VERSION ""

NS_ :

BS_:

BU_: TCM HCM IPMA_ADAS PSCM ABS_ESC TCCM TCM_DSL PCM_HEV PCM ECM_HEVDSL ECM_HEV ECM_Diesel ECM SIMA_DLCS BCMD_IPDB VDM CMR_DSMC SOBDMC_HPCM CHCM GWM _delete AWD_DLCM GENERIC TSTR

BO_ 963 BCM_Lamp_Stat_FD1: 8 BCM
 SG_ Illuminated_Entry_Stat : 63|2@0+ (1,0) [0|3] "SED"  GENERIC
 SG_ Dr_Courtesy_Light_Stat : 49|2@0+ (1,0) [0|3] "SED"  GENERIC
 SG_ Courtesy_Delay_Status : 51|2@0+ (1,0) [0|3] "SED"  GENERIC
 SG_ ImpactEvntFdbck_D_Stat : 53|2@0+ (1,0) [0|3] "SED"  CMR_DSMC
 SG_ WrlssAcsyChrgInhbt_B_Rq : 40|1@0+ (1,0) [0|1] "SED"  GENERIC
 SG_ PudLampPsngr_D_Rq : 57|2@0+ (1,0) [0|3] "SED"  GENERIC
 SG_ HeadLampLoOut_B_Stat : 32|1@0+ (1,0) [0|1] "SED"  GENERIC
 SG_ CrnrLghtRight_Pc_Rq : 47|7@0+ (1,0) [0|100] "percent"  HCM,GENERIC
 SG_ CrnrLghtLeft_Pc_Rq : 39|7@0+ (1,0) [0|100] "percent"  HCM,GENERIC
 SG_ HeadLghtHiFdbck_D_Stat : 55|2@0+ (1,0) [0|3] "SED"  GENERIC
 SG_ PudLampDrv_D_Rq : 59|2@0+ (1,0) [0|3] "SED"  GENERIC
 SG_ TrnNotInPrkChime_B_Rq : 24|1@0+ (1,0) [0|1] "SED"  GENERIC
 SG_ PrkLightChime_B_Rq : 25|1@0+ (1,0) [0|1] "SED"  GENERIC
 SG_ KeyInIgnWarn_B_Cmd : 27|1@0+ (1,0) [0|1] "SED"  GENERIC
 SG_ HomeSafeLtChime_B_Rq : 28|1@0+ (1,0) [0|1] "SED"  GENERIC
 SG_ StopLghtOn_B_Stat : 8|1@0+ (1,0) [0|1] "SED"  HCM,ABS_ESC
 SG_ RvrseLghtOn_B_Stat : 9|1@0+ (1,0) [0|1] "SED"  GENERIC
 SG_ PrkLght_D_Stat : 13|2@0+ (1,0) [0|3] "SED"  GENERIC
 SG_ HeadLghtSwtch_D_Stat : 15|2@0+ (1,0) [0|3] "SED"  HCM,IPMA_ADAS
 SG_ HeadLampLoFrOn_B_Stat : 2|1@0+ (1,0) [0|1] "SED"  HCM,IPMA_ADAS
 SG_ HeadLampLoFlOn_B_Stat : 3|1@0+ (1,0) [0|1] "SED"  HCM,IPMA_ADAS
 SG_ HeadLampLoActv_B_Stat : 4|1@0+ (1,0) [0|1] "SED"  HCM,IPMA_ADAS,PCM_HEV,PCM,ECM_HEVDSL,ECM_Diesel,ECM
 SG_ Headlamp_On_Wrning_Cmd : 29|1@0+ (1,0) [0|1] "SED"  GENERIC
 SG_ Park_Brake_Chime_Rqst : 26|1@0+ (1,0) [0|1] "SED"  GENERIC
 SG_ HeadLghtHiOn_B_Stat : 1|1@0+ (1,0) [0|1] "SED"  HCM,ECM,ECM_Diesel,ECM_HEVDSL,IPMA_ADAS,PCM,PCM_HEV
 SG_ BrkWarnInd_B_Rq : 20|1@0+ (1,0) [0|1] "SED"  GENERIC
 SG_ Brk_Fluid_Lvl_Low : 31|2@0+ (1,0) [0|3] "SED"  GENERIC
 SG_ ReducedGuard_D_Stat : 19|2@0+ (1,0) [0|3] "SED"  GENERIC
 SG_ Perimeter_Alarm_Status : 17|2@0+ (1,0) [0|3] "SED"  IPMA_ADAS,ABS_ESC
 SG_ Courtesy_BSave_Stat : 7|2@0+ (1,0) [0|3] "SED"  GENERIC
 SG_ DrTgateLck_D_Stat : 61|2@0+ (1,0) [0|3] "SED"  GENERIC
 SG_ WndwGlbl_D_Cmd : 23|3@0+ (1,0) [0|7] "SED"  GENERIC
 SG_ PudLamp_D_Rq : 11|2@0+ (1,0) [0|3] "SED"  GENERIC
 SG_ PerimeterAlarmChimeRq : 0|1@0+ (1,0) [0|1] "SED"  GENERIC
 SG_ DayRnngLampOn_B_Stat : 5|1@0+ (1,0) [0|1] "SED"  HCM

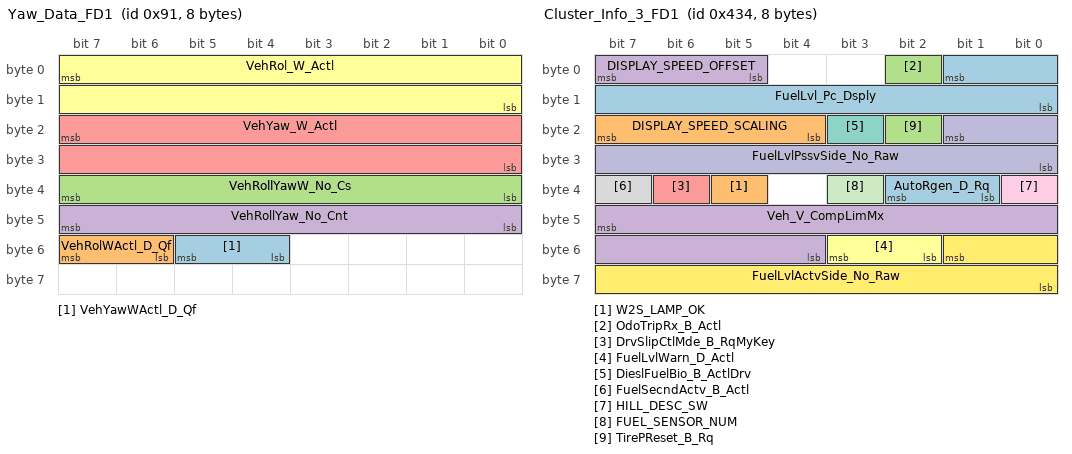
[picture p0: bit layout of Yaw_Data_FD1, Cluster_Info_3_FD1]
BO_ 145 Yaw_Data_FD1: 8 RCM
 SG_ VehYawWActl_D_Qf : 53|2@0+ (1,0) [0|3] "SED"  VDM,HCM,IPMA_ADAS,ABS_ESC
 SG_ VehRolWActl_D_Qf : 55|2@0+ (1,0) [0|3] "SED"  VDM,ABS_ESC,IPMA_ADAS
 SG_ VehRollYawW_No_Cs : 39|8@0+ (1,0) [0|255] "Unitless"  ABS_ESC,IPMA_ADAS
 SG_ VehRollYaw_No_Cnt : 47|8@0+ (1,0) [0|255] "Unitless"  VDM,ABS_ESC,IPMA_ADAS
 SG_ VehYaw_W_Actl : 23|16@0+ (0.0002,-6.5) [-6.5|6.6066] "rad/s"  VDM,HCM,ABS_ESC,PSCM,IPMA_ADAS
 SG_ VehRol_W_Actl : 7|16@0+ (0.0002,-6.5) [-6.5|6.6066] "rad/s"  VDM,ECM,ECM_Diesel,ECM_HEVDSL,PCM,PCM_HEV,ABS_ESC,IPMA_ADAS,PSCM

BO_ 76 RCMStatusMessage2_FD1: 8 RCM
 SG_ RstrnPsngrOn_D_Stat : 39|4@0+ (1,0) [0|15] "SED"  GENERIC
 SG_ PsngrFmidDetct_D_Actl : 26|2@0+ (1,0) [0|3] "SED"  GENERIC
 SG_ FirstRowBuckleMid : 28|2@0+ (1,0) [0|3] "SED"  GENERIC,IPMA_ADAS
 SG_ ThirdRowBucklePsngr : 17|2@0+ (1,0) [0|3] "SED"  GENERIC
 SG_ ThirdRowBuckleMid : 19|2@0+ (1,0) [0|3] "SED"  GENERIC
 SG_ ThirdRowBuckleDriver : 21|2@0+ (1,0) [0|3] "SED"  GENERIC
 SG_ SecondRowBucklePsngr : 23|2@0+ (1,0) [0|3] "SED"  GENERIC
 SG_ SecondRowBuckleMid : 9|2@0+ (1,0) [0|3] "SED"  GENERIC
 SG_ SecondRowBuckleDriver : 11|2@0+ (1,0) [0|3] "SED"  GENERIC
 SG_ FirstRowBuckleDriver : 15|2@0+ (1,0) [0|3] "SED"  TCM,SOBDMC_HPCM,ABS_ESC,IPMA_ADAS,ECM,ECM_Diesel,ECM_HEV,ECM_HEVDSL,PCM,PCM_HEV,TCM_DSL,CMR_DSMC
 SG_ RILReq : 7|2@0+ (1,0) [0|3] "SED"  GENERIC
 SG_ FirstRowBucklePsngr : 13|2@0+ (1,0) [0|3] "SED"  GENERIC,IPMA_ADAS
 SG_ RstrnImpactEvntStatus : 3|3@0+ (1,0) [0|7] "SED"  TCM,SOBDMC_HPCM,ABS_ESC,IPMA_ADAS,ECM,ECM_Diesel,ECM_HEV,ECM_HEVDSL,PCM,PCM_HEV,TCM_DSL,CMR_DSMC
 SG_ PsngrFrntDetct_D_Actl : 5|2@0+ (1,0) [0|3] "SED"  GENERIC
 SG_ EDRTriggerEvntSync : 29|1@0+ (1,0) [0|1] "SED"  IPMA_ADAS
 SG_ PassRstrnInd_Req : 31|2@0+ (1,0) [0|3] "SED"  GENERIC
 SG_ FirstRowBuckle_No_Cs : 47|8@0+ (1,0) [0|255] "unitless"  IPMA_ADAS,ABS_ESC
 SG_ RCMStatusMsg2_No_Cnt : 35|4@0+ (1,0) [0|15] "Unitless"  ABS_ESC,IPMA_ADAS

BO_ 65 Global_PATS_Cntrl_Info_FD1: 8 GWM
 SG_ immoControlData_T1 : 15|40@0+ (1,0) [0|1099511627775] "Encrypted"  SOBDMC_HPCM,ECM,ECM_Diesel,ECM_HEVDSL,PCM,PCM_HEV
 SG_ immoControlCmd_T1 : 7|3@0+ (1,0) [0|7] "SED"  SOBDMC_HPCM,ECM,ECM_Diesel,ECM_HEVDSL,PCM,PCM_HEV,ECM_HEV

BO_ 1076 Cluster_Info_3_FD1: 8 IPC
 SG_ AutoRgen_D_Rq : 34|2@0+ (1,0) [0|3] "SED"  ECM_Diesel,ECM_HEVDSL,ECM
 SG_ W2S_LAMP_OK : 37|1@0+ (1,0) [0|1] "SED"  ECM,ECM_Diesel,ECM_HEVDSL
 SG_ OdoTripRx_B_Actl : 2|1@0+ (1,0) [0|1] "SED"  ECM,ECM_Diesel,ECM_HEV,ECM_HEVDSL,PCM,PCM_HEV
 SG_ Veh_V_CompLimMx : 47|12@0+ (0.1,0) [0|409.5] "km/h"  ECM,ECM_Diesel,ECM_HEV,ECM_HEVDSL,PCM,PCM_HEV
 SG_ DrvSlipCtlMde_B_RqMyKey : 38|1@0+ (1,0) [0|1] "SED"  ABS_ESC
 SG_ FuelLvlWarn_D_Actl : 51|2@0+ (1,0) [0|3] "SED"  PCM,PCM_HEV
 SG_ DieslFuelBio_B_ActlDrv : 19|1@0+ (1,0) [0|1] "SED"  ECM,ECM_Diesel,ECM_HEVDSL
 SG_ FuelSecndActv_B_Actl : 39|1@0+ (1,0) [0|1] "SED"  ECM,ECM_Diesel,ECM_HEVDSL,PCM,PCM_HEV
 SG_ HILL_DESC_SW : 32|1@0+ (1,0) [0|1] "SED"  ABS_ESC
 SG_ FuelLvlPssvSide_No_Raw : 17|10@0+ (1,0) [0|1023] "Unitless"  ECM,ECM_Diesel,ECM_HEV,ECM_HEVDSL,PCM,PCM_HEV
 SG_ FUEL_SENSOR_NUM : 35|1@0+ (1,0) [0|1] "SED"  ECM,ECM_Diesel,ECM_HEV,ECM_HEVDSL,PCM,PCM_HEV
 SG_ FuelLvlActvSide_No_Raw : 49|10@0+ (1,0) [0|1023] "Unitless"  ECM,ECM_Diesel,ECM_HEV,ECM_HEVDSL,PCM,PCM_HEV
 SG_ FuelLvl_Pc_Dsply : 1|10@0+ (0.108696,-5.217408) [-5.217408|105.9786] "Percent"  VDM,ECM,ECM_Diesel,ECM_HEVDSL
 SG_ DISPLAY_SPEED_SCALING : 23|4@0+ (0.5,100) [100|107.5] "%"  IPMA_ADAS,ECM,ECM_Diesel,ECM_HEV,ECM_HEVDSL,PCM,PCM_HEV
 SG_ TirePReset_B_Rq : 18|1@0+ (1,0) [0|1] "SED"  GENERIC
 SG_ DISPLAY_SPEED_OFFSET : 7|3@0+ (0.5,0) [0|3.5] "kph"  IPMA_ADAS,ECM,ECM_Diesel,ECM_HEV,ECM_HEVDSL,PCM,PCM_HEV

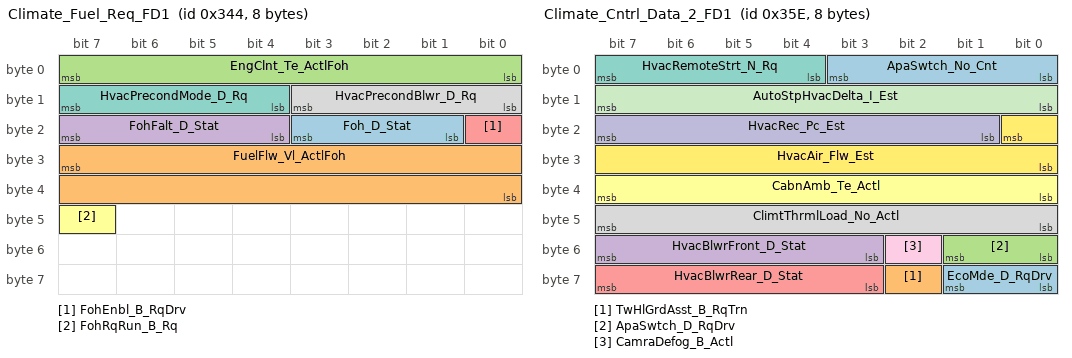
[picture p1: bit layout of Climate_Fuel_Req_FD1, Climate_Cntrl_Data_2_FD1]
BO_ 836 Climate_Fuel_Req_FD1: 8 SOBDMD_AHCM_FOH
 SG_ Foh_D_Stat : 19|3@0+ (1,0) [0|7] "SED"  ECM_Diesel,ECM_HEVDSL,PCM,PCM_HEV,ECM
 SG_ FuelFlw_Vl_ActlFoh : 31|16@0+ (25,0) [0|1638375] "microlitre"  ECM_Diesel,ECM_HEVDSL,PCM,PCM_HEV,ECM
 SG_ EngClnt_Te_ActlFoh : 7|8@0+ (1,-50) [-50|204] "degC"  ECM_Diesel,ECM_HEVDSL,PCM,PCM_HEV,ECM
 SG_ FohFalt_D_Stat : 23|4@0+ (1,0) [0|15] "SED"  ECM_Diesel,ECM_HEVDSL,PCM,PCM_HEV,ECM
 SG_ FohEnbl_B_RqDrv : 16|1@0+ (1,0) [0|1] "SED"  ECM_Diesel,ECM_HEVDSL,PCM,PCM_HEV,ECM
 SG_ FohRqRun_B_Rq : 47|1@0+ (1,0) [0|1] "SED"  ECM_Diesel,ECM_HEVDSL,PCM,PCM_HEV,ECM
 SG_ HvacPrecondMode_D_Rq : 15|4@0+ (1,0) [0|15] "SED"  GENERIC
 SG_ HvacPrecondBlwr_D_Rq : 11|4@0+ (1,0) [0|15] "SED"  GENERIC

BO_ 862 Climate_Cntrl_Data_2_FD1: 8 GWM
 SG_ EcoMde_D_RqDrv : 57|2@0+ (1,0) [0|3] "SED"  SOBDMC_HPCM,GENERIC
 SG_ TwHlGrdAsst_B_RqTrn : 58|1@0+ (1,0) [0|1] "SED"  ECM_HEV,AWD_DLCM
 SG_ ApaSwtch_D_RqDrv : 49|2@0+ (1,0) [0|3] "SED"  IPMA_ADAS
 SG_ HvacBlwrFront_D_Stat : 55|5@0+ (1,0) [0|31] "SED"  ECM_Diesel,ECM_HEV,ECM_HEVDSL,PCM,PCM_HEV,ECM
 SG_ HvacBlwrRear_D_Stat : 63|5@0+ (1,0) [0|31] "SED"  SOBDMC_HPCM,ECM_Diesel,ECM_HEV,ECM_HEVDSL,PCM,PCM_HEV,ECM
 SG_ CabnAmb_Te_Actl : 39|8@0+ (0.5,-57) [-57|70] "degreesC"  SOBDMC_HPCM,PCM,PCM_HEV
 SG_ HvacRemoteStrt_N_Rq : 7|4@0+ (100,450) [450|1950] "RPM"  ECM_Diesel,ECM_HEV,ECM_HEVDSL,PCM,PCM_HEV,ECM
 SG_ ClimtThrmlLoad_No_Actl : 47|8@0+ (1,0) [0|254] "unitless"  SOBDMC_HPCM,ECM_Diesel,ECM_HEV,ECM_HEVDSL,PCM_HEV,ECM
 SG_ CamraDefog_B_Actl : 50|1@0+ (1,0) [0|1] "SED"  GENERIC
 SG_ HvacRec_Pc_Est : 23|7@0+ (1,0) [0|127] "Percent"  SOBDMC_HPCM,PCM_HEV
 SG_ AutoStpHvacDelta_I_Est : 15|8@0+ (1,-192) [-192|62] "ampere"  GENERIC
 SG_ HvacAir_Flw_Est : 16|9@0+ (0.5,0) [0|255.5] "liter/second"  SOBDMC_HPCM,GENERIC,PCM_HEV
 SG_ ApaSwtch_No_Cnt : 3|4@0+ (1,0) [0|15] "Unitless"  GENERIC

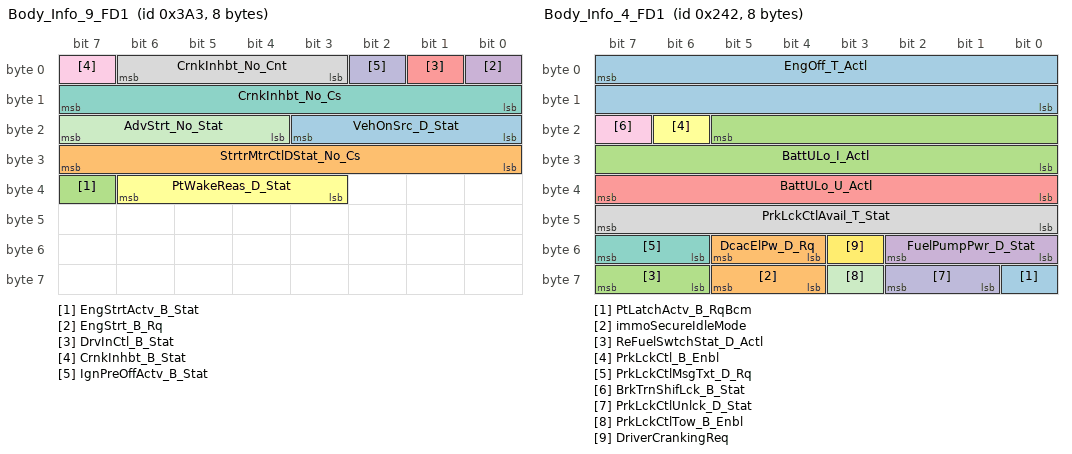
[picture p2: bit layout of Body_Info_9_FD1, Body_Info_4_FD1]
BO_ 931 Body_Info_9_FD1: 8 BCM
 SG_ VehOnSrc_D_Stat : 19|4@0+ (1,0) [0|15] "SED"  IPMA_ADAS,VDM,ECM,ECM_Diesel,ECM_HEV,ECM_HEVDSL,PCM,AWD_DLCM,TCM,TCM_DSL,SOBDMC_HPCM,ABS_ESC,PCM_HEV
 SG_ StrtrMtrCtlDStat_No_Cs : 31|8@0+ (1,0) [0|255] "unitless"  ECM,ECM_Diesel,ECM_HEV,ECM_HEVDSL,PCM,SOBDMC_HPCM,PCM_HEV
 SG_ EngStrtActv_B_Stat : 39|1@0+ (1,0) [0|1] "SED"  ECM,ECM_Diesel,ECM_HEV,ECM_HEVDSL,PCM,SOBDMC_HPCM,PCM_HEV
 SG_ EngStrt_B_Rq : 0|1@0+ (1,0) [0|1] "SED"  ECM,ECM_Diesel,ECM_HEV,ECM_HEVDSL,PCM,SOBDMC_HPCM,PCM_HEV
 SG_ DrvInCtl_B_Stat : 1|1@0+ (1,0) [0|1] "SED"  ECM,ECM_Diesel,ECM_HEV,ECM_HEVDSL,PCM,SOBDMC_HPCM,PCM_HEV
 SG_ PtWakeReas_D_Stat : 38|4@0+ (1,0) [0|15] "SED"  ECM_HEV,PCM_HEV
 SG_ CrnkInhbt_No_Cs : 15|8@0+ (1,0) [0|255] "Unitless"  ECM_Diesel,ECM_HEV,ECM_HEVDSL,PCM,PCM_HEV,ECM
 SG_ CrnkInhbt_No_Cnt : 6|4@0+ (1,0) [0|15] "Unitless"  SOBDMC_HPCM,ECM_Diesel,ECM_HEV,ECM_HEVDSL,PCM,PCM_HEV,ECM
 SG_ CrnkInhbt_B_Stat : 7|1@0+ (1,0) [0|1] "SED"  ECM_Diesel,ECM_HEV,ECM_HEVDSL,PCM,PCM_HEV,ECM,AWD_DLCM,TCM,TCM_DSL,SOBDMC_HPCM
 SG_ IgnPreOffActv_B_Stat : 2|1@0+ (1,0) [0|1] "SED"  TCM,PCM,PCM_HEV,TCM_DSL
 SG_ AdvStrt_No_Stat : 23|4@0+ (1,0) [0|15] "unitless"  SOBDMC_HPCM,ECM,ECM_Diesel,ECM_HEV,ECM_HEVDSL,PCM,PCM_HEV

BO_ 578 Body_Info_4_FD1: 8 BCM
 SG_ PtLatchActv_B_RqBcm : 56|1@0+ (1,0) [0|1] "SED"  TCM,SOBDMC_HPCM,ECM_Diesel,ECM_HEV,ECM_HEVDSL,PCM,PCM_HEV,TCM_DSL,ECM
 SG_ immoSecureIdleMode : 61|2@0+ (1,0) [0|3] "SED"  ABS_ESC,SOBDMC_HPCM,ECM_Diesel,ECM_HEVDSL,PCM,PCM_HEV,ECM,ECM_HEV
 SG_ ReFuelSwtchStat_D_Actl : 63|2@0+ (1,0) [0|3] "SED"  ECM_HEV
 SG_ FuelPumpPwr_D_Stat : 50|3@0+ (1,0) [0|7] "SED"  ECM_Diesel,ECM_HEV,ECM_HEVDSL,PCM,PCM_HEV,ECM
 SG_ BattULo_U_Actl : 39|8@0+ (0.0625,0) [0|15.875] "volt"  CMR_DSMC,TCM,SOBDMC_HPCM,CHCM,ABS_ESC,IPMA_ADAS,PSCM,ECM_Diesel,ECM_HEV,ECM_HEVDSL,PCM,PCM_HEV,TCM_DSL,ECM
 SG_ PrkLckCtl_B_Enbl : 22|1@0+ (1,0) [0|1] "SED"  TCM,ECM_Diesel,ECM_HEV,ECM_HEVDSL,PCM,PCM_HEV,TCM_DSL,ECM
 SG_ PrkLckCtlMsgTxt_D_Rq : 55|2@0+ (1,0) [0|3] "SED"  TCM,SOBDMC_HPCM,ECM_HEV,PCM,PCM_HEV,TCM_DSL
 SG_ PrkLckCtlAvail_T_Stat : 47|8@0+ (1,0) [0|255] "second"  GENERIC
 SG_ BrkTrnShifLck_B_Stat : 23|1@0+ (1,0) [0|1] "SED"  TCM,SOBDMC_HPCM,ECM_HEV,PCM,PCM_HEV,TCM_DSL
 SG_ PrkLckCtlUnlck_D_Stat : 58|2@0+ (1,0) [0|3] "SED"  GENERIC
 SG_ PrkLckCtlTow_B_Enbl : 59|1@0+ (1,0) [0|1] "SED"  GENERIC
 SG_ DriverCrankingReq : 51|1@0+ (1,0) [0|1] "SED"  ECM_Diesel,ECM_HEV,ECM_HEVDSL,PCM,PCM_HEV,ECM
 SG_ EngOff_T_Actl : 7|16@0+ (1,0) [0|65534] "second^0.5"  CHCM,TCM,ABS_ESC,IPMA_ADAS,TCCM,ECM_Diesel,ECM_HEV,ECM_HEVDSL,PCM,PCM_HEV,TCM_DSL,ECM,AWD_DLCM
 SG_ DcacElPw_D_Rq : 53|2@0+ (1,0) [0|3] "SED"  ECM_HEV,ECM_Diesel,ECM_HEVDSL,PCM,PCM_HEV,ECM
 SG_ BattULo_I_Actl : 21|14@0+ (0.0625,-512) [-512|511.875] "ampere"  SOBDMC_HPCM,ECM_Diesel,ECM_HEV,ECM_HEVDSL,PCM,PCM_HEV,ECM

BO_ 947 BodyInfo_3_FD1: 8 BCM
 SG_ ValetMode_D_Mem : 16|1@0+ (1,0) [0|1] "SED"  GENERIC
 SG_ DimmingLvlEvnt_No_Actl : 18|2@0+ (1,0) [0|3] "unitless"  GENERIC
 SG_ DrStatDrvErrCnt_B_Stat : 19|1@0+ (1,0) [0|1] "SED"  ECM_Diesel,ECM_HEV,ECM_HEVDSL,PCM,PCM_HEV,ECM
 SG_ TurnLghtRight_D_Rq : 63|2@0+ (1,0) [0|3] "SED"  HCM,IPMA_ADAS,CMR_DSMC
 SG_ TurnLghtRightOn_B_Stat : 35|1@0+ (1,0) [0|1] "SED"  GENERIC
 SG_ TurnLghtLeftOn_B_Stat : 54|1@0+ (1,0) [0|1] "SED"  GENERIC
 SG_ FogLghtRearOn_B_Stat : 1|1@0+ (1,0) [0|1] "SED"  HCM,IPMA_ADAS
 SG_ Backlit_LED_Status : 23|4@0+ (1,0) [0|15] "SED"  GENERIC
 SG_ TurnLghtLeft_D_Rq : 9|2@0+ (1,0) [0|3] "SED"  HCM,IPMA_ADAS,CMR_DSMC
 SG_ FogLghtFrontOn_B_Stat : 56|1@0+ (1,0) [0|1] "SED"  HCM,IPMA_ADAS
 SG_ IgnKeyType_D_Actl : 39|4@0+ (1,0) [0|15] "SED"  ABS_ESC,ECM,ECM_Diesel,ECM_HEV,ECM_HEVDSL,IPMA_ADAS,PCM,PCM_HEV
 SG_ Parklamp_Status : 3|2@0+ (1,0) [0|3] "SED"  HCM,IPMA_ADAS,SIMA_DLCS
 SG_ Litval : 47|8@0+ (1,0) [0|253] "SED"  HCM,IPMA_ADAS,SIMA_DLCS
 SG_ Key_In_Ignition_Stat : 11|1@0+ (1,0) [0|1] "SED"  ABS_ESC
 SG_ Ignition_Status : 7|4@0+ (1,0) [0|15] "SED"  TCM,SOBDMC_HPCM,HCM,ABS_ESC,ECM_Diesel,ECM_HEV,ECM_HEVDSL,IPMA_ADAS,PCM,PCM_HEV,PSCM,TCCM,TCM_DSL,ECM,VDM,CMR_DSMC,CHCM,BCMD_IPDB,SIMA_DLCS,AWD_DLCM
 SG_ Dimming_Lvl : 31|8@0+ (1,0) [0|253] "SED"  IPMA_ADAS,SIMA_DLCS
 SG_ Day_Night_Status : 15|2@0+ (1,0) [0|3] "SED"  ECM_Diesel,ECM_HEVDSL,IPMA_ADAS,PCM,PCM_HEV,ECM,CMR_DSMC
 SG_ Remote_Start_Status : 13|2@0+ (1,0) [0|3] "SED"  IPMA_ADAS,CMR_DSMC,ECM_HEV,BCMD_IPDB,TCM,TCM_DSL
 SG_ DrStatTgate_B_Actl : 0|1@0+ (1,0) [0|1] "SED"  ABS_ESC,IPMA_ADAS,VDM
 SG_ DrStatRr_B_Actl : 49|1@0+ (1,0) [0|1] "SED"  ABS_ESC,IPMA_ADAS,VDM
 SG_ DrStatRl_B_Actl : 48|1@0+ (1,0) [0|1] "SED"  ABS_ESC,IPMA_ADAS,VDM
 SG_ DrStatPsngr_B_Actl : 60|1@0+ (1,0) [0|1] "SED"  ABS_ESC,IPMA_ADAS,VDM,CMR_DSMC
 SG_ DrStatInnrTgate_B_Actl : 58|1@0+ (1,0) [0|1] "SED"  ABS_ESC,IPMA_ADAS,VDM
 SG_ DrStatHood_B_Actl : 59|1@0+ (1,0) [0|1] "SED"  ECM_HEV,PCM,ABS_ESC
 SG_ DrStatDrv_B_Actl : 61|1@0+ (1,0) [0|1] "SED"  TCM,ABS_ESC,ECM_Diesel,ECM_HEV,ECM_HEVDSL,IPMA_ADAS,PCM,PCM_HEV,TCCM,TCM_DSL,ECM,VDM,CMR_DSMC
 SG_ PrkBrkActv_B_Actl : 55|1@0+ (1,0) [0|1] "SED"  TCM,SOBDMC_HPCM,ABS_ESC,ECM_Diesel,ECM_HEV,ECM_HEVDSL,IPMA_ADAS,PCM,PCM_HEV,PSCM,TCCM,TCM_DSL,ECM,AWD_DLCM
 SG_ LifeCycMde_D_Actl : 53|4@0+ (1,0) [0|15] "SED"  TCM,SOBDMC_HPCM,HCM,ABS_ESC,ECM_Diesel,ECM_HEV,ECM_HEVDSL,IPMA_ADAS,PCM,PCM_HEV,PSCM,TCM_DSL,ECM,VDM,AWD_DLCM
 SG_ Delay_Accy : 57|1@0+ (1,0) [0|1] "SED"  BCMD_IPDB
 SG_ CrashEvnt_D_Stat : 34|2@0+ (1,0) [0|3] "SED"  GENERIC
 SG_ FuelPmpInhbt_B_Stat : 32|1@0+ (1,0) [0|1] "SED"  GENERIC
 SG_ BodySrvcRqd_B_Rq : 10|1@0+ (1,0) [0|1] "SED"  GENERIC

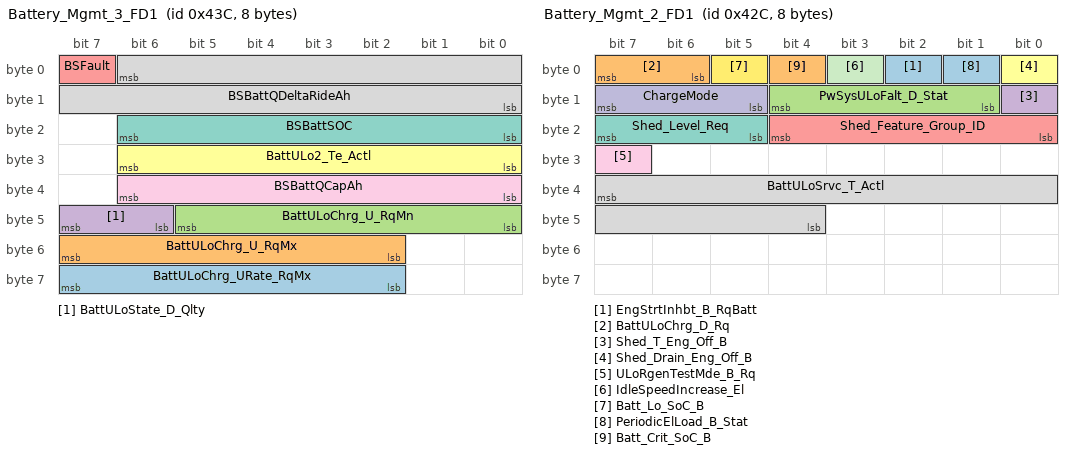
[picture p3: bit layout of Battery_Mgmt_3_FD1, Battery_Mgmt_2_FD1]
BO_ 1084 Battery_Mgmt_3_FD1: 8 BCM
 SG_ BattULoChrg_URate_RqMx : 63|6@0+ (0.1,0) [0|6.3] "volts/second"  ECM_Diesel,ECM_HEV,ECM_HEVDSL,PCM,PCM_HEV,ECM
 SG_ BattULoChrg_U_RqMx : 55|6@0+ (0.1,10.6) [10.6|16.9] "volt"  ECM_Diesel,ECM_HEV,ECM_HEVDSL,PCM,ECM,PCM_HEV
 SG_ BattULoChrg_U_RqMn : 45|6@0+ (0.1,10.6) [10.6|16.9] "volt"  ECM,ECM_Diesel,ECM_HEV,ECM_HEVDSL,PCM,PCM_HEV
 SG_ BattULoState_D_Qlty : 47|2@0+ (1,0) [0|3] "SED"  TCM,TCM_DSL,ECM_HEV,ECM,ECM_Diesel,ECM_HEVDSL,PCM,PCM_HEV
 SG_ BSFault : 7|1@0+ (1,0) [0|1] "SED"  ECM,ECM_Diesel,ECM_HEVDSL,PCM,PCM_HEV,ECM_HEV
 SG_ BattULo2_Te_Actl : 30|7@0+ (1,-40) [-40|86] "degC"  ECM,ECM_Diesel,ECM_HEV,ECM_HEVDSL,PCM,PCM_HEV,SOBDMC_HPCM
 SG_ BSBattSOC : 22|7@0+ (1,0) [0|127] "%"  TCM,TCM_DSL,ECM,ECM_Diesel,ECM_HEV,ECM_HEVDSL,PCM,PCM_HEV
 SG_ BSBattQDeltaRideAh : 6|15@0+ (0.0078125,-100) [-100|155.9921875] "ampere*hour"  ECM,ECM_Diesel,ECM_HEVDSL,PCM,PCM_HEV
 SG_ BSBattQCapAh : 38|7@0+ (1,0) [0|127] "ampere*hour"  ECM,ECM_Diesel,ECM_HEVDSL,PCM,PCM_HEV

BO_ 1068 Battery_Mgmt_2_FD1: 8 BCM
 SG_ EngStrtInhbt_B_RqBatt : 2|1@0+ (1,0) [0|1] "SED"  ECM_Diesel,ECM_HEVDSL,PCM,PCM_HEV,ECM
 SG_ BattULoChrg_D_Rq : 7|2@0+ (1,0) [0|3] "SED"  ECM_Diesel,ECM_HEVDSL,PCM,PCM_HEV,ECM
 SG_ PwSysULoFalt_D_Stat : 12|4@0+ (1,0) [0|15] "SED"  PSCM,ABS_ESC
 SG_ Shed_T_Eng_Off_B : 8|1@0+ (1,0) [0|1] "SED"  GENERIC
 SG_ Shed_Feature_Group_ID : 20|5@0+ (1,0) [0|31] "SED"  ECM_Diesel,ECM_HEV,ECM_HEVDSL,PCM,PCM_HEV,IPMA_ADAS,ECM
 SG_ Shed_Drain_Eng_Off_B : 0|1@0+ (1,0) [0|1] "SED"  GENERIC
 SG_ Shed_Level_Req : 23|3@0+ (1,0) [0|7] "SED"  ECM_Diesel,ECM_HEV,ECM_HEVDSL,PCM,PCM_HEV,ABS_ESC,IPMA_ADAS,ECM
 SG_ BattULoSrvc_T_Actl : 39|12@0+ (1,0) [0|4095] "days"  ECM_HEV
 SG_ ULoRgenTestMde_B_Rq : 31|1@0+ (1,0) [0|1] "SED"  ECM_HEV,ECM_Diesel,ECM_HEVDSL,PCM,PCM_HEV,ECM
 SG_ ChargeMode : 15|3@0+ (1,0) [0|7] "SED"  ECM_HEV,ECM_Diesel,ECM_HEVDSL,PCM,PCM_HEV,ECM
 SG_ IdleSpeedIncrease_El : 3|1@0+ (1,0) [0|1] "SED"  ECM_Diesel,ECM_HEVDSL,PCM,PCM_HEV,ECM
 SG_ Batt_Lo_SoC_B : 5|1@0+ (1,0) [0|1] "SED"  GENERIC
 SG_ PeriodicElLoad_B_Stat : 1|1@0+ (1,0) [0|1] "SED"  ECM_Diesel,ECM_HEVDSL,PCM,PCM_HEV,ECM
 SG_ Batt_Crit_SoC_B : 4|1@0+ (1,0) [0|1] "SED"  GENERIC

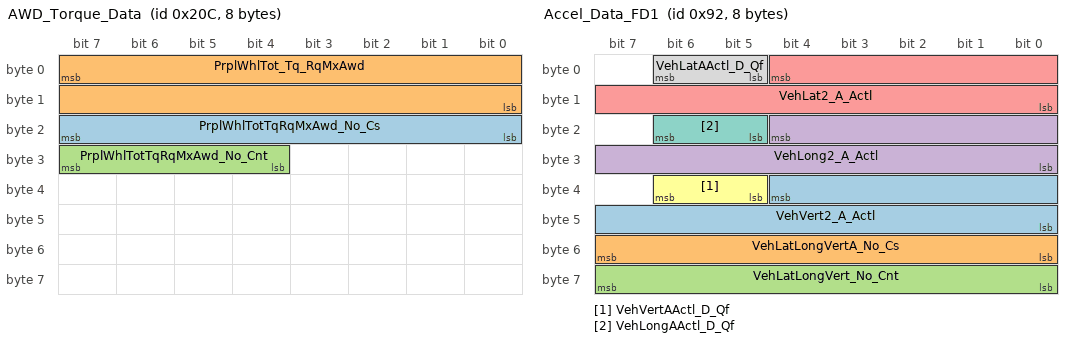
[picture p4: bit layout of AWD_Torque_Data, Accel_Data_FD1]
BO_ 524 AWD_Torque_Data: 8 AWD_DLCM
 SG_ PrplWhlTotTqRqMxAwd_No_Cs : 23|8@0+ (1,0) [0|255] "Unitless"  ECM_Diesel,ECM_HEV,ECM_HEVDSL,PCM,PCM_HEV,ECM,GWM
 SG_ PrplWhlTot_Tq_RqMxAwd : 7|16@0+ (4,-131072) [-131072|131068] "Nm"  ECM_Diesel,ECM_HEV,ECM_HEVDSL,PCM,PCM_HEV,ECM,GWM
 SG_ PrplWhlTotTqRqMxAwd_No_Cnt : 31|4@0+ (1,0) [0|15] "Unitless"  ECM_Diesel,ECM_HEV,ECM_HEVDSL,PCM,PCM_HEV,ECM,GWM

BO_ 146 Accel_Data_FD1: 8 RCM
 SG_ VehVert2_A_Actl : 36|13@0+ (0.01,-40) [-40|41.89] "m/s^2"  TCM,IPMA_ADAS,SOBDMC_HPCM,TCM_DSL,ABS_ESC,ECM_Diesel,ECM_HEV,ECM_HEVDSL,PCM,PCM_HEV,ECM,VDM,TCCM,AWD_DLCM
 SG_ VehLatLongVertA_No_Cs : 55|8@0+ (1,0) [0|255] "Unitless"  ECM_HEV,IPMA_ADAS,SOBDMC_HPCM,ABS_ESC,PSCM,TCCM,AWD_DLCM
 SG_ VehLatLongVert_No_Cnt : 63|8@0+ (1,0) [0|255] "Unitless"  ECM_HEV,IPMA_ADAS,SOBDMC_HPCM,ABS_ESC,PSCM,VDM,TCCM,AWD_DLCM
 SG_ VehLong2_A_Actl : 20|13@0+ (0.01,-40) [-40|41.89] "m/s^2"  TCM,SOBDMC_HPCM,ABS_ESC,ECM_Diesel,ECM_HEVDSL,IPMA_ADAS,TCM_DSL,ECM,VDM,ECM_HEV,TCCM,AWD_DLCM
 SG_ VehLat2_A_Actl : 4|13@0+ (0.01,-40) [-40|41.89] "m/s^2"  TCM,SOBDMC_HPCM,ABS_ESC,ECM_Diesel,ECM_HEV,ECM_HEVDSL,IPMA_ADAS,PSCM,TCM_DSL,ECM,VDM,TCCM,AWD_DLCM
 SG_ VehVertAActl_D_Qf : 38|2@0+ (1,0) [0|3] "SED"  ECM_HEV,TCM,IPMA_ADAS,SOBDMC_HPCM,ABS_ESC,PCM,PCM_HEV,TCM_DSL,VDM,TCCM,AWD_DLCM
 SG_ VehLongAActl_D_Qf : 22|2@0+ (1,0) [0|3] "SED"  SOBDMC_HPCM,IPMA_ADAS,ABS_ESC,AWD_DLCM,ECM,ECM_Diesel,ECM_HEVDSL,TCM,TCM_DSL,VDM,ECM_HEV,TCCM
 SG_ VehLatAActl_D_Qf : 6|2@0+ (1,0) [0|3] "SED"  ECM_HEV,SOBDMC_HPCM,IPMA_ADAS,ABS_ESC,AWD_DLCM,PSCM,TCM,TCM_DSL,VDM,TCCM

BO_ 1892 TesterPhysicalReqCCM: 64 TSTR
 SG_ TesterPhysicalReqCCM : 7|64@0+ (1,0) [0|1.84467E+019] "unitless"  IPMA_ADAS

BO_ 1798 TesterPhysicalReqIPMA: 64 TSTR
 SG_ TesterPhysicalReqIPMA : 7|64@0+ (1,0) [0|1.84467E+019] "unitless"  IPMA_ADAS

BO_ 1900 TesterPhysicalResCCM: 64 IPMA_ADAS
 SG_ TesterPhysicalResCCM : 7|64@0+ (1,0) [0|1.84467E+019] "unitless"  TSTR

BO_ 1806 TesterPhysicalResIPMA: 64 IPMA_ADAS
 SG_ TesterPhysicalResIPMA : 7|64@0+ (1,0) [0|1.84467E+019] "unitless"  TSTR

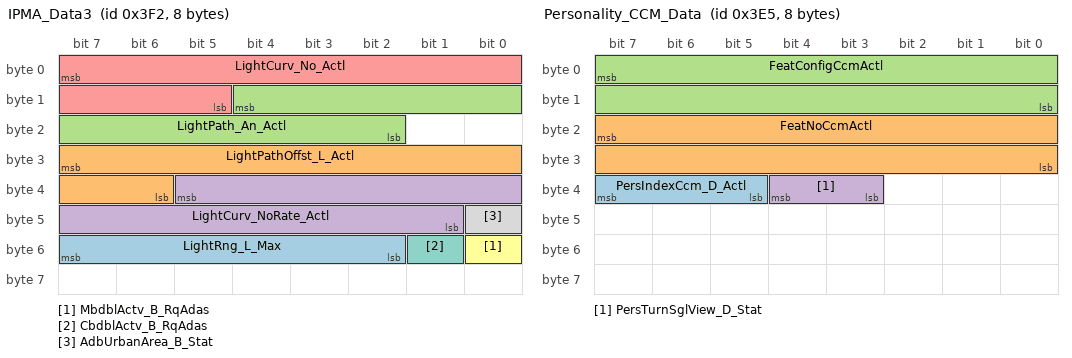
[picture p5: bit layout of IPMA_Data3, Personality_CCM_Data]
BO_ 1010 IPMA_Data3: 8 IPMA_ADAS
 SG_ LightRng_L_Max : 55|6@0+ (2,0) [0|126] "meter"  HCM,GWM
 SG_ LightPathOffst_L_Actl : 31|10@0+ (0.01,-5.12) [-5.12|5.11] "meter"  HCM,GWM
 SG_ LightPath_An_Actl : 12|11@0+ (0.0005,-0.5) [-0.5|0.5235] "radians"  HCM,GWM
 SG_ LightCurv_NoRate_Actl : 37|13@0+ (2.5E-007,-0.001024) [-0.001024|0.00102375] "1/meter"  HCM,GWM
 SG_ LightCurv_No_Actl : 7|11@0+ (2E-005,-0.02) [-0.02|0.02094] "1/meter"  HCM,GWM
 SG_ MbdblActv_B_RqAdas : 48|1@0+ (1,0) [0|1] "SED"  HCM,GWM
 SG_ CbdblActv_B_RqAdas : 49|1@0+ (1,0) [0|1] "SED"  HCM,GWM
 SG_ AdbUrbanArea_B_Stat : 40|1@0+ (1,0) [0|1] "SED"  HCM,GWM

BO_ 997 Personality_CCM_Data: 8 IPMA_ADAS
 SG_ PersIndexCcm_D_Actl : 39|3@0+ (1,0) [0|7] "SED"  GWM
 SG_ FeatNoCcmActl : 23|16@0+ (1,0) [0|65535] "Number"  GWM
 SG_ FeatConfigCcmActl : 7|16@0+ (1,0) [0|65535] "Undefined"  GWM
 SG_ PersTurnSglView_D_Stat : 36|2@0+ (1,0) [0|3] "SED"  GWM

BO_ 985 IPMA_Data2: 8 IPMA_ADAS
 SG_ LongCtrlBrk_D_Rq : 25|2@0+ (1,0) [0|3] "SED"  PCM_HEV,PCM,ECM_HEVDSL,ECM_HEV,ECM_Diesel,ECM,SOBDMC_HPCM,ABS_ESC,GWM
 SG_ LongCtrlEnblDRq_No_Cs : 63|8@0+ (1,0) [0|255] "Unitless"  SOBDMC_HPCM,ECM_HEV,GWM,ECM,PCM,ABS_ESC
 SG_ LongCtrlEnblDRq_No_Cnt : 29|4@0+ (1,0) [0|15] "Unitless"  SOBDMC_HPCM,ECM_HEV,GWM,ECM,PCM,ABS_ESC
 SG_ AdbDrvSide_B_Stat : 35|1@0+ (1,0) [0|1] "SED"  GWM,HCM
 SG_ LcwaMsgTxt_D_Stat : 37|2@0+ (1,0) [0|3] "SED"  GWM
 SG_ AdbDividedRoad_B_Stat : 30|1@0+ (1,0) [0|1] "SED"  HCM,GWM
 SG_ IsaVLimUnit_D_Rq : 15|2@0+ (1,0) [0|3] "SED"  ECM_HEV,GWM,ECM,ECM_Diesel,ECM_HEVDSL,PCM,PCM_HEV
 SG_ SblmYieldScnr_B_Stat : 31|1@0+ (1,0) [0|1] "SED"  HCM,GWM
 SG_ SblmStopScnr_B_Stat : 8|1@0+ (1,0) [0|1] "SED"  HCM,GWM
 SG_ IsaVLim_D_Rq : 7|8@0+ (1,0) [0|255] "SED"  ECM_HEV,GWM,ECM,ECM_Diesel,ECM_HEVDSL,PCM,PCM_HEV
 SG_ IaccVLimUnit_D_Rq : 11|2@0+ (1,0) [0|3] "SED"  ECM_HEV,GWM,ECM,ECM_Diesel,ECM_HEVDSL,PCM,PCM_HEV
 SG_ IaccVLim_D_Rq : 23|8@0+ (1,0) [0|255] "SED"  ECM_HEV,GWM,ECM,ECM_Diesel,ECM_HEVDSL,PCM,PCM_HEV
 SG_ DasAlrtInfo_D_Dsply : 13|2@0+ (1,0) [0|3] "SED"  GWM
 SG_ SblmRndAbtScnr_B_Stat : 9|1@0+ (1,0) [0|1] "SED"  HCM,GWM
 SG_ PwSustnAdas_B_Rq : 48|1@0+ (1,0) [0|1] "SED"  GWM,BCMD_IPDB
 SG_ ClrExitAsstMsgTxt_D_Rq : 52|4@0+ (1,0) [0|15] "SED"  GWM
 SG_ ClrExitAsstChime_D_Rq : 55|3@0+ (1,0) [0|7] "SED"  GWM
 SG_ LongCtrlEnbl_D_Rq : 42|3@0+ (1,0) [0|7] "SED"  SOBDMC_HPCM,GWM,ABS_ESC,ECM,ECM_Diesel,ECM_HEV,ECM_HEVDSL,PCM,PCM_HEV
 SG_ SblmPedCrossScnr_B_Stat : 33|1@0+ (1,0) [0|1] "SED"  GWM,HCM
 SG_ TsrRegionTxt_D_Stat : 47|5@0+ (1,0) [0|31] "SED"  GWM
 SG_ LdwChime_B_Rq : 34|1@0+ (1,0) [0|1] "SED"  GWM
 SG_ ClrExitAsst_D_Stat : 39|2@0+ (1,0) [0|3] "SED"  GWM

BO_ 984 IPMA_Data: 8 IPMA_ADAS
 SG_ DasFalt_B_Dsply : 45|1@0+ (1,0) [0|1] "SED"  GWM
 SG_ HzrdWarnLamp_B_Rq : 33|1@0+ (1,0) [0|1] "SED"  GWM
 SG_ DasWarn_D_Dsply : 44|2@0+ (1,0) [0|3] "SED"  GWM
 SG_ DasStats_D_Dsply : 47|2@0+ (1,0) [0|3] "SED"  GWM
 SG_ DasAlrtLvl_D_Dsply : 42|3@0+ (1,0) [0|7] "SED"  GWM
 SG_ CamraStats_D_Dsply : 35|2@0+ (1,0) [0|3] "SED"  GWM
 SG_ CamraDefog_B_Req : 36|1@0+ (1,0) [0|1] "SED"  GWM
 SG_ LaHandsOff_D_Dsply : 50|2@0+ (1,0) [0|3] "SED"  GWM
 SG_ LaDenyStats_B_Dsply : 32|1@0+ (1,0) [0|1] "SED"  GWM
 SG_ AhbcRampingV_D_Rq : 57|2@0+ (1,0) [0|3] "SED"  HCM,GWM
 SG_ PersIndexIpma_D_Actl : 39|3@0+ (1,0) [0|7] "SED"  GWM
 SG_ FeatNoIpmaActl : 23|16@0+ (1,0) [0|65535] "Number"  GWM
 SG_ FeatConfigIpmaActl : 7|16@0+ (1,0) [0|65535] "Undefined"  GWM
 SG_ AhbFeat_D_Stat : 63|2@0+ (1,0) [0|3] "SED"  HCM,GWM
 SG_ DsmcMsgTxt_D_Dsply : 61|2@0+ (1,0) [0|3] "SED"  GWM
 SG_ AhbHiBeam_D_Rq : 59|2@0+ (1,0) [0|3] "SED"  HCM,GWM
 SG_ LaActvStats_D2_Dsply : 55|5@0+ (1,0) [0|31] "SED"  GWM

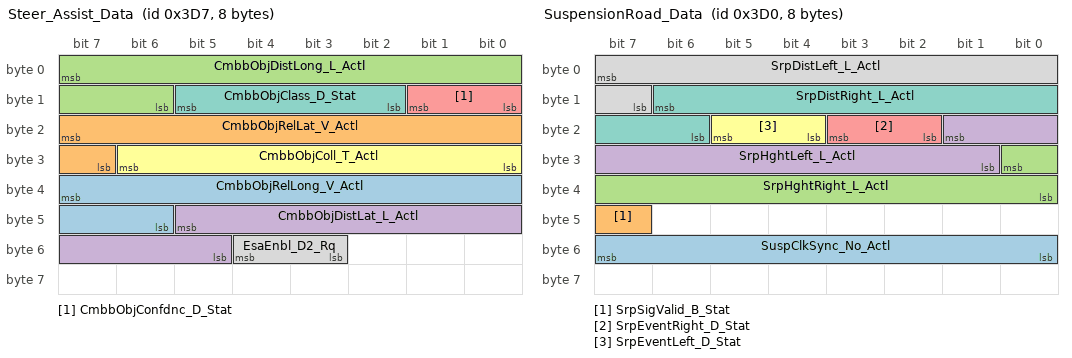
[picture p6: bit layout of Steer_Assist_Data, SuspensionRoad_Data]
BO_ 983 Steer_Assist_Data: 8 IPMA_ADAS
 SG_ CmbbObjRelLong_V_Actl : 39|10@0+ (0.1,-102.1) [-102.1|0] "meters/sec"  PSCM
 SG_ CmbbObjRelLat_V_Actl : 23|9@0+ (0.1,-25.5) [-25.5|25.4] "meters/sec"  PSCM
 SG_ CmbbObjDistLong_L_Actl : 7|10@0+ (0.1,0) [0|102.1] "meter"  PSCM
 SG_ CmbbObjDistLat_L_Actl : 45|9@0+ (0.1,-25.5) [-25.5|25.4] "meter"  PSCM
 SG_ CmbbObjConfdnc_D_Stat : 9|2@0+ (1,0) [0|3] "SED"  PSCM
 SG_ CmbbObjColl_T_Actl : 30|7@0+ (0.05,0) [0|6.25] "second"  PSCM
 SG_ CmbbObjClass_D_Stat : 13|4@0+ (1,0) [0|15] "SED"  PSCM
 SG_ EsaEnbl_D2_Rq : 52|2@0+ (1,0) [0|3] "SED"  PSCM

BO_ 976 SuspensionRoad_Data: 8 IPMA_ADAS
 SG_ SuspClkSync_No_Actl : 55|8@0+ (1,0) [0|253] "unitless"  VDM,GWM
 SG_ SrpSigValid_B_Stat : 47|1@0+ (1,0) [0|1] "SED"  VDM,GWM
 SG_ SrpHghtRight_L_Actl : 24|9@0+ (0.000625,-0.16) [-0.16|0.158125] "meter"  VDM,GWM
 SG_ SrpHghtLeft_L_Actl : 17|9@0+ (0.000625,-0.16) [-0.16|0.158125] "meter"  VDM,GWM
 SG_ SrpEventRight_D_Stat : 19|2@0+ (1,0) [0|3] "SED"  VDM,GWM
 SG_ SrpEventLeft_D_Stat : 21|2@0+ (1,0) [0|3] "SED"  VDM,GWM
 SG_ SrpDistRight_L_Actl : 14|9@0+ (0.02,0) [0|10.18] "meter"  VDM,GWM
 SG_ SrpDistLeft_L_Actl : 7|9@0+ (0.02,0) [0|10.18] "meter"  VDM,GWM

BO_ 973 Traffic_RecognitnData: 8 IPMA_ADAS
 SG_ TsrChime_D_Rq : 45|2@0+ (1,0) [0|3] "SED"  GWM
 SG_ PersCtaSplitView_D_Stat : 12|2@0+ (1,0) [0|3] "SED"  GWM
 SG_ TsrVl2PrmntMsgTxt_D_Rq : 60|2@0+ (1,0) [0|3] "SED"  GWM
 SG_ TsrVl1PrmntMsgTxt_D_Rq : 41|2@0+ (1,0) [0|3] "SED"  GWM
 SG_ TsrVl2RstrcMsgTxt2_D_Rq : 63|3@0+ (1,0) [0|7] "SED"  GWM
 SG_ TsrVl1RstrcMsgTxt2_D_Rq : 51|3@0+ (1,0) [0|7] "SED"  GWM
 SG_ TsrOvtkMsgTxt2_D_Rq : 55|4@0+ (1,0) [0|15] "SED"  GWM
 SG_ WwaWarn_B_Rq : 48|1@0+ (1,0) [0|1] "SED"  GWM
 SG_ TsrVlUnitMsgTxt_D_Rq : 43|2@0+ (1,0) [0|3] "SED"  GWM
 SG_ TsrVLim2MsgTxt_D_Rq : 39|8@0+ (1,0) [0|255] "SED"  GWM
 SG_ TsrVLim1MsgTxt_D_Rq : 31|8@0+ (1,0) [0|255] "SED"  GWM
 SG_ TsrVl2StatMsgTxt_D_Rq : 47|2@0+ (1,0) [0|3] "SED"  GWM
 SG_ TsrVl2RstrcMsgTxt_D_Rq : 17|2@0+ (1,0) [0|3] "SED"  GWM
 SG_ TsrVl1StatMsgTxt_D_Rq : 21|2@0+ (1,0) [0|3] "SED"  GWM
 SG_ TsrVl1RstrcMsgTxt_D_Rq : 23|2@0+ (1,0) [0|3] "SED"  GWM
 SG_ TsrStatMsgTxt_D_Rq : 10|3@0+ (1,0) [0|7] "SED"  GWM
 SG_ TsrOvtkStatMsgTxt_D_Rq : 1|2@0+ (1,0) [0|3] "SED"  GWM
 SG_ TsrOvtkMsgTxt_D_Rq : 15|3@0+ (1,0) [0|7] "SED"  GWM
 SG_ TsrOswWarnMsgTxt_D_Rq : 3|2@0+ (1,0) [0|3] "SED"  GWM
 SG_ TsrMsgTxt_D_Rq : 7|4@0+ (1,0) [0|15] "SED"  GWM
 SG_ LaSysOffStat_D_Dsply : 58|2@0+ (1,0) [0|3] "SED"  GWM
 SG_ RoadSignRgltry_D_Dsply : 19|2@0+ (1,0) [0|3] "SED"  GWM

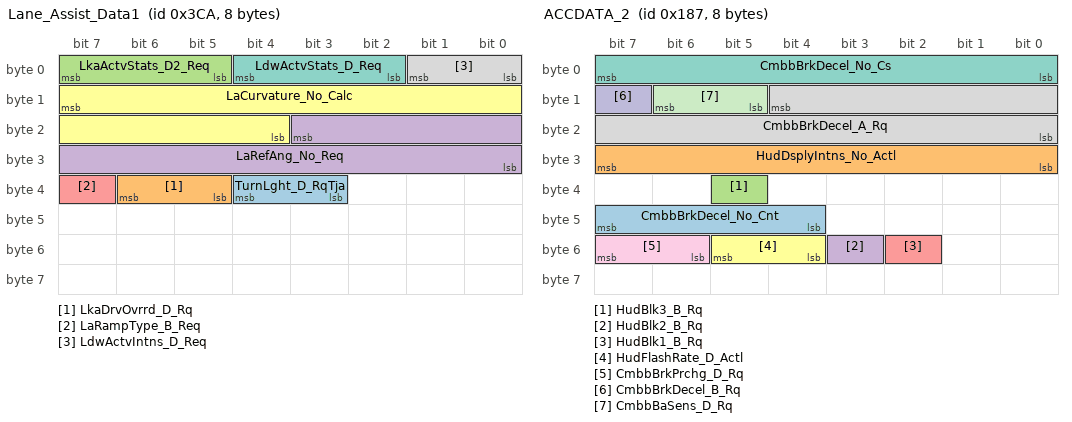
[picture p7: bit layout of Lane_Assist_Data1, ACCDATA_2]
BO_ 970 Lane_Assist_Data1: 8 IPMA_ADAS
 SG_ TurnLght_D_RqTja : 36|2@0+ (1,0) [0|3] "SED"  GWM
 SG_ LkaDrvOvrrd_D_Rq : 38|2@0+ (1,0) [0|3] "SED"  PSCM
 SG_ LkaActvStats_D2_Req : 7|3@0+ (1,0) [0|7] "SED"  PSCM
 SG_ LaRefAng_No_Req : 19|12@0+ (0.05,-102.4) [-102.4|102.3] "mrad"  PSCM
 SG_ LaRampType_B_Req : 39|1@0+ (1,0) [0|1] "SED"  PSCM
 SG_ LaCurvature_No_Calc : 15|12@0+ (5E-006,-0.01024) [-0.01024|0.01023] "1/m"  PSCM
 SG_ LdwActvStats_D_Req : 4|3@0+ (1,0) [0|7] "SED"  PSCM
 SG_ LdwActvIntns_D_Req : 1|2@0+ (1,0) [0|3] "SED"  PSCM

BO_ 394 ACCDATA_3: 8 IPMA_ADAS
 SG_ AccTrgDist2_D_Dsply : 27|4@0+ (1,0) [0|15] "SED"  GWM
 SG_ AccStopRes_B_Dsply : 54|1@0+ (1,0) [0|1] "SED"  GWM
 SG_ TjaWarn_D_Rq : 50|3@0+ (1,0) [0|7] "SED"  GWM
 SG_ Tja_D_Stat : 44|3@0+ (1,0) [0|7] "SED"  CMR_DSMC,GWM
 SG_ TjaMsgTxt_D_Dsply : 53|3@0+ (1,0) [0|7] "SED"  GWM
 SG_ IaccLamp_D_Rq : 46|2@0+ (1,0) [0|3] "SED"  GWM
 SG_ AccMsgTxt_D2_Rq : 31|4@0+ (1,0) [0|15] "SED"  GWM
 SG_ FcwDeny_B_Dsply : 10|1@0+ (1,0) [0|1] "SED"  GWM
 SG_ FcwMemStat_B_Actl : 13|1@0+ (1,0) [0|1] "SED"  GWM
 SG_ AccTGap_B_Dsply : 35|1@0+ (1,0) [0|1] "SED"  GWM
 SG_ CadsAlignIncplt_B_Actl : 11|1@0+ (1,0) [0|1] "SED"  GWM
 SG_ AccFllwMde_B_Dsply : 17|1@0+ (1,0) [0|1] "SED"  GWM
 SG_ CadsRadrBlck_B_Actl : 22|1@0+ (1,0) [0|1] "SED"  GWM
 SG_ CmbbPostEvnt_B_Dsply : 15|1@0+ (1,0) [0|1] "SED"  GWM
 SG_ AccStopMde_B_Dsply : 0|1@0+ (1,0) [0|1] "SED"  GWM
 SG_ FcwMemSens_D_Actl : 20|2@0+ (1,0) [0|3] "SED"  GWM
 SG_ FcwMsgTxt_D_Rq : 7|3@0+ (1,0) [0|7] "SED"  GWM
 SG_ AccWarn_D_Dsply : 39|2@0+ (1,0) [0|3] "SED"  GWM
 SG_ FcwVisblWarn_B_Rq : 47|1@0+ (1,0) [0|1] "SED"  GWM
 SG_ FcwAudioWarn_B_Rq : 8|1@0+ (1,0) [0|1] "SED"  GWM
 SG_ AccTGap_D_Dsply : 34|3@0+ (1,0) [0|7] "SED"  GWM
 SG_ AccMemEnbl_B_RqDrv : 36|1@0+ (1,0) [0|1] "SED"  GWM
 SG_ AccStopStat_D_Dsply : 41|2@0+ (1,0) [0|3] "SED"  GWM
 SG_ HaDsply_No_Cs : 63|8@0+ (1,0) [0|255] "Unitless"  GWM
 SG_ HaDsply_No_Cnt : 4|4@0+ (1,0) [0|15] "Unitless"  GWM

BO_ 391 ACCDATA_2: 8 IPMA_ADAS
 SG_ CmbbBrkDecel_No_Cnt : 47|4@0+ (1,0) [0|15] "Unitless"  ABS_ESC
 SG_ HudDsplyIntns_No_Actl : 31|8@0+ (0.5,0) [0|100] "%"  GWM
 SG_ HudBlk3_B_Rq : 37|1@0+ (1,0) [0|1] "SED"  GWM
 SG_ HudBlk2_B_Rq : 51|1@0+ (1,0) [0|1] "SED"  GWM
 SG_ HudBlk1_B_Rq : 50|1@0+ (1,0) [0|1] "SED"  GWM
 SG_ HudFlashRate_D_Actl : 53|2@0+ (1,0) [0|3] "SED"  GWM
 SG_ CmbbBrkDecel_No_Cs : 7|8@0+ (1,0) [0|255] "Unitless"  ABS_ESC
 SG_ CmbbBrkDecel_A_Rq : 12|13@0+ (0.0039,-20) [-20|11.9449] "m/s^2"  ABS_ESC,GWM
 SG_ CmbbBrkPrchg_D_Rq : 55|2@0+ (1,0) [0|3] "SED"  ABS_ESC,GWM
 SG_ CmbbBrkDecel_B_Rq : 15|1@0+ (1,0) [0|1] "SED"  ABS_ESC,GWM,CMR_DSMC
 SG_ CmbbBaSens_D_Rq : 14|2@0+ (1,0) [0|3] "SED"  ABS_ESC,GWM

BO_ 390 ACCDATA: 8 IPMA_ADAS
 SG_ AccBrkTot_A_Rq : 4|13@0+ (0.0039,-20) [-20|11.9449] "m/s^2"  ABS_ESC
 SG_ AccPrpl_A_Pred : 17|10@0+ (0.01,-5) [-5|5.23] "m/s^2"  ECM,ECM_Diesel,ECM_HEV,ECM_HEVDSL,PCM,PCM_HEV
 SG_ AccVeh_V_Trg : 32|9@0+ (0.5,0) [0|255.5] "kph"  ECM_HEV,TCM,ECM,ECM_Diesel,ECM_HEVDSL,PCM,PCM_HEV,TCM_DSL
 SG_ AccBrkPrkEl_B_Rq : 38|1@0+ (1,0) [0|1] "SED"  ABS_ESC
 SG_ Cmbb_B_Enbl : 50|1@0+ (1,0) [0|1] "SED"  GWM
 SG_ CmbbOvrrd_B_RqDrv : 51|1@0+ (1,0) [0|1] "SED"  GWM
 SG_ CmbbDeny_B_Actl : 37|1@0+ (1,0) [0|1] "SED"  SOBDMC_HPCM,GWM,ABS_ESC
 SG_ CmbbEngTqMn_B_Rq : 52|1@0+ (1,0) [0|1] "SED"  SOBDMC_HPCM,ECM,ECM_Diesel,ECM_HEV,ECM_HEVDSL,PCM,PCM_HEV,GWM
 SG_ AccPrpl_A_Rq : 49|10@0+ (0.01,-5) [-5|5.23] "m/s^2"  ECM,ECM_Diesel,ECM_HEV,ECM_HEVDSL,PCM,PCM_HEV
 SG_ AccDeny_B_Rq : 53|1@0+ (1,0) [0|1] "SED"  ECM,ECM_Diesel,ECM_HEV,ECM_HEVDSL,PCM,PCM_HEV
 SG_ AccResumEnbl_B_Rq : 33|1@0+ (1,0) [0|1] "SED"  ECM,ECM_Diesel,ECM_HEV,ECM_HEVDSL,PCM,PCM_HEV
 SG_ AccCancl_B_Rq : 39|1@0+ (1,0) [0|1] "SED"  ABS_ESC,ECM,ECM_Diesel,ECM_HEV,ECM_HEVDSL,PCM,PCM_HEV
 SG_ AccBrkPrchg_B_Rq : 54|1@0+ (1,0) [0|1] "SED"  ABS_ESC
 SG_ AccBrkDecel_B_Rq : 55|1@0+ (1,0) [0|1] "SED"  ABS_ESC
 SG_ AccStopStat_B_Rq : 34|1@0+ (1,0) [0|1] "SED"  ECM,ECM_Diesel,ECM_HEV,ECM_HEVDSL,PCM,PCM_HEV,ABS_ESC
 SG_ AccAutoResum_D_Rq : 7|2@0+ (1,0) [0|3] "SED"  ECM,ECM_Diesel,ECM_HEV,ECM_HEVDSL,PCM,PCM_HEV
 SG_ AccBrkPulse_B_Rq : 36|1@0+ (1,0) [0|1] "SED"  GWM,ABS_ESC

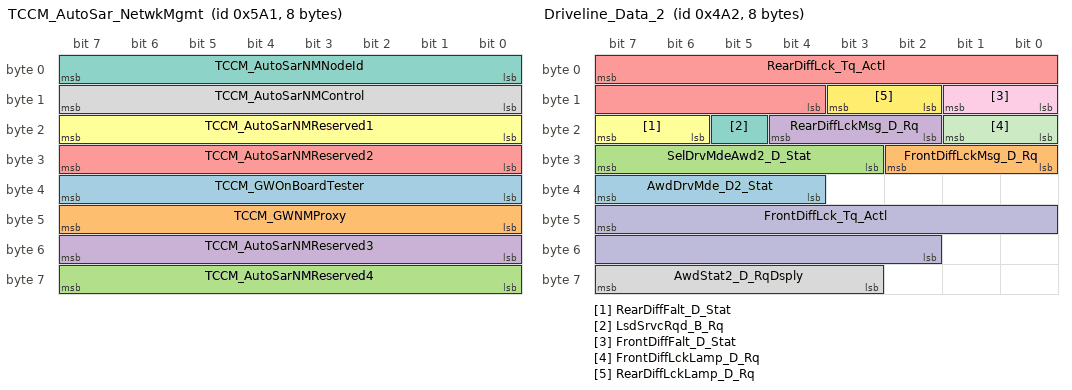
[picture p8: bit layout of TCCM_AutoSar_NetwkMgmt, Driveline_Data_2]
BO_ 1441 TCCM_AutoSar_NetwkMgmt: 8 TCCM
 SG_ TCCM_GWOnBoardTester : 39|8@0+ (1,0) [0|255] "unitless"  GENERIC
 SG_ TCCM_GWNMProxy : 47|8@0+ (1,0) [0|255] "unitless"  GENERIC
 SG_ TCCM_AutoSarNMReserved4 : 63|8@0+ (1,0) [0|255] "unitless"  GENERIC
 SG_ TCCM_AutoSarNMReserved3 : 55|8@0+ (1,0) [0|255] "unitless"  GENERIC
 SG_ TCCM_AutoSarNMReserved2 : 31|8@0+ (1,0) [0|255] "unitless"  GENERIC
 SG_ TCCM_AutoSarNMReserved1 : 23|8@0+ (1,0) [0|255] "unitless"  GENERIC
 SG_ TCCM_AutoSarNMNodeId : 7|8@0+ (1,0) [0|255] "unitless"  GENERIC
 SG_ TCCM_AutoSarNMControl : 15|8@0+ (1,0) [0|255] "unitless"  GENERIC

BO_ 1186 Driveline_Data_2: 8 PCM
 SG_ AwdDrvMde_D2_Stat : 39|4@0+ (1,0) [0|15] "SED"  GWM
 SG_ FrontDiffLckMsg_D_Rq : 26|3@0+ (1,0) [0|7] "SED"  GWM
 SG_ SelDrvMdeAwd2_D_Stat : 31|5@0+ (1,0) [0|31] "SED"  ABS_ESC,GWM
 SG_ RearDiffLckMsg_D_Rq : 20|3@0+ (1,0) [0|7] "SED"  GWM
 SG_ RearDiffLck_Tq_Actl : 7|12@0+ (1,0) [0|4093] "Nm"  ABS_ESC,ECM,ECM_Diesel,ECM_HEVDSL,PCM,PCM_HEV,GWM
 SG_ RearDiffFalt_D_Stat : 23|2@0+ (1,0) [0|3] "SED"  ABS_ESC,GWM
 SG_ LsdSrvcRqd_B_Rq : 21|1@0+ (1,0) [0|1] "SED"  GWM
 SG_ AwdStat2_D_RqDsply : 63|5@0+ (1,0) [0|31] "SED"  GWM,AWD_DLCM
 SG_ FrontDiffFalt_D_Stat : 9|2@0+ (1,0) [0|3] "SED"  ABS_ESC,GWM
 SG_ FrontDiffLck_Tq_Actl : 47|14@0+ (1,0) [0|16381] "Nm"  ABS_ESC,GWM
 SG_ FrontDiffLckLamp_D_Rq : 17|2@0+ (1,0) [0|3] "SED"  GWM,ABS_ESC,SIMA_DLCS
 SG_ RearDiffLckLamp_D_Rq : 11|2@0+ (1,0) [0|3] "SED"  ABS_ESC,GWM,SIMA_DLCS,VDM

BO_TX_BU_ 524 : TCCM,AWD_DLCM;
BO_TX_BU_ 1186 : AWD_DLCM,TCCM,SOBDMC_HPCM,ECM_Diesel,ECM,PCM;
CM_ BO_ 65 "Provide control function information to the target function of the Passive Anti-Theft Subsystem";
CM_ SG_ 836 Foh_D_Stat "Signal not transmitted on vehicles that do not have the Fuel operated heater feature.";
CM_ SG_ 836 FuelFlw_Vl_ActlFoh "Signal not transmitted on vehicles that do not have the Fuel operated heater feature.";
CM_ SG_ 836 EngClnt_Te_ActlFoh "Signal not transmitted on vehicles that do not have the Fuel operated heater feature.";
CM_ SG_ 836 FohFalt_D_Stat "Signal not transmitted on vehicles that do not have the Fuel operated heater feature.";
CM_ SG_ 836 FohEnbl_B_RqDrv "Signal not transmitted on vehicles that do not have the Fuel operated heater feature.";
CM_ SG_ 836 FohRqRun_B_Rq "Signal not transmitted on vehicles that do not have the Fuel operated heater feature.";
CM_ SG_ 836 HvacPrecondMode_D_Rq "Signal not transmitted on vehicles that do not have the Fuel operated heater feature.";
CM_ SG_ 836 HvacPrecondBlwr_D_Rq "Signal not transmitted on vehicles that do not have the Fuel operated heater feature.";
CM_ SG_ 931 CrnkInhbt_No_Cs "Signal not transmitted on gas and HEV variants.";
CM_ SG_ 931 CrnkInhbt_No_Cnt "Signal not transmitted on gas and HEV variants.";
CM_ SG_ 947 Dimming_Lvl "Refer to Vehicle Interior Illum Dimming Ctrl Sys Eng Spec, Table 2

";
CM_ SG_ 947 PrkBrkActv_B_Actl "Signal not transmitted on vehicles with electric park brake. ";
CM_ BO_ 524 "Requires b/w evaluation on each program for faster rate, requires Core Netcom and Netcom App. for approval.";
CM_ SG_ 524 PrplWhlTotTqRqMxAwd_No_Cs "Signal not transmitted on gas variants.";
CM_ SG_ 524 PrplWhlTotTqRqMxAwd_No_Cnt "Signal not transmitted on gas variants.";
CM_ SG_ 985 LongCtrlEnblDRq_No_Cs "Signal not transmitted on gas and diesel variants.";
CM_ SG_ 985 LongCtrlEnblDRq_No_Cnt "Signal not transmitted on gas and diesel variants.";
CM_ SG_ 394 HaDsply_No_Cs "Signal not transmitted on gas variants.";
CM_ SG_ 394 HaDsply_No_Cnt "Signal not transmitted on gas variants.";
CM_ SG_ 390 AccPrpl_A_Rq "PCMGenSigTimeoutTime=1000";
BA_DEF_ BO_  "VFrameFormat" ENUM  "StandardCAN","ExtendedCAN","reserved","reserved","reserved","reserved","reserved","reserved","reserved","reserved","reserved","reserved","reserved","reserved","StandardCAN_FD","ExtendedCAN_FD";
BA_DEF_ SG_  "GenSigSendType" ENUM  "Cyclic","OnWrite","vector_leerstring","OnChange","vector_leerstring","IfActive","vector_leerstring","NoSigSendType";
BA_DEF_ SG_  "GenSigInactiveValue" INT 0 100000;
BA_DEF_ SG_  "WakeupSignal" ENUM  "No","Yes";
BA_DEF_ SG_  "UsedOnPgmDBC" ENUM  "No","Yes";
BA_DEF_ SG_  "GenSigStartValueInteger" INT 0 1000000000;
BA_DEF_ SG_  "ContentDependant" ENUM  "No","Yes";
BA_DEF_ SG_  "MetaData" ENUM  "No","Yes";
BA_DEF_ SG_  "GenSigStartValue" HEX 0 268435455;
BA_DEF_ SG_  "U_CX727_MY2021_Rx" ENUM  "No","Yes";
BA_DEF_ SG_  "U_P702_MY2021_Rx" ENUM  "No","Yes";
BA_DEF_ SG_  "U_T6_MCA_MY2020_Rx" ENUM  "No","Yes";
BA_DEF_ SG_  "ECGUsedRxSignal" ENUM  "No","Yes";
BA_DEF_ SG_  "U_CD542_MY2021_Rx" ENUM  "No","Yes";
BA_DEF_ SG_  "U_U55X_MY2022_Rx" ENUM  "No","Yes";
BA_DEF_ SG_  "U_CD764_MY2022_Rx" ENUM  "No","Yes";
BA_DEF_ SG_  "U_CDX706_MY2023_Rx" ENUM  "No","Yes";
BA_DEF_ SG_  "U_CX727_MY2021_Tx" ENUM  "No","Yes";
BA_DEF_ SG_  "U_P702_MY2021_Tx" ENUM  "No","Yes";
BA_DEF_ SG_  "U_T6_MCA_MY2020_Tx" ENUM  "No","Yes";
BA_DEF_ SG_  "ECGUsedTxSignal" ENUM  "No","Yes";
BA_DEF_ SG_  "U_CD542_MY2021_Tx" ENUM  "No","Yes";
BA_DEF_ SG_  "U_U55X_MY2022_Tx" ENUM  "No","Yes";
BA_DEF_ SG_  "U_CD764_MY2022_Tx" ENUM  "No","Yes";
BA_DEF_ SG_  "U_CDX706_MY2023_Tx" ENUM  "No","Yes";
BA_DEF_ BO_  "GenMsgILSupport" ENUM  "No","Yes";
BA_DEF_ BO_  "DiagResponse" ENUM  "No","Yes";
BA_DEF_ BO_  "DiagRequest" ENUM  "No","Yes";
BA_DEF_ BO_  "TpTxIndex" INT 0 536870911;
BA_DEF_ BO_  "DiagState" ENUM  "No","Yes";
BA_DEF_ BO_  "TpApplType" STRING ;
BA_DEF_ BO_  "NmAsrMessage" ENUM  "No","Yes";
BA_DEF_ BO_  "ProgBWConditional" STRING ;
BA_DEF_ BO_  "SCP_AuthInfoTxLength" INT 0 512;
BA_DEF_ BO_  "SCP_FreshnessValueTxLength" INT 0 512;
BA_DEF_ BO_  "SCP_FreshnessValueLength" INT 0 512;
BA_DEF_ BO_  "OvtpPushApplication" ENUM  "FALSE","TRUE";
BA_DEF_ BO_  "GenMsgSendType" ENUM  "FixedPeriodic","Event","EnabledPeriodic","NotUsed","NotUsed","EventPeriodic","NotUsed","NotUsed","NoMsgSendType";
BA_DEF_ BO_  "GenMsgCycleTime" INT 0 100000;
BA_DEF_ BO_  "GenMsgDelayTime" INT 0 1000;
BA_DEF_ BO_  "GenMsgNrOfRepetition" INT 0 100;
BA_DEF_ BO_  "GenMsgStartDelayTime" INT 0 10000;
BA_DEF_ BO_  "EventRateOfChange" INT 10 10000;
BA_DEF_ BO_  "FrameGatewayId" HEX 0 1407;
BA_DEF_ BO_  "NetworkInitialization" ENUM  "No","Yes";
BA_DEF_ BO_  "FrameGatewayNetwork" STRING ;
BA_DEF_ BO_  "FrameRouting" STRING ;
BA_DEF_DEF_  "VFrameFormat" "ExtendedCAN_FD";
BA_DEF_DEF_  "GenSigSendType" "NoSigSendType";
BA_DEF_DEF_  "GenSigInactiveValue" 0;
BA_DEF_DEF_  "WakeupSignal" "No";
BA_DEF_DEF_  "UsedOnPgmDBC" "Yes";
BA_DEF_DEF_  "GenSigStartValueInteger" 0;
BA_DEF_DEF_  "ContentDependant" "No";
BA_DEF_DEF_  "MetaData" "No";
BA_DEF_DEF_  "GenSigStartValue" 0;
BA_DEF_DEF_  "U_CX727_MY2021_Rx" "No";
BA_DEF_DEF_  "U_P702_MY2021_Rx" "No";
BA_DEF_DEF_  "U_T6_MCA_MY2020_Rx" "No";
BA_DEF_DEF_  "ECGUsedRxSignal" "No";
BA_DEF_DEF_  "U_CD542_MY2021_Rx" "No";
BA_DEF_DEF_  "U_U55X_MY2022_Rx" "No";
BA_DEF_DEF_  "U_CD764_MY2022_Rx" "No";
BA_DEF_DEF_  "U_CDX706_MY2023_Rx" "No";
BA_DEF_DEF_  "U_CX727_MY2021_Tx" "No";
BA_DEF_DEF_  "U_P702_MY2021_Tx" "No";
BA_DEF_DEF_  "U_T6_MCA_MY2020_Tx" "No";
BA_DEF_DEF_  "ECGUsedTxSignal" "No";
BA_DEF_DEF_  "U_CD542_MY2021_Tx" "No";
BA_DEF_DEF_  "U_U55X_MY2022_Tx" "No";
BA_DEF_DEF_  "U_CD764_MY2022_Tx" "No";
BA_DEF_DEF_  "U_CDX706_MY2023_Tx" "No";
BA_DEF_DEF_  "GenMsgILSupport" "Yes";
BA_DEF_DEF_  "DiagResponse" "No";
BA_DEF_DEF_  "DiagRequest" "No";
BA_DEF_DEF_  "TpTxIndex" 0;
BA_DEF_DEF_  "DiagState" "No";
BA_DEF_DEF_  "TpApplType" "";
BA_DEF_DEF_  "NmAsrMessage" "No";
BA_DEF_DEF_  "ProgBWConditional" "NONE";
BA_DEF_DEF_  "SCP_AuthInfoTxLength" 53;
BA_DEF_DEF_  "SCP_FreshnessValueTxLength" 11;
BA_DEF_DEF_  "SCP_FreshnessValueLength" 64;
BA_DEF_DEF_  "OvtpPushApplication" "FALSE";
BA_DEF_DEF_  "GenMsgSendType" "NoMsgSendType";
BA_DEF_DEF_  "GenMsgCycleTime" 0;
BA_DEF_DEF_  "GenMsgDelayTime" 20;
BA_DEF_DEF_  "GenMsgNrOfRepetition" 1;
BA_DEF_DEF_  "GenMsgStartDelayTime" 0;
BA_DEF_DEF_  "EventRateOfChange" 10000;
BA_DEF_DEF_  "FrameGatewayId" 0;
BA_DEF_DEF_  "NetworkInitialization" "Yes";
BA_DEF_DEF_  "FrameGatewayNetwork" "NONE";
BA_DEF_DEF_  "FrameRouting" "";
BA_ "GenMsgSendType" BO_ 963 5;
BA_ "GenMsgCycleTime" BO_ 963 1000;
BA_ "GenMsgSendType" BO_ 145 0;
BA_ "GenMsgCycleTime" BO_ 145 10;
BA_ "GenMsgSendType" BO_ 76 5;
BA_ "GenMsgCycleTime" BO_ 76 100;
BA_ "GenMsgSendType" BO_ 1076 5;
BA_ "GenMsgCycleTime" BO_ 1076 100;
BA_ "GenMsgSendType" BO_ 836 0;
BA_ "GenMsgCycleTime" BO_ 836 1000;
BA_ "GenMsgSendType" BO_ 931 0;
BA_ "GenMsgCycleTime" BO_ 931 60;
BA_ "GenMsgSendType" BO_ 578 0;
BA_ "GenMsgCycleTime" BO_ 578 40;
BA_ "GenMsgSendType" BO_ 947 5;
BA_ "GenMsgCycleTime" BO_ 947 500;
BA_ "GenMsgSendType" BO_ 1084 0;
BA_ "GenMsgCycleTime" BO_ 1084 1000;
BA_ "GenMsgSendType" BO_ 1068 0;
BA_ "GenMsgCycleTime" BO_ 1068 50;
BA_ "GenMsgSendType" BO_ 146 0;
BA_ "GenMsgCycleTime" BO_ 146 10;
BA_ "FrameGatewayId" BO_ 963 963;
BA_ "FrameGatewayNetwork" BO_ 963 "HS1_CAN";
BA_ "FrameRouting" BO_ 963 "HS1_CAN,0x3C3;";
BA_ "VFrameFormat" BO_ 963 14;
BA_ "FrameGatewayId" BO_ 145 145;
BA_ "FrameGatewayNetwork" BO_ 145 "HS2_CAN";
BA_ "FrameRouting" BO_ 145 "HS2_CAN,0x91;";
BA_ "VFrameFormat" BO_ 145 14;
BA_ "FrameGatewayId" BO_ 76 76;
BA_ "FrameGatewayNetwork" BO_ 76 "HS2_CAN";
BA_ "FrameRouting" BO_ 76 "HS2_CAN,0x4C;";
BA_ "VFrameFormat" BO_ 76 14;
BA_ "FrameGatewayId" BO_ 65 65;
BA_ "FrameGatewayNetwork" BO_ 65 "HS1_CAN";
BA_ "FrameRouting" BO_ 65 "HS1_CAN,0x41;";
BA_ "VFrameFormat" BO_ 65 14;
BA_ "FrameGatewayId" BO_ 1076 1076;
BA_ "FrameGatewayNetwork" BO_ 1076 "HS3_CAN";
BA_ "FrameRouting" BO_ 1076 "HS3_CAN,0x434;";
BA_ "VFrameFormat" BO_ 1076 14;
BA_ "FrameGatewayId" BO_ 836 836;
BA_ "FrameGatewayNetwork" BO_ 836 "MS1_CAN";
BA_ "FrameRouting" BO_ 836 "MS1_CAN,0x344;";
BA_ "VFrameFormat" BO_ 836 14;
BA_ "FrameGatewayId" BO_ 862 862;
BA_ "FrameGatewayNetwork" BO_ 862 "MS1_CAN";
BA_ "FrameRouting" BO_ 862 "MS1_CAN,0x35E;";
BA_ "VFrameFormat" BO_ 862 14;
BA_ "FrameGatewayId" BO_ 931 931;
BA_ "FrameGatewayNetwork" BO_ 931 "HS1_CAN";
BA_ "FrameRouting" BO_ 931 "HS1_CAN,0x3A3;";
BA_ "VFrameFormat" BO_ 931 14;
BA_ "FrameGatewayId" BO_ 578 578;
BA_ "FrameGatewayNetwork" BO_ 578 "HS1_CAN";
BA_ "FrameRouting" BO_ 578 "HS1_CAN,0x242;";
BA_ "VFrameFormat" BO_ 578 14;
BA_ "FrameGatewayId" BO_ 947 947;
BA_ "FrameGatewayNetwork" BO_ 947 "HS1_CAN";
BA_ "FrameRouting" BO_ 947 "HS1_CAN,0x3B3;";
BA_ "VFrameFormat" BO_ 947 14;
BA_ "FrameGatewayId" BO_ 1084 1084;
BA_ "FrameGatewayNetwork" BO_ 1084 "HS1_CAN";
BA_ "FrameRouting" BO_ 1084 "HS1_CAN,0x43C;";
BA_ "VFrameFormat" BO_ 1084 14;
BA_ "FrameGatewayId" BO_ 1068 1068;
BA_ "FrameGatewayNetwork" BO_ 1068 "HS1_CAN";
BA_ "FrameRouting" BO_ 1068 "HS1_CAN,0x42C;";
BA_ "VFrameFormat" BO_ 1068 14;
BA_ "ProgBWConditional" BO_ 524 "MSGDCR1008_CX48X_V03_HS1D_56.84_mHEV_54.89";
BA_ "GenMsgSendType" BO_ 524 0;
BA_ "GenMsgCycleTime" BO_ 524 10;
BA_ "GenMsgDelayTime" BO_ 524 0;
BA_ "VFrameFormat" BO_ 524 14;
BA_ "FrameGatewayId" BO_ 146 146;
BA_ "FrameGatewayNetwork" BO_ 146 "HS2_CAN";
BA_ "FrameRouting" BO_ 146 "HS2_CAN,0x92;";
BA_ "VFrameFormat" BO_ 146 14;
BA_ "GenMsgILSupport" BO_ 1892 0;
BA_ "DiagRequest" BO_ 1892 1;
BA_ "GenMsgSendType" BO_ 1892 1;
BA_ "GenMsgDelayTime" BO_ 1892 0;
BA_ "NetworkInitialization" BO_ 1892 0;
BA_ "VFrameFormat" BO_ 1892 14;
BA_ "GenMsgILSupport" BO_ 1798 0;
BA_ "DiagRequest" BO_ 1798 1;
BA_ "GenMsgSendType" BO_ 1798 1;
BA_ "GenMsgDelayTime" BO_ 1798 0;
BA_ "NetworkInitialization" BO_ 1798 0;
BA_ "VFrameFormat" BO_ 1798 14;
BA_ "GenMsgILSupport" BO_ 1900 0;
BA_ "DiagResponse" BO_ 1900 1;
BA_ "GenMsgSendType" BO_ 1900 1;
BA_ "GenMsgDelayTime" BO_ 1900 0;
BA_ "NetworkInitialization" BO_ 1900 0;
BA_ "VFrameFormat" BO_ 1900 14;
BA_ "GenMsgILSupport" BO_ 1806 0;
BA_ "DiagResponse" BO_ 1806 1;
BA_ "GenMsgSendType" BO_ 1806 1;
BA_ "GenMsgDelayTime" BO_ 1806 0;
BA_ "NetworkInitialization" BO_ 1806 0;
BA_ "VFrameFormat" BO_ 1806 14;
BA_ "GenMsgSendType" BO_ 1010 0;
BA_ "GenMsgCycleTime" BO_ 1010 50;
BA_ "FrameRouting" BO_ 1010 "FD1_CAN,0x3F2;HS2_CAN,0x3F2";
BA_ "VFrameFormat" BO_ 1010 14;
BA_ "GenMsgSendType" BO_ 997 5;
BA_ "GenMsgCycleTime" BO_ 997 1000;
BA_ "FrameRouting" BO_ 997 "FD1_CAN,0x3E5;HS2_CAN,0x3E5";
BA_ "VFrameFormat" BO_ 997 14;
BA_ "GenMsgSendType" BO_ 985 5;
BA_ "GenMsgCycleTime" BO_ 985 60;
BA_ "FrameRouting" BO_ 985 "FD1_CAN,0x3D9;HS2_CAN,0x3D9";
BA_ "VFrameFormat" BO_ 985 14;
BA_ "GenMsgSendType" BO_ 984 5;
BA_ "GenMsgCycleTime" BO_ 984 1000;
BA_ "FrameRouting" BO_ 984 "FD1_CAN,0x3D8;HS2_CAN,0x3D8";
BA_ "VFrameFormat" BO_ 984 14;
BA_ "GenMsgSendType" BO_ 983 0;
BA_ "GenMsgCycleTime" BO_ 983 50;
BA_ "FrameRouting" BO_ 983 "FD1_CAN,0x3D7;HS2_CAN,0x3D7";
BA_ "VFrameFormat" BO_ 983 14;
BA_ "GenMsgSendType" BO_ 976 0;
BA_ "GenMsgCycleTime" BO_ 976 20;
BA_ "GenMsgDelayTime" BO_ 976 10;
BA_ "VFrameFormat" BO_ 976 14;
BA_ "GenMsgSendType" BO_ 973 5;
BA_ "GenMsgCycleTime" BO_ 973 1000;
BA_ "VFrameFormat" BO_ 973 14;
BA_ "GenMsgSendType" BO_ 970 0;
BA_ "GenMsgCycleTime" BO_ 970 30;
BA_ "GenMsgDelayTime" BO_ 970 10;
BA_ "FrameRouting" BO_ 970 "FD1_CAN,0x3CA;HS2_CAN,0x3CA";
BA_ "VFrameFormat" BO_ 970 14;
BA_ "GenMsgSendType" BO_ 394 5;
BA_ "GenMsgCycleTime" BO_ 394 200;
BA_ "VFrameFormat" BO_ 394 14;
BA_ "GenMsgSendType" BO_ 391 0;
BA_ "GenMsgCycleTime" BO_ 391 20;
BA_ "GenMsgDelayTime" BO_ 391 10;
BA_ "FrameRouting" BO_ 391 "FD1_CAN,0x187;HS2_CAN,0x187";
BA_ "VFrameFormat" BO_ 391 14;
BA_ "GenMsgSendType" BO_ 390 0;
BA_ "GenMsgCycleTime" BO_ 390 20;
BA_ "GenMsgDelayTime" BO_ 390 10;
BA_ "FrameRouting" BO_ 390 "FD1_CAN,0x186;HS2_CAN,0x186";
BA_ "VFrameFormat" BO_ 390 14;
BA_ "GenMsgILSupport" BO_ 1441 0;
BA_ "NmAsrMessage" BO_ 1441 1;
BA_ "GenMsgSendType" BO_ 1441 0;
BA_ "GenMsgCycleTime" BO_ 1441 1000;
BA_ "NetworkInitialization" BO_ 1441 0;
BA_ "VFrameFormat" BO_ 1441 14;
BA_ "GenMsgSendType" BO_ 1186 0;
BA_ "GenMsgCycleTime" BO_ 1186 100;
BA_ "VFrameFormat" BO_ 1186 14;
BA_ "WakeupSignal" SG_ 963 ImpactEvntFdbck_D_Stat 1;
BA_ "U_T6_MCA_MY2020_Rx" SG_ 963 ImpactEvntFdbck_D_Stat 1;
BA_ "U_CD542_MY2021_Rx" SG_ 963 ImpactEvntFdbck_D_Stat 1;
BA_ "U_U55X_MY2022_Rx" SG_ 963 ImpactEvntFdbck_D_Stat 1;
BA_ "U_CD764_MY2022_Rx" SG_ 963 ImpactEvntFdbck_D_Stat 1;
BA_ "U_CDX706_MY2023_Rx" SG_ 963 ImpactEvntFdbck_D_Stat 1;
BA_ "U_CX727_MY2021_Rx" SG_ 963 CrnrLghtRight_Pc_Rq 1;
BA_ "U_P702_MY2021_Rx" SG_ 963 CrnrLghtRight_Pc_Rq 1;
BA_ "U_U55X_MY2022_Rx" SG_ 963 CrnrLghtRight_Pc_Rq 1;
BA_ "U_CD764_MY2022_Rx" SG_ 963 CrnrLghtRight_Pc_Rq 1;
BA_ "U_CX727_MY2021_Rx" SG_ 963 CrnrLghtLeft_Pc_Rq 1;
BA_ "U_P702_MY2021_Rx" SG_ 963 CrnrLghtLeft_Pc_Rq 1;
BA_ "U_U55X_MY2022_Rx" SG_ 963 CrnrLghtLeft_Pc_Rq 1;
BA_ "U_CD764_MY2022_Rx" SG_ 963 CrnrLghtLeft_Pc_Rq 1;
BA_ "WakeupSignal" SG_ 963 KeyInIgnWarn_B_Cmd 1;
BA_ "WakeupSignal" SG_ 963 HomeSafeLtChime_B_Rq 1;
BA_ "WakeupSignal" SG_ 963 StopLghtOn_B_Stat 1;
BA_ "U_CX727_MY2021_Rx" SG_ 963 StopLghtOn_B_Stat 1;
BA_ "U_P702_MY2021_Rx" SG_ 963 StopLghtOn_B_Stat 1;
BA_ "U_U55X_MY2022_Rx" SG_ 963 StopLghtOn_B_Stat 1;
BA_ "U_CD764_MY2022_Rx" SG_ 963 StopLghtOn_B_Stat 1;
BA_ "WakeupSignal" SG_ 963 PrkLght_D_Stat 1;
BA_ "WakeupSignal" SG_ 963 HeadLghtSwtch_D_Stat 1;
BA_ "GenSigStartValueInteger" SG_ 963 HeadLghtSwtch_D_Stat 2;
BA_ "GenSigStartValue" SG_ 963 HeadLghtSwtch_D_Stat 2;
BA_ "U_CX727_MY2021_Rx" SG_ 963 HeadLghtSwtch_D_Stat 1;
BA_ "U_P702_MY2021_Rx" SG_ 963 HeadLghtSwtch_D_Stat 1;
BA_ "U_T6_MCA_MY2020_Rx" SG_ 963 HeadLghtSwtch_D_Stat 1;
BA_ "U_CD542_MY2021_Rx" SG_ 963 HeadLghtSwtch_D_Stat 1;
BA_ "U_U55X_MY2022_Rx" SG_ 963 HeadLghtSwtch_D_Stat 1;
BA_ "U_CD764_MY2022_Rx" SG_ 963 HeadLghtSwtch_D_Stat 1;
BA_ "U_CDX706_MY2023_Rx" SG_ 963 HeadLghtSwtch_D_Stat 1;
BA_ "GenSigStartValueInteger" SG_ 963 HeadLampLoFrOn_B_Stat 1;
BA_ "GenSigStartValue" SG_ 963 HeadLampLoFrOn_B_Stat 1;
BA_ "U_CX727_MY2021_Rx" SG_ 963 HeadLampLoFrOn_B_Stat 1;
BA_ "U_P702_MY2021_Rx" SG_ 963 HeadLampLoFrOn_B_Stat 1;
BA_ "U_T6_MCA_MY2020_Rx" SG_ 963 HeadLampLoFrOn_B_Stat 1;
BA_ "U_CD542_MY2021_Rx" SG_ 963 HeadLampLoFrOn_B_Stat 1;
BA_ "U_U55X_MY2022_Rx" SG_ 963 HeadLampLoFrOn_B_Stat 1;
BA_ "U_CD764_MY2022_Rx" SG_ 963 HeadLampLoFrOn_B_Stat 1;
BA_ "U_CDX706_MY2023_Rx" SG_ 963 HeadLampLoFrOn_B_Stat 1;
BA_ "GenSigStartValueInteger" SG_ 963 HeadLampLoFlOn_B_Stat 1;
BA_ "GenSigStartValue" SG_ 963 HeadLampLoFlOn_B_Stat 1;
BA_ "U_CX727_MY2021_Rx" SG_ 963 HeadLampLoFlOn_B_Stat 1;
BA_ "U_P702_MY2021_Rx" SG_ 963 HeadLampLoFlOn_B_Stat 1;
BA_ "U_T6_MCA_MY2020_Rx" SG_ 963 HeadLampLoFlOn_B_Stat 1;
BA_ "U_CD542_MY2021_Rx" SG_ 963 HeadLampLoFlOn_B_Stat 1;
BA_ "U_U55X_MY2022_Rx" SG_ 963 HeadLampLoFlOn_B_Stat 1;
BA_ "U_CD764_MY2022_Rx" SG_ 963 HeadLampLoFlOn_B_Stat 1;
BA_ "U_CDX706_MY2023_Rx" SG_ 963 HeadLampLoFlOn_B_Stat 1;
BA_ "GenSigStartValueInteger" SG_ 963 HeadLampLoActv_B_Stat 1;
BA_ "GenSigStartValue" SG_ 963 HeadLampLoActv_B_Stat 1;
BA_ "U_CX727_MY2021_Rx" SG_ 963 HeadLampLoActv_B_Stat 1;
BA_ "U_P702_MY2021_Rx" SG_ 963 HeadLampLoActv_B_Stat 1;
BA_ "U_T6_MCA_MY2020_Rx" SG_ 963 HeadLampLoActv_B_Stat 1;
BA_ "U_CD542_MY2021_Rx" SG_ 963 HeadLampLoActv_B_Stat 1;
BA_ "U_U55X_MY2022_Rx" SG_ 963 HeadLampLoActv_B_Stat 1;
BA_ "U_CD764_MY2022_Rx" SG_ 963 HeadLampLoActv_B_Stat 1;
BA_ "U_CDX706_MY2023_Rx" SG_ 963 HeadLampLoActv_B_Stat 1;
BA_ "WakeupSignal" SG_ 963 Headlamp_On_Wrning_Cmd 1;
BA_ "WakeupSignal" SG_ 963 HeadLghtHiOn_B_Stat 1;
BA_ "U_P702_MY2021_Rx" SG_ 963 HeadLghtHiOn_B_Stat 1;
BA_ "U_T6_MCA_MY2020_Rx" SG_ 963 HeadLghtHiOn_B_Stat 1;
BA_ "U_CD542_MY2021_Rx" SG_ 963 HeadLghtHiOn_B_Stat 1;
BA_ "U_U55X_MY2022_Rx" SG_ 963 HeadLghtHiOn_B_Stat 1;
BA_ "U_CD764_MY2022_Rx" SG_ 963 HeadLghtHiOn_B_Stat 1;
BA_ "U_CDX706_MY2023_Rx" SG_ 963 HeadLghtHiOn_B_Stat 1;
BA_ "WakeupSignal" SG_ 963 Perimeter_Alarm_Status 1;
BA_ "U_CDX706_MY2023_Rx" SG_ 963 Perimeter_Alarm_Status 1;
BA_ "WakeupSignal" SG_ 963 Courtesy_BSave_Stat 1;
BA_ "GenSigStartValueInteger" SG_ 963 Courtesy_BSave_Stat 1;
BA_ "GenSigStartValue" SG_ 963 Courtesy_BSave_Stat 1;
BA_ "WakeupSignal" SG_ 963 WndwGlbl_D_Cmd 1;
BA_ "WakeupSignal" SG_ 963 PudLamp_D_Rq 1;
BA_ "WakeupSignal" SG_ 963 PerimeterAlarmChimeRq 1;
BA_ "U_CD764_MY2022_Rx" SG_ 963 DayRnngLampOn_B_Stat 1;
BA_ "GenSigStartValueInteger" SG_ 145 VehYawWActl_D_Qf 1;
BA_ "MetaData" SG_ 145 VehYawWActl_D_Qf 1;
BA_ "GenSigStartValue" SG_ 145 VehYawWActl_D_Qf 1;
BA_ "U_CX727_MY2021_Rx" SG_ 145 VehYawWActl_D_Qf 1;
BA_ "U_P702_MY2021_Rx" SG_ 145 VehYawWActl_D_Qf 1;
BA_ "U_T6_MCA_MY2020_Rx" SG_ 145 VehYawWActl_D_Qf 1;
BA_ "U_CD542_MY2021_Rx" SG_ 145 VehYawWActl_D_Qf 1;
BA_ "U_U55X_MY2022_Rx" SG_ 145 VehYawWActl_D_Qf 1;
BA_ "U_CD764_MY2022_Rx" SG_ 145 VehYawWActl_D_Qf 1;
BA_ "U_CDX706_MY2023_Rx" SG_ 145 VehYawWActl_D_Qf 1;
BA_ "GenSigStartValueInteger" SG_ 145 VehRolWActl_D_Qf 1;
BA_ "MetaData" SG_ 145 VehRolWActl_D_Qf 1;
BA_ "GenSigStartValue" SG_ 145 VehRolWActl_D_Qf 1;
BA_ "U_CX727_MY2021_Rx" SG_ 145 VehRolWActl_D_Qf 1;
BA_ "U_P702_MY2021_Rx" SG_ 145 VehRolWActl_D_Qf 1;
BA_ "U_T6_MCA_MY2020_Rx" SG_ 145 VehRolWActl_D_Qf 1;
BA_ "U_CD542_MY2021_Rx" SG_ 145 VehRolWActl_D_Qf 1;
BA_ "U_U55X_MY2022_Rx" SG_ 145 VehRolWActl_D_Qf 1;
BA_ "U_CD764_MY2022_Rx" SG_ 145 VehRolWActl_D_Qf 1;
BA_ "U_CDX706_MY2023_Rx" SG_ 145 VehRolWActl_D_Qf 1;
BA_ "MetaData" SG_ 145 VehRollYawW_No_Cs 1;
BA_ "U_CX727_MY2021_Rx" SG_ 145 VehRollYawW_No_Cs 1;
BA_ "U_P702_MY2021_Rx" SG_ 145 VehRollYawW_No_Cs 1;
BA_ "U_T6_MCA_MY2020_Rx" SG_ 145 VehRollYawW_No_Cs 1;
BA_ "U_CD542_MY2021_Rx" SG_ 145 VehRollYawW_No_Cs 1;
BA_ "U_U55X_MY2022_Rx" SG_ 145 VehRollYawW_No_Cs 1;
BA_ "U_CD764_MY2022_Rx" SG_ 145 VehRollYawW_No_Cs 1;
BA_ "U_CDX706_MY2023_Rx" SG_ 145 VehRollYawW_No_Cs 1;
BA_ "MetaData" SG_ 145 VehRollYaw_No_Cnt 1;
BA_ "U_CX727_MY2021_Rx" SG_ 145 VehRollYaw_No_Cnt 1;
BA_ "U_P702_MY2021_Rx" SG_ 145 VehRollYaw_No_Cnt 1;
BA_ "U_T6_MCA_MY2020_Rx" SG_ 145 VehRollYaw_No_Cnt 1;
BA_ "U_CD542_MY2021_Rx" SG_ 145 VehRollYaw_No_Cnt 1;
BA_ "U_U55X_MY2022_Rx" SG_ 145 VehRollYaw_No_Cnt 1;
BA_ "U_CD764_MY2022_Rx" SG_ 145 VehRollYaw_No_Cnt 1;
BA_ "U_CDX706_MY2023_Rx" SG_ 145 VehRollYaw_No_Cnt 1;
BA_ "GenSigStartValueInteger" SG_ 145 VehYaw_W_Actl 65534;
BA_ "GenSigStartValue" SG_ 145 VehYaw_W_Actl 65534;
BA_ "U_CX727_MY2021_Rx" SG_ 145 VehYaw_W_Actl 1;
BA_ "U_P702_MY2021_Rx" SG_ 145 VehYaw_W_Actl 1;
BA_ "U_T6_MCA_MY2020_Rx" SG_ 145 VehYaw_W_Actl 1;
BA_ "U_CD542_MY2021_Rx" SG_ 145 VehYaw_W_Actl 1;
BA_ "U_U55X_MY2022_Rx" SG_ 145 VehYaw_W_Actl 1;
BA_ "U_CD764_MY2022_Rx" SG_ 145 VehYaw_W_Actl 1;
BA_ "U_CDX706_MY2023_Rx" SG_ 145 VehYaw_W_Actl 1;
BA_ "GenSigStartValueInteger" SG_ 145 VehRol_W_Actl 65534;
BA_ "GenSigStartValue" SG_ 145 VehRol_W_Actl 65534;
BA_ "U_CX727_MY2021_Rx" SG_ 145 VehRol_W_Actl 1;
BA_ "U_P702_MY2021_Rx" SG_ 145 VehRol_W_Actl 1;
BA_ "U_T6_MCA_MY2020_Rx" SG_ 145 VehRol_W_Actl 1;
BA_ "U_CD542_MY2021_Rx" SG_ 145 VehRol_W_Actl 1;
BA_ "U_U55X_MY2022_Rx" SG_ 145 VehRol_W_Actl 1;
BA_ "U_CD764_MY2022_Rx" SG_ 145 VehRol_W_Actl 1;
BA_ "U_CDX706_MY2023_Rx" SG_ 145 VehRol_W_Actl 1;
BA_ "GenSigStartValueInteger" SG_ 76 PsngrFmidDetct_D_Actl 3;
BA_ "GenSigStartValue" SG_ 76 PsngrFmidDetct_D_Actl 3;
BA_ "GenSigStartValueInteger" SG_ 76 FirstRowBuckleMid 3;
BA_ "GenSigStartValue" SG_ 76 FirstRowBuckleMid 3;
BA_ "U_T6_MCA_MY2020_Rx" SG_ 76 FirstRowBuckleMid 1;
BA_ "U_U55X_MY2022_Rx" SG_ 76 FirstRowBuckleMid 1;
BA_ "U_CDX706_MY2023_Rx" SG_ 76 FirstRowBuckleMid 1;
BA_ "GenSigStartValueInteger" SG_ 76 ThirdRowBucklePsngr 3;
BA_ "GenSigStartValue" SG_ 76 ThirdRowBucklePsngr 3;
BA_ "GenSigStartValueInteger" SG_ 76 ThirdRowBuckleMid 3;
BA_ "GenSigStartValue" SG_ 76 ThirdRowBuckleMid 3;
BA_ "GenSigStartValueInteger" SG_ 76 ThirdRowBuckleDriver 3;
BA_ "GenSigStartValue" SG_ 76 ThirdRowBuckleDriver 3;
BA_ "GenSigStartValueInteger" SG_ 76 SecondRowBucklePsngr 3;
BA_ "GenSigStartValue" SG_ 76 SecondRowBucklePsngr 3;
BA_ "GenSigStartValueInteger" SG_ 76 SecondRowBuckleMid 3;
BA_ "GenSigStartValue" SG_ 76 SecondRowBuckleMid 3;
BA_ "GenSigStartValueInteger" SG_ 76 SecondRowBuckleDriver 3;
BA_ "GenSigStartValue" SG_ 76 SecondRowBuckleDriver 3;
BA_ "GenSigStartValueInteger" SG_ 76 FirstRowBuckleDriver 3;
BA_ "GenSigStartValue" SG_ 76 FirstRowBuckleDriver 3;
BA_ "U_CX727_MY2021_Rx" SG_ 76 FirstRowBuckleDriver 1;
BA_ "U_P702_MY2021_Rx" SG_ 76 FirstRowBuckleDriver 1;
BA_ "U_T6_MCA_MY2020_Rx" SG_ 76 FirstRowBuckleDriver 1;
BA_ "U_CD542_MY2021_Rx" SG_ 76 FirstRowBuckleDriver 1;
BA_ "U_U55X_MY2022_Rx" SG_ 76 FirstRowBuckleDriver 1;
BA_ "U_CD764_MY2022_Rx" SG_ 76 FirstRowBuckleDriver 1;
BA_ "U_CDX706_MY2023_Rx" SG_ 76 FirstRowBuckleDriver 1;
BA_ "GenSigStartValueInteger" SG_ 76 FirstRowBucklePsngr 3;
BA_ "GenSigStartValue" SG_ 76 FirstRowBucklePsngr 3;
BA_ "U_T6_MCA_MY2020_Rx" SG_ 76 FirstRowBucklePsngr 1;
BA_ "U_U55X_MY2022_Rx" SG_ 76 FirstRowBucklePsngr 1;
BA_ "U_CDX706_MY2023_Rx" SG_ 76 FirstRowBucklePsngr 1;
BA_ "WakeupSignal" SG_ 76 RstrnImpactEvntStatus 1;
BA_ "U_CX727_MY2021_Rx" SG_ 76 RstrnImpactEvntStatus 1;
BA_ "U_P702_MY2021_Rx" SG_ 76 RstrnImpactEvntStatus 1;
BA_ "U_T6_MCA_MY2020_Rx" SG_ 76 RstrnImpactEvntStatus 1;
BA_ "U_CD542_MY2021_Rx" SG_ 76 RstrnImpactEvntStatus 1;
BA_ "U_U55X_MY2022_Rx" SG_ 76 RstrnImpactEvntStatus 1;
BA_ "U_CD764_MY2022_Rx" SG_ 76 RstrnImpactEvntStatus 1;
BA_ "U_CDX706_MY2023_Rx" SG_ 76 RstrnImpactEvntStatus 1;
BA_ "GenSigStartValueInteger" SG_ 76 PsngrFrntDetct_D_Actl 3;
BA_ "GenSigStartValue" SG_ 76 PsngrFrntDetct_D_Actl 3;
BA_ "U_T6_MCA_MY2020_Rx" SG_ 76 EDRTriggerEvntSync 1;
BA_ "U_CD542_MY2021_Rx" SG_ 76 EDRTriggerEvntSync 1;
BA_ "U_U55X_MY2022_Rx" SG_ 76 EDRTriggerEvntSync 1;
BA_ "U_CD764_MY2022_Rx" SG_ 76 EDRTriggerEvntSync 1;
BA_ "U_CDX706_MY2023_Rx" SG_ 76 EDRTriggerEvntSync 1;
BA_ "GenSigStartValueInteger" SG_ 76 PassRstrnInd_Req 3;
BA_ "GenSigStartValue" SG_ 76 PassRstrnInd_Req 3;
BA_ "MetaData" SG_ 76 FirstRowBuckle_No_Cs 1;
BA_ "U_T6_MCA_MY2020_Rx" SG_ 76 FirstRowBuckle_No_Cs 1;
BA_ "U_U55X_MY2022_Rx" SG_ 76 FirstRowBuckle_No_Cs 1;
BA_ "U_CDX706_MY2023_Rx" SG_ 76 FirstRowBuckle_No_Cs 1;
BA_ "MetaData" SG_ 76 RCMStatusMsg2_No_Cnt 1;
BA_ "U_T6_MCA_MY2020_Rx" SG_ 76 RCMStatusMsg2_No_Cnt 1;
BA_ "U_U55X_MY2022_Rx" SG_ 76 RCMStatusMsg2_No_Cnt 1;
BA_ "U_CDX706_MY2023_Rx" SG_ 76 RCMStatusMsg2_No_Cnt 1;
BA_ "U_CX727_MY2021_Rx" SG_ 65 immoControlData_T1 1;
BA_ "U_P702_MY2021_Rx" SG_ 65 immoControlData_T1 1;
BA_ "U_T6_MCA_MY2020_Rx" SG_ 65 immoControlData_T1 1;
BA_ "U_CD542_MY2021_Rx" SG_ 65 immoControlData_T1 1;
BA_ "U_U55X_MY2022_Rx" SG_ 65 immoControlData_T1 1;
BA_ "U_CD764_MY2022_Rx" SG_ 65 immoControlData_T1 1;
BA_ "U_CDX706_MY2023_Rx" SG_ 65 immoControlData_T1 1;
BA_ "U_CX727_MY2021_Rx" SG_ 65 immoControlCmd_T1 1;
BA_ "U_P702_MY2021_Rx" SG_ 65 immoControlCmd_T1 1;
BA_ "U_T6_MCA_MY2020_Rx" SG_ 65 immoControlCmd_T1 1;
BA_ "U_CD542_MY2021_Rx" SG_ 65 immoControlCmd_T1 1;
BA_ "U_U55X_MY2022_Rx" SG_ 65 immoControlCmd_T1 1;
BA_ "U_CD764_MY2022_Rx" SG_ 65 immoControlCmd_T1 1;
BA_ "U_CDX706_MY2023_Rx" SG_ 65 immoControlCmd_T1 1;
BA_ "U_P702_MY2021_Rx" SG_ 1076 AutoRgen_D_Rq 1;
BA_ "U_T6_MCA_MY2020_Rx" SG_ 1076 AutoRgen_D_Rq 1;
BA_ "GenSigStartValueInteger" SG_ 1076 W2S_LAMP_OK 1;
BA_ "GenSigStartValue" SG_ 1076 W2S_LAMP_OK 1;
BA_ "U_T6_MCA_MY2020_Rx" SG_ 1076 W2S_LAMP_OK 1;
BA_ "U_CX727_MY2021_Rx" SG_ 1076 OdoTripRx_B_Actl 1;
BA_ "U_P702_MY2021_Rx" SG_ 1076 OdoTripRx_B_Actl 1;
BA_ "U_T6_MCA_MY2020_Rx" SG_ 1076 OdoTripRx_B_Actl 1;
BA_ "U_CD542_MY2021_Rx" SG_ 1076 OdoTripRx_B_Actl 1;
BA_ "U_U55X_MY2022_Rx" SG_ 1076 OdoTripRx_B_Actl 1;
BA_ "U_CD764_MY2022_Rx" SG_ 1076 OdoTripRx_B_Actl 1;
BA_ "U_CDX706_MY2023_Rx" SG_ 1076 OdoTripRx_B_Actl 1;
BA_ "GenSigStartValueInteger" SG_ 1076 Veh_V_CompLimMx 4095;
BA_ "GenSigStartValue" SG_ 1076 Veh_V_CompLimMx 4093;
BA_ "U_CX727_MY2021_Rx" SG_ 1076 Veh_V_CompLimMx 1;
BA_ "U_P702_MY2021_Rx" SG_ 1076 Veh_V_CompLimMx 1;
BA_ "U_T6_MCA_MY2020_Rx" SG_ 1076 Veh_V_CompLimMx 1;
BA_ "U_CD542_MY2021_Rx" SG_ 1076 Veh_V_CompLimMx 1;
BA_ "U_U55X_MY2022_Rx" SG_ 1076 Veh_V_CompLimMx 1;
BA_ "U_CD764_MY2022_Rx" SG_ 1076 Veh_V_CompLimMx 1;
BA_ "U_CDX706_MY2023_Rx" SG_ 1076 Veh_V_CompLimMx 1;
BA_ "U_CX727_MY2021_Rx" SG_ 1076 DrvSlipCtlMde_B_RqMyKey 1;
BA_ "U_T6_MCA_MY2020_Rx" SG_ 1076 DrvSlipCtlMde_B_RqMyKey 1;
BA_ "U_CD542_MY2021_Rx" SG_ 1076 DrvSlipCtlMde_B_RqMyKey 1;
BA_ "U_U55X_MY2022_Rx" SG_ 1076 DrvSlipCtlMde_B_RqMyKey 1;
BA_ "U_CD764_MY2022_Rx" SG_ 1076 DrvSlipCtlMde_B_RqMyKey 1;
BA_ "U_CDX706_MY2023_Rx" SG_ 1076 DrvSlipCtlMde_B_RqMyKey 1;
BA_ "U_P702_MY2021_Rx" SG_ 1076 HILL_DESC_SW 1;
BA_ "U_T6_MCA_MY2020_Rx" SG_ 1076 HILL_DESC_SW 1;
BA_ "U_U55X_MY2022_Rx" SG_ 1076 HILL_DESC_SW 1;
BA_ "U_CX727_MY2021_Rx" SG_ 1076 FuelLvlPssvSide_No_Raw 1;
BA_ "U_P702_MY2021_Rx" SG_ 1076 FuelLvlPssvSide_No_Raw 1;
BA_ "U_T6_MCA_MY2020_Rx" SG_ 1076 FuelLvlPssvSide_No_Raw 1;
BA_ "U_CD542_MY2021_Rx" SG_ 1076 FuelLvlPssvSide_No_Raw 1;
BA_ "U_U55X_MY2022_Rx" SG_ 1076 FuelLvlPssvSide_No_Raw 1;
BA_ "U_CD764_MY2022_Rx" SG_ 1076 FuelLvlPssvSide_No_Raw 1;
BA_ "U_CDX706_MY2023_Rx" SG_ 1076 FuelLvlPssvSide_No_Raw 1;
BA_ "U_CX727_MY2021_Rx" SG_ 1076 FUEL_SENSOR_NUM 1;
BA_ "U_P702_MY2021_Rx" SG_ 1076 FUEL_SENSOR_NUM 1;
BA_ "U_T6_MCA_MY2020_Rx" SG_ 1076 FUEL_SENSOR_NUM 1;
BA_ "U_CD542_MY2021_Rx" SG_ 1076 FUEL_SENSOR_NUM 1;
BA_ "U_U55X_MY2022_Rx" SG_ 1076 FUEL_SENSOR_NUM 1;
BA_ "U_CD764_MY2022_Rx" SG_ 1076 FUEL_SENSOR_NUM 1;
BA_ "U_CDX706_MY2023_Rx" SG_ 1076 FUEL_SENSOR_NUM 1;
BA_ "U_CX727_MY2021_Rx" SG_ 1076 FuelLvlActvSide_No_Raw 1;
BA_ "U_P702_MY2021_Rx" SG_ 1076 FuelLvlActvSide_No_Raw 1;
BA_ "U_T6_MCA_MY2020_Rx" SG_ 1076 FuelLvlActvSide_No_Raw 1;
BA_ "U_CD542_MY2021_Rx" SG_ 1076 FuelLvlActvSide_No_Raw 1;
BA_ "U_U55X_MY2022_Rx" SG_ 1076 FuelLvlActvSide_No_Raw 1;
BA_ "U_CD764_MY2022_Rx" SG_ 1076 FuelLvlActvSide_No_Raw 1;
BA_ "U_CDX706_MY2023_Rx" SG_ 1076 FuelLvlActvSide_No_Raw 1;
BA_ "U_P702_MY2021_Rx" SG_ 1076 FuelLvl_Pc_Dsply 1;
BA_ "U_T6_MCA_MY2020_Rx" SG_ 1076 FuelLvl_Pc_Dsply 1;
BA_ "U_U55X_MY2022_Rx" SG_ 1076 FuelLvl_Pc_Dsply 1;
BA_ "U_CX727_MY2021_Rx" SG_ 1076 DISPLAY_SPEED_SCALING 1;
BA_ "U_P702_MY2021_Rx" SG_ 1076 DISPLAY_SPEED_SCALING 1;
BA_ "U_T6_MCA_MY2020_Rx" SG_ 1076 DISPLAY_SPEED_SCALING 1;
BA_ "U_CD542_MY2021_Rx" SG_ 1076 DISPLAY_SPEED_SCALING 1;
BA_ "U_U55X_MY2022_Rx" SG_ 1076 DISPLAY_SPEED_SCALING 1;
BA_ "U_CD764_MY2022_Rx" SG_ 1076 DISPLAY_SPEED_SCALING 1;
BA_ "U_CDX706_MY2023_Rx" SG_ 1076 DISPLAY_SPEED_SCALING 1;
BA_ "U_CX727_MY2021_Rx" SG_ 1076 DISPLAY_SPEED_OFFSET 1;
BA_ "U_P702_MY2021_Rx" SG_ 1076 DISPLAY_SPEED_OFFSET 1;
BA_ "U_T6_MCA_MY2020_Rx" SG_ 1076 DISPLAY_SPEED_OFFSET 1;
BA_ "U_CD542_MY2021_Rx" SG_ 1076 DISPLAY_SPEED_OFFSET 1;
BA_ "U_U55X_MY2022_Rx" SG_ 1076 DISPLAY_SPEED_OFFSET 1;
BA_ "U_CD764_MY2022_Rx" SG_ 1076 DISPLAY_SPEED_OFFSET 1;
BA_ "U_CDX706_MY2023_Rx" SG_ 1076 DISPLAY_SPEED_OFFSET 1;
BA_ "WakeupSignal" SG_ 836 Foh_D_Stat 1;
BA_ "ContentDependant" SG_ 836 Foh_D_Stat 1;
BA_ "ContentDependant" SG_ 836 FuelFlw_Vl_ActlFoh 1;
BA_ "ContentDependant" SG_ 836 EngClnt_Te_ActlFoh 1;
BA_ "ContentDependant" SG_ 836 FohFalt_D_Stat 1;
BA_ "ContentDependant" SG_ 836 FohEnbl_B_RqDrv 1;
BA_ "ContentDependant" SG_ 836 FohRqRun_B_Rq 1;
BA_ "WakeupSignal" SG_ 836 HvacPrecondMode_D_Rq 1;
BA_ "ContentDependant" SG_ 836 HvacPrecondMode_D_Rq 1;
BA_ "WakeupSignal" SG_ 836 HvacPrecondBlwr_D_Rq 1;
BA_ "ContentDependant" SG_ 836 HvacPrecondBlwr_D_Rq 1;
BA_ "U_CDX706_MY2023_Rx" SG_ 862 EcoMde_D_RqDrv 1;
BA_ "U_CX727_MY2021_Rx" SG_ 862 TwHlGrdAsst_B_RqTrn 1;
BA_ "U_CDX706_MY2023_Rx" SG_ 862 ApaSwtch_D_RqDrv 1;
BA_ "U_CX727_MY2021_Rx" SG_ 862 HvacBlwrFront_D_Stat 1;
BA_ "U_P702_MY2021_Rx" SG_ 862 HvacBlwrFront_D_Stat 1;
BA_ "U_T6_MCA_MY2020_Rx" SG_ 862 HvacBlwrFront_D_Stat 1;
BA_ "U_CD542_MY2021_Rx" SG_ 862 HvacBlwrFront_D_Stat 1;
BA_ "U_U55X_MY2022_Rx" SG_ 862 HvacBlwrFront_D_Stat 1;
BA_ "U_CD764_MY2022_Rx" SG_ 862 HvacBlwrFront_D_Stat 1;
BA_ "U_CDX706_MY2023_Rx" SG_ 862 HvacBlwrFront_D_Stat 1;
BA_ "U_CX727_MY2021_Rx" SG_ 862 HvacBlwrRear_D_Stat 1;
BA_ "U_P702_MY2021_Rx" SG_ 862 HvacBlwrRear_D_Stat 1;
BA_ "U_T6_MCA_MY2020_Rx" SG_ 862 HvacBlwrRear_D_Stat 1;
BA_ "U_CD542_MY2021_Rx" SG_ 862 HvacBlwrRear_D_Stat 1;
BA_ "U_U55X_MY2022_Rx" SG_ 862 HvacBlwrRear_D_Stat 1;
BA_ "U_CD764_MY2022_Rx" SG_ 862 HvacBlwrRear_D_Stat 1;
BA_ "U_CDX706_MY2023_Rx" SG_ 862 HvacBlwrRear_D_Stat 1;
BA_ "GenSigStartValueInteger" SG_ 862 CabnAmb_Te_Actl 114;
BA_ "U_CX727_MY2021_Rx" SG_ 862 CabnAmb_Te_Actl 1;
BA_ "U_P702_MY2021_Rx" SG_ 862 CabnAmb_Te_Actl 1;
BA_ "U_CD542_MY2021_Rx" SG_ 862 CabnAmb_Te_Actl 1;
BA_ "U_CDX706_MY2023_Rx" SG_ 862 CabnAmb_Te_Actl 1;
BA_ "U_CX727_MY2021_Rx" SG_ 862 HvacRemoteStrt_N_Rq 1;
BA_ "U_P702_MY2021_Rx" SG_ 862 HvacRemoteStrt_N_Rq 1;
BA_ "U_T6_MCA_MY2020_Rx" SG_ 862 HvacRemoteStrt_N_Rq 1;
BA_ "U_CD542_MY2021_Rx" SG_ 862 HvacRemoteStrt_N_Rq 1;
BA_ "U_U55X_MY2022_Rx" SG_ 862 HvacRemoteStrt_N_Rq 1;
BA_ "U_CD764_MY2022_Rx" SG_ 862 HvacRemoteStrt_N_Rq 1;
BA_ "U_CDX706_MY2023_Rx" SG_ 862 HvacRemoteStrt_N_Rq 1;
BA_ "GenSigStartValueInteger" SG_ 862 ClimtThrmlLoad_No_Actl 255;
BA_ "GenSigStartValue" SG_ 862 ClimtThrmlLoad_No_Actl 255;
BA_ "U_CX727_MY2021_Rx" SG_ 862 ClimtThrmlLoad_No_Actl 1;
BA_ "U_P702_MY2021_Rx" SG_ 862 ClimtThrmlLoad_No_Actl 1;
BA_ "U_CD542_MY2021_Rx" SG_ 862 ClimtThrmlLoad_No_Actl 1;
BA_ "U_CDX706_MY2023_Rx" SG_ 862 ClimtThrmlLoad_No_Actl 1;
BA_ "U_CX727_MY2021_Rx" SG_ 862 HvacRec_Pc_Est 1;
BA_ "U_P702_MY2021_Rx" SG_ 862 HvacRec_Pc_Est 1;
BA_ "U_CD542_MY2021_Rx" SG_ 862 HvacRec_Pc_Est 1;
BA_ "U_CDX706_MY2023_Rx" SG_ 862 HvacRec_Pc_Est 1;
BA_ "GenSigStartValueInteger" SG_ 862 AutoStpHvacDelta_I_Est 192;
BA_ "U_CX727_MY2021_Rx" SG_ 862 HvacAir_Flw_Est 1;
BA_ "U_P702_MY2021_Rx" SG_ 862 HvacAir_Flw_Est 1;
BA_ "U_CD542_MY2021_Rx" SG_ 862 HvacAir_Flw_Est 1;
BA_ "U_CDX706_MY2023_Rx" SG_ 862 HvacAir_Flw_Est 1;
BA_ "MetaData" SG_ 862 ApaSwtch_No_Cnt 1;
BA_ "U_P702_MY2021_Rx" SG_ 931 VehOnSrc_D_Stat 1;
BA_ "U_T6_MCA_MY2020_Rx" SG_ 931 VehOnSrc_D_Stat 1;
BA_ "U_CD542_MY2021_Rx" SG_ 931 VehOnSrc_D_Stat 1;
BA_ "U_U55X_MY2022_Rx" SG_ 931 VehOnSrc_D_Stat 1;
BA_ "U_CD764_MY2022_Rx" SG_ 931 VehOnSrc_D_Stat 1;
BA_ "U_CDX706_MY2023_Rx" SG_ 931 VehOnSrc_D_Stat 1;
BA_ "MetaData" SG_ 931 StrtrMtrCtlDStat_No_Cs 1;
BA_ "U_P702_MY2021_Rx" SG_ 931 StrtrMtrCtlDStat_No_Cs 1;
BA_ "U_T6_MCA_MY2020_Rx" SG_ 931 StrtrMtrCtlDStat_No_Cs 1;
BA_ "U_CD542_MY2021_Rx" SG_ 931 StrtrMtrCtlDStat_No_Cs 1;
BA_ "U_U55X_MY2022_Rx" SG_ 931 StrtrMtrCtlDStat_No_Cs 1;
BA_ "U_CD764_MY2022_Rx" SG_ 931 StrtrMtrCtlDStat_No_Cs 1;
BA_ "U_CDX706_MY2023_Rx" SG_ 931 StrtrMtrCtlDStat_No_Cs 1;
BA_ "U_P702_MY2021_Rx" SG_ 931 EngStrtActv_B_Stat 1;
BA_ "U_T6_MCA_MY2020_Rx" SG_ 931 EngStrtActv_B_Stat 1;
BA_ "U_CD542_MY2021_Rx" SG_ 931 EngStrtActv_B_Stat 1;
BA_ "U_U55X_MY2022_Rx" SG_ 931 EngStrtActv_B_Stat 1;
BA_ "U_CD764_MY2022_Rx" SG_ 931 EngStrtActv_B_Stat 1;
BA_ "U_CDX706_MY2023_Rx" SG_ 931 EngStrtActv_B_Stat 1;
BA_ "U_P702_MY2021_Rx" SG_ 931 EngStrt_B_Rq 1;
BA_ "U_T6_MCA_MY2020_Rx" SG_ 931 EngStrt_B_Rq 1;
BA_ "U_CD542_MY2021_Rx" SG_ 931 EngStrt_B_Rq 1;
BA_ "U_U55X_MY2022_Rx" SG_ 931 EngStrt_B_Rq 1;
BA_ "U_CD764_MY2022_Rx" SG_ 931 EngStrt_B_Rq 1;
BA_ "U_CDX706_MY2023_Rx" SG_ 931 EngStrt_B_Rq 1;
BA_ "U_P702_MY2021_Rx" SG_ 931 DrvInCtl_B_Stat 1;
BA_ "U_T6_MCA_MY2020_Rx" SG_ 931 DrvInCtl_B_Stat 1;
BA_ "U_CD542_MY2021_Rx" SG_ 931 DrvInCtl_B_Stat 1;
BA_ "U_U55X_MY2022_Rx" SG_ 931 DrvInCtl_B_Stat 1;
BA_ "U_CD764_MY2022_Rx" SG_ 931 DrvInCtl_B_Stat 1;
BA_ "U_CDX706_MY2023_Rx" SG_ 931 DrvInCtl_B_Stat 1;
BA_ "U_P702_MY2021_Rx" SG_ 931 PtWakeReas_D_Stat 1;
BA_ "U_CD542_MY2021_Rx" SG_ 931 PtWakeReas_D_Stat 1;
BA_ "U_CDX706_MY2023_Rx" SG_ 931 PtWakeReas_D_Stat 1;
BA_ "ContentDependant" SG_ 931 CrnkInhbt_No_Cs 1;
BA_ "MetaData" SG_ 931 CrnkInhbt_No_Cs 1;
BA_ "U_CX727_MY2021_Rx" SG_ 931 CrnkInhbt_No_Cs 1;
BA_ "U_P702_MY2021_Rx" SG_ 931 CrnkInhbt_No_Cs 1;
BA_ "U_T6_MCA_MY2020_Rx" SG_ 931 CrnkInhbt_No_Cs 1;
BA_ "U_CD542_MY2021_Rx" SG_ 931 CrnkInhbt_No_Cs 1;
BA_ "U_U55X_MY2022_Rx" SG_ 931 CrnkInhbt_No_Cs 1;
BA_ "U_CD764_MY2022_Rx" SG_ 931 CrnkInhbt_No_Cs 1;
BA_ "U_CDX706_MY2023_Rx" SG_ 931 CrnkInhbt_No_Cs 1;
BA_ "ContentDependant" SG_ 931 CrnkInhbt_No_Cnt 1;
BA_ "MetaData" SG_ 931 CrnkInhbt_No_Cnt 1;
BA_ "U_CX727_MY2021_Rx" SG_ 931 CrnkInhbt_No_Cnt 1;
BA_ "U_P702_MY2021_Rx" SG_ 931 CrnkInhbt_No_Cnt 1;
BA_ "U_T6_MCA_MY2020_Rx" SG_ 931 CrnkInhbt_No_Cnt 1;
BA_ "U_CD542_MY2021_Rx" SG_ 931 CrnkInhbt_No_Cnt 1;
BA_ "U_U55X_MY2022_Rx" SG_ 931 CrnkInhbt_No_Cnt 1;
BA_ "U_CD764_MY2022_Rx" SG_ 931 CrnkInhbt_No_Cnt 1;
BA_ "U_CDX706_MY2023_Rx" SG_ 931 CrnkInhbt_No_Cnt 1;
BA_ "GenSigStartValueInteger" SG_ 931 CrnkInhbt_B_Stat 1;
BA_ "GenSigStartValue" SG_ 931 CrnkInhbt_B_Stat 1;
BA_ "U_CX727_MY2021_Rx" SG_ 931 CrnkInhbt_B_Stat 1;
BA_ "U_P702_MY2021_Rx" SG_ 931 CrnkInhbt_B_Stat 1;
BA_ "U_T6_MCA_MY2020_Rx" SG_ 931 CrnkInhbt_B_Stat 1;
BA_ "U_CD542_MY2021_Rx" SG_ 931 CrnkInhbt_B_Stat 1;
BA_ "U_U55X_MY2022_Rx" SG_ 931 CrnkInhbt_B_Stat 1;
BA_ "U_CD764_MY2022_Rx" SG_ 931 CrnkInhbt_B_Stat 1;
BA_ "U_CDX706_MY2023_Rx" SG_ 931 CrnkInhbt_B_Stat 1;
BA_ "U_P702_MY2021_Rx" SG_ 931 IgnPreOffActv_B_Stat 1;
BA_ "U_T6_MCA_MY2020_Rx" SG_ 931 IgnPreOffActv_B_Stat 1;
BA_ "U_CD542_MY2021_Rx" SG_ 931 IgnPreOffActv_B_Stat 1;
BA_ "U_U55X_MY2022_Rx" SG_ 931 IgnPreOffActv_B_Stat 1;
BA_ "U_CD764_MY2022_Rx" SG_ 931 IgnPreOffActv_B_Stat 1;
BA_ "U_CDX706_MY2023_Rx" SG_ 931 IgnPreOffActv_B_Stat 1;
BA_ "U_T6_MCA_MY2020_Rx" SG_ 931 AdvStrt_No_Stat 1;
BA_ "U_CD764_MY2022_Rx" SG_ 931 AdvStrt_No_Stat 1;
BA_ "U_CDX706_MY2023_Rx" SG_ 931 AdvStrt_No_Stat 1;
BA_ "U_CX727_MY2021_Rx" SG_ 578 PtLatchActv_B_RqBcm 1;
BA_ "U_P702_MY2021_Rx" SG_ 578 PtLatchActv_B_RqBcm 1;
BA_ "U_T6_MCA_MY2020_Rx" SG_ 578 PtLatchActv_B_RqBcm 1;
BA_ "U_CD542_MY2021_Rx" SG_ 578 PtLatchActv_B_RqBcm 1;
BA_ "U_U55X_MY2022_Rx" SG_ 578 PtLatchActv_B_RqBcm 1;
BA_ "U_CD764_MY2022_Rx" SG_ 578 PtLatchActv_B_RqBcm 1;
BA_ "U_CDX706_MY2023_Rx" SG_ 578 PtLatchActv_B_RqBcm 1;
BA_ "U_CX727_MY2021_Rx" SG_ 578 immoSecureIdleMode 1;
BA_ "U_P702_MY2021_Rx" SG_ 578 immoSecureIdleMode 1;
BA_ "U_T6_MCA_MY2020_Rx" SG_ 578 immoSecureIdleMode 1;
BA_ "U_CD542_MY2021_Rx" SG_ 578 immoSecureIdleMode 1;
BA_ "U_U55X_MY2022_Rx" SG_ 578 immoSecureIdleMode 1;
BA_ "U_CD764_MY2022_Rx" SG_ 578 immoSecureIdleMode 1;
BA_ "U_CDX706_MY2023_Rx" SG_ 578 immoSecureIdleMode 1;
BA_ "WakeupSignal" SG_ 578 ReFuelSwtchStat_D_Actl 1;
BA_ "U_CX727_MY2021_Rx" SG_ 578 ReFuelSwtchStat_D_Actl 1;
BA_ "U_CD542_MY2021_Rx" SG_ 578 ReFuelSwtchStat_D_Actl 1;
BA_ "U_CX727_MY2021_Rx" SG_ 578 FuelPumpPwr_D_Stat 1;
BA_ "U_P702_MY2021_Rx" SG_ 578 FuelPumpPwr_D_Stat 1;
BA_ "U_T6_MCA_MY2020_Rx" SG_ 578 FuelPumpPwr_D_Stat 1;
BA_ "U_CD542_MY2021_Rx" SG_ 578 FuelPumpPwr_D_Stat 1;
BA_ "U_U55X_MY2022_Rx" SG_ 578 FuelPumpPwr_D_Stat 1;
BA_ "U_CD764_MY2022_Rx" SG_ 578 FuelPumpPwr_D_Stat 1;
BA_ "U_CDX706_MY2023_Rx" SG_ 578 FuelPumpPwr_D_Stat 1;
BA_ "GenSigStartValueInteger" SG_ 578 BattULo_U_Actl 255;
BA_ "GenSigStartValue" SG_ 578 BattULo_U_Actl 255;
BA_ "U_CX727_MY2021_Rx" SG_ 578 BattULo_U_Actl 1;
BA_ "U_P702_MY2021_Rx" SG_ 578 BattULo_U_Actl 1;
BA_ "U_T6_MCA_MY2020_Rx" SG_ 578 BattULo_U_Actl 1;
BA_ "U_CD542_MY2021_Rx" SG_ 578 BattULo_U_Actl 1;
BA_ "U_U55X_MY2022_Rx" SG_ 578 BattULo_U_Actl 1;
BA_ "U_CD764_MY2022_Rx" SG_ 578 BattULo_U_Actl 1;
BA_ "U_CDX706_MY2023_Rx" SG_ 578 BattULo_U_Actl 1;
BA_ "WakeupSignal" SG_ 578 PrkLckCtlMsgTxt_D_Rq 1;
BA_ "U_CX727_MY2021_Rx" SG_ 578 PrkLckCtlMsgTxt_D_Rq 1;
BA_ "U_CD542_MY2021_Rx" SG_ 578 PrkLckCtlMsgTxt_D_Rq 1;
BA_ "U_CDX706_MY2023_Rx" SG_ 578 PrkLckCtlMsgTxt_D_Rq 1;
BA_ "WakeupSignal" SG_ 578 PrkLckCtlAvail_T_Stat 1;
BA_ "U_CX727_MY2021_Rx" SG_ 578 BrkTrnShifLck_B_Stat 1;
BA_ "U_P702_MY2021_Rx" SG_ 578 BrkTrnShifLck_B_Stat 1;
BA_ "U_T6_MCA_MY2020_Rx" SG_ 578 BrkTrnShifLck_B_Stat 1;
BA_ "U_CD542_MY2021_Rx" SG_ 578 BrkTrnShifLck_B_Stat 1;
BA_ "U_U55X_MY2022_Rx" SG_ 578 BrkTrnShifLck_B_Stat 1;
BA_ "U_CD764_MY2022_Rx" SG_ 578 BrkTrnShifLck_B_Stat 1;
BA_ "U_CDX706_MY2023_Rx" SG_ 578 BrkTrnShifLck_B_Stat 1;
BA_ "U_CX727_MY2021_Rx" SG_ 578 DriverCrankingReq 1;
BA_ "U_P702_MY2021_Rx" SG_ 578 DriverCrankingReq 1;
BA_ "U_T6_MCA_MY2020_Rx" SG_ 578 DriverCrankingReq 1;
BA_ "U_CD542_MY2021_Rx" SG_ 578 DriverCrankingReq 1;
BA_ "U_U55X_MY2022_Rx" SG_ 578 DriverCrankingReq 1;
BA_ "U_CD764_MY2022_Rx" SG_ 578 DriverCrankingReq 1;
BA_ "U_CDX706_MY2023_Rx" SG_ 578 DriverCrankingReq 1;
BA_ "U_CX727_MY2021_Rx" SG_ 578 EngOff_T_Actl 1;
BA_ "U_P702_MY2021_Rx" SG_ 578 EngOff_T_Actl 1;
BA_ "U_T6_MCA_MY2020_Rx" SG_ 578 EngOff_T_Actl 1;
BA_ "U_CD542_MY2021_Rx" SG_ 578 EngOff_T_Actl 1;
BA_ "U_U55X_MY2022_Rx" SG_ 578 EngOff_T_Actl 1;
BA_ "U_CD764_MY2022_Rx" SG_ 578 EngOff_T_Actl 1;
BA_ "U_CDX706_MY2023_Rx" SG_ 578 EngOff_T_Actl 1;
BA_ "U_P702_MY2021_Rx" SG_ 578 DcacElPw_D_Rq 1;
BA_ "U_T6_MCA_MY2020_Rx" SG_ 578 DcacElPw_D_Rq 1;
BA_ "U_CD542_MY2021_Rx" SG_ 578 DcacElPw_D_Rq 1;
BA_ "U_U55X_MY2022_Rx" SG_ 578 DcacElPw_D_Rq 1;
BA_ "U_CDX706_MY2023_Rx" SG_ 578 DcacElPw_D_Rq 1;
BA_ "GenSigStartValueInteger" SG_ 578 BattULo_I_Actl 16383;
BA_ "GenSigStartValue" SG_ 578 BattULo_I_Actl 16383;
BA_ "U_CX727_MY2021_Rx" SG_ 578 BattULo_I_Actl 1;
BA_ "U_P702_MY2021_Rx" SG_ 578 BattULo_I_Actl 1;
BA_ "U_T6_MCA_MY2020_Rx" SG_ 578 BattULo_I_Actl 1;
BA_ "U_CD542_MY2021_Rx" SG_ 578 BattULo_I_Actl 1;
BA_ "U_U55X_MY2022_Rx" SG_ 578 BattULo_I_Actl 1;
BA_ "U_CD764_MY2022_Rx" SG_ 578 BattULo_I_Actl 1;
BA_ "U_CDX706_MY2023_Rx" SG_ 578 BattULo_I_Actl 1;
BA_ "WakeupSignal" SG_ 947 DimmingLvlEvnt_No_Actl 1;
BA_ "U_P702_MY2021_Rx" SG_ 947 DrStatDrvErrCnt_B_Stat 1;
BA_ "U_T6_MCA_MY2020_Rx" SG_ 947 DrStatDrvErrCnt_B_Stat 1;
BA_ "U_CD542_MY2021_Rx" SG_ 947 DrStatDrvErrCnt_B_Stat 1;
BA_ "U_U55X_MY2022_Rx" SG_ 947 DrStatDrvErrCnt_B_Stat 1;
BA_ "U_CD764_MY2022_Rx" SG_ 947 DrStatDrvErrCnt_B_Stat 1;
BA_ "U_CDX706_MY2023_Rx" SG_ 947 DrStatDrvErrCnt_B_Stat 1;
BA_ "WakeupSignal" SG_ 947 TurnLghtRight_D_Rq 1;
BA_ "U_CX727_MY2021_Rx" SG_ 947 TurnLghtRight_D_Rq 1;
BA_ "U_P702_MY2021_Rx" SG_ 947 TurnLghtRight_D_Rq 1;
BA_ "U_T6_MCA_MY2020_Rx" SG_ 947 TurnLghtRight_D_Rq 1;
BA_ "U_CD542_MY2021_Rx" SG_ 947 TurnLghtRight_D_Rq 1;
BA_ "U_U55X_MY2022_Rx" SG_ 947 TurnLghtRight_D_Rq 1;
BA_ "U_CD764_MY2022_Rx" SG_ 947 TurnLghtRight_D_Rq 1;
BA_ "U_CDX706_MY2023_Rx" SG_ 947 TurnLghtRight_D_Rq 1;
BA_ "U_CX727_MY2021_Rx" SG_ 947 FogLghtRearOn_B_Stat 1;
BA_ "U_P702_MY2021_Rx" SG_ 947 FogLghtRearOn_B_Stat 1;
BA_ "U_T6_MCA_MY2020_Rx" SG_ 947 FogLghtRearOn_B_Stat 1;
BA_ "U_CD542_MY2021_Rx" SG_ 947 FogLghtRearOn_B_Stat 1;
BA_ "U_U55X_MY2022_Rx" SG_ 947 FogLghtRearOn_B_Stat 1;
BA_ "U_CD764_MY2022_Rx" SG_ 947 FogLghtRearOn_B_Stat 1;
BA_ "U_CDX706_MY2023_Rx" SG_ 947 FogLghtRearOn_B_Stat 1;
BA_ "WakeupSignal" SG_ 947 Backlit_LED_Status 1;
BA_ "WakeupSignal" SG_ 947 TurnLghtLeft_D_Rq 1;
BA_ "U_CX727_MY2021_Rx" SG_ 947 TurnLghtLeft_D_Rq 1;
BA_ "U_P702_MY2021_Rx" SG_ 947 TurnLghtLeft_D_Rq 1;
BA_ "U_T6_MCA_MY2020_Rx" SG_ 947 TurnLghtLeft_D_Rq 1;
BA_ "U_CD542_MY2021_Rx" SG_ 947 TurnLghtLeft_D_Rq 1;
BA_ "U_U55X_MY2022_Rx" SG_ 947 TurnLghtLeft_D_Rq 1;
BA_ "U_CD764_MY2022_Rx" SG_ 947 TurnLghtLeft_D_Rq 1;
BA_ "U_CDX706_MY2023_Rx" SG_ 947 TurnLghtLeft_D_Rq 1;
BA_ "U_CX727_MY2021_Rx" SG_ 947 FogLghtFrontOn_B_Stat 1;
BA_ "U_P702_MY2021_Rx" SG_ 947 FogLghtFrontOn_B_Stat 1;
BA_ "U_T6_MCA_MY2020_Rx" SG_ 947 FogLghtFrontOn_B_Stat 1;
BA_ "U_CD542_MY2021_Rx" SG_ 947 FogLghtFrontOn_B_Stat 1;
BA_ "U_U55X_MY2022_Rx" SG_ 947 FogLghtFrontOn_B_Stat 1;
BA_ "U_CD764_MY2022_Rx" SG_ 947 FogLghtFrontOn_B_Stat 1;
BA_ "U_CDX706_MY2023_Rx" SG_ 947 FogLghtFrontOn_B_Stat 1;
BA_ "GenSigStartValueInteger" SG_ 947 IgnKeyType_D_Actl 14;
BA_ "GenSigStartValue" SG_ 947 IgnKeyType_D_Actl 14;
BA_ "U_CX727_MY2021_Rx" SG_ 947 IgnKeyType_D_Actl 1;
BA_ "U_P702_MY2021_Rx" SG_ 947 IgnKeyType_D_Actl 1;
BA_ "U_T6_MCA_MY2020_Rx" SG_ 947 IgnKeyType_D_Actl 1;
BA_ "U_CD542_MY2021_Rx" SG_ 947 IgnKeyType_D_Actl 1;
BA_ "U_U55X_MY2022_Rx" SG_ 947 IgnKeyType_D_Actl 1;
BA_ "U_CD764_MY2022_Rx" SG_ 947 IgnKeyType_D_Actl 1;
BA_ "U_CDX706_MY2023_Rx" SG_ 947 IgnKeyType_D_Actl 1;
BA_ "WakeupSignal" SG_ 947 Parklamp_Status 1;
BA_ "GenSigStartValueInteger" SG_ 947 Parklamp_Status 1;
BA_ "GenSigStartValue" SG_ 947 Parklamp_Status 1;
BA_ "U_T6_MCA_MY2020_Rx" SG_ 947 Parklamp_Status 1;
BA_ "U_CD542_MY2021_Rx" SG_ 947 Parklamp_Status 1;
BA_ "U_U55X_MY2022_Rx" SG_ 947 Parklamp_Status 1;
BA_ "U_CD764_MY2022_Rx" SG_ 947 Parklamp_Status 1;
BA_ "U_CDX706_MY2023_Rx" SG_ 947 Parklamp_Status 1;
BA_ "WakeupSignal" SG_ 947 Litval 1;
BA_ "U_CX727_MY2021_Rx" SG_ 947 Litval 1;
BA_ "U_P702_MY2021_Rx" SG_ 947 Litval 1;
BA_ "U_T6_MCA_MY2020_Rx" SG_ 947 Litval 1;
BA_ "U_CD542_MY2021_Rx" SG_ 947 Litval 1;
BA_ "U_U55X_MY2022_Rx" SG_ 947 Litval 1;
BA_ "U_CD764_MY2022_Rx" SG_ 947 Litval 1;
BA_ "U_CDX706_MY2023_Rx" SG_ 947 Litval 1;
BA_ "WakeupSignal" SG_ 947 Key_In_Ignition_Stat 1;
BA_ "U_CX727_MY2021_Rx" SG_ 947 Key_In_Ignition_Stat 1;
BA_ "U_P702_MY2021_Rx" SG_ 947 Key_In_Ignition_Stat 1;
BA_ "U_T6_MCA_MY2020_Rx" SG_ 947 Key_In_Ignition_Stat 1;
BA_ "U_CD542_MY2021_Rx" SG_ 947 Key_In_Ignition_Stat 1;
BA_ "U_U55X_MY2022_Rx" SG_ 947 Key_In_Ignition_Stat 1;
BA_ "U_CD764_MY2022_Rx" SG_ 947 Key_In_Ignition_Stat 1;
BA_ "WakeupSignal" SG_ 947 Ignition_Status 1;
BA_ "U_CX727_MY2021_Rx" SG_ 947 Ignition_Status 1;
BA_ "U_P702_MY2021_Rx" SG_ 947 Ignition_Status 1;
BA_ "U_T6_MCA_MY2020_Rx" SG_ 947 Ignition_Status 1;
BA_ "U_CD542_MY2021_Rx" SG_ 947 Ignition_Status 1;
BA_ "U_U55X_MY2022_Rx" SG_ 947 Ignition_Status 1;
BA_ "U_CD764_MY2022_Rx" SG_ 947 Ignition_Status 1;
BA_ "U_CDX706_MY2023_Rx" SG_ 947 Ignition_Status 1;
BA_ "WakeupSignal" SG_ 947 Dimming_Lvl 1;
BA_ "GenSigStartValueInteger" SG_ 947 Dimming_Lvl 12;
BA_ "GenSigStartValue" SG_ 947 Dimming_Lvl 12;
BA_ "U_T6_MCA_MY2020_Rx" SG_ 947 Dimming_Lvl 1;
BA_ "U_CD542_MY2021_Rx" SG_ 947 Dimming_Lvl 1;
BA_ "U_U55X_MY2022_Rx" SG_ 947 Dimming_Lvl 1;
BA_ "U_CD764_MY2022_Rx" SG_ 947 Dimming_Lvl 1;
BA_ "U_CDX706_MY2023_Rx" SG_ 947 Dimming_Lvl 1;
BA_ "WakeupSignal" SG_ 947 Day_Night_Status 1;
BA_ "U_P702_MY2021_Rx" SG_ 947 Day_Night_Status 1;
BA_ "U_T6_MCA_MY2020_Rx" SG_ 947 Day_Night_Status 1;
BA_ "U_CD542_MY2021_Rx" SG_ 947 Day_Night_Status 1;
BA_ "U_U55X_MY2022_Rx" SG_ 947 Day_Night_Status 1;
BA_ "U_CD764_MY2022_Rx" SG_ 947 Day_Night_Status 1;
BA_ "U_CDX706_MY2023_Rx" SG_ 947 Day_Night_Status 1;
BA_ "WakeupSignal" SG_ 947 Remote_Start_Status 1;
BA_ "U_T6_MCA_MY2020_Rx" SG_ 947 Remote_Start_Status 1;
BA_ "U_CD542_MY2021_Rx" SG_ 947 Remote_Start_Status 1;
BA_ "U_U55X_MY2022_Rx" SG_ 947 Remote_Start_Status 1;
BA_ "U_CD764_MY2022_Rx" SG_ 947 Remote_Start_Status 1;
BA_ "U_CDX706_MY2023_Rx" SG_ 947 Remote_Start_Status 1;
BA_ "WakeupSignal" SG_ 947 DrStatTgate_B_Actl 1;
BA_ "U_T6_MCA_MY2020_Rx" SG_ 947 DrStatTgate_B_Actl 1;
BA_ "U_CD542_MY2021_Rx" SG_ 947 DrStatTgate_B_Actl 1;
BA_ "U_U55X_MY2022_Rx" SG_ 947 DrStatTgate_B_Actl 1;
BA_ "U_CD764_MY2022_Rx" SG_ 947 DrStatTgate_B_Actl 1;
BA_ "U_CDX706_MY2023_Rx" SG_ 947 DrStatTgate_B_Actl 1;
BA_ "WakeupSignal" SG_ 947 DrStatRr_B_Actl 1;
BA_ "U_P702_MY2021_Rx" SG_ 947 DrStatRr_B_Actl 1;
BA_ "U_T6_MCA_MY2020_Rx" SG_ 947 DrStatRr_B_Actl 1;
BA_ "U_CD542_MY2021_Rx" SG_ 947 DrStatRr_B_Actl 1;
BA_ "U_U55X_MY2022_Rx" SG_ 947 DrStatRr_B_Actl 1;
BA_ "U_CD764_MY2022_Rx" SG_ 947 DrStatRr_B_Actl 1;
BA_ "U_CDX706_MY2023_Rx" SG_ 947 DrStatRr_B_Actl 1;
BA_ "WakeupSignal" SG_ 947 DrStatRl_B_Actl 1;
BA_ "U_P702_MY2021_Rx" SG_ 947 DrStatRl_B_Actl 1;
BA_ "U_T6_MCA_MY2020_Rx" SG_ 947 DrStatRl_B_Actl 1;
BA_ "U_CD542_MY2021_Rx" SG_ 947 DrStatRl_B_Actl 1;
BA_ "U_U55X_MY2022_Rx" SG_ 947 DrStatRl_B_Actl 1;
BA_ "U_CD764_MY2022_Rx" SG_ 947 DrStatRl_B_Actl 1;
BA_ "U_CDX706_MY2023_Rx" SG_ 947 DrStatRl_B_Actl 1;
BA_ "WakeupSignal" SG_ 947 DrStatPsngr_B_Actl 1;
BA_ "U_P702_MY2021_Rx" SG_ 947 DrStatPsngr_B_Actl 1;
BA_ "U_T6_MCA_MY2020_Rx" SG_ 947 DrStatPsngr_B_Actl 1;
BA_ "U_CD542_MY2021_Rx" SG_ 947 DrStatPsngr_B_Actl 1;
BA_ "U_U55X_MY2022_Rx" SG_ 947 DrStatPsngr_B_Actl 1;
BA_ "U_CD764_MY2022_Rx" SG_ 947 DrStatPsngr_B_Actl 1;
BA_ "U_CDX706_MY2023_Rx" SG_ 947 DrStatPsngr_B_Actl 1;
BA_ "WakeupSignal" SG_ 947 DrStatInnrTgate_B_Actl 1;
BA_ "U_T6_MCA_MY2020_Rx" SG_ 947 DrStatInnrTgate_B_Actl 1;
BA_ "U_CD542_MY2021_Rx" SG_ 947 DrStatInnrTgate_B_Actl 1;
BA_ "U_U55X_MY2022_Rx" SG_ 947 DrStatInnrTgate_B_Actl 1;
BA_ "U_CD764_MY2022_Rx" SG_ 947 DrStatInnrTgate_B_Actl 1;
BA_ "U_CDX706_MY2023_Rx" SG_ 947 DrStatInnrTgate_B_Actl 1;
BA_ "WakeupSignal" SG_ 947 DrStatHood_B_Actl 1;
BA_ "WakeupSignal" SG_ 947 DrStatDrv_B_Actl 1;
BA_ "U_CX727_MY2021_Rx" SG_ 947 DrStatDrv_B_Actl 1;
BA_ "U_P702_MY2021_Rx" SG_ 947 DrStatDrv_B_Actl 1;
BA_ "U_T6_MCA_MY2020_Rx" SG_ 947 DrStatDrv_B_Actl 1;
BA_ "U_CD542_MY2021_Rx" SG_ 947 DrStatDrv_B_Actl 1;
BA_ "U_U55X_MY2022_Rx" SG_ 947 DrStatDrv_B_Actl 1;
BA_ "U_CD764_MY2022_Rx" SG_ 947 DrStatDrv_B_Actl 1;
BA_ "U_CDX706_MY2023_Rx" SG_ 947 DrStatDrv_B_Actl 1;
BA_ "WakeupSignal" SG_ 947 PrkBrkActv_B_Actl 1;
BA_ "ContentDependant" SG_ 947 PrkBrkActv_B_Actl 1;
BA_ "U_CX727_MY2021_Rx" SG_ 947 PrkBrkActv_B_Actl 1;
BA_ "U_P702_MY2021_Rx" SG_ 947 PrkBrkActv_B_Actl 1;
BA_ "U_T6_MCA_MY2020_Rx" SG_ 947 PrkBrkActv_B_Actl 1;
BA_ "U_CD542_MY2021_Rx" SG_ 947 PrkBrkActv_B_Actl 1;
BA_ "U_U55X_MY2022_Rx" SG_ 947 PrkBrkActv_B_Actl 1;
BA_ "U_CD764_MY2022_Rx" SG_ 947 PrkBrkActv_B_Actl 1;
BA_ "U_CDX706_MY2023_Rx" SG_ 947 PrkBrkActv_B_Actl 1;
BA_ "U_CX727_MY2021_Rx" SG_ 947 LifeCycMde_D_Actl 1;
BA_ "U_P702_MY2021_Rx" SG_ 947 LifeCycMde_D_Actl 1;
BA_ "U_T6_MCA_MY2020_Rx" SG_ 947 LifeCycMde_D_Actl 1;
BA_ "U_CD542_MY2021_Rx" SG_ 947 LifeCycMde_D_Actl 1;
BA_ "U_U55X_MY2022_Rx" SG_ 947 LifeCycMde_D_Actl 1;
BA_ "U_CD764_MY2022_Rx" SG_ 947 LifeCycMde_D_Actl 1;
BA_ "U_CDX706_MY2023_Rx" SG_ 947 LifeCycMde_D_Actl 1;
BA_ "WakeupSignal" SG_ 947 Delay_Accy 1;
BA_ "WakeupSignal" SG_ 947 CrashEvnt_D_Stat 1;
BA_ "GenSigStartValueInteger" SG_ 947 CrashEvnt_D_Stat 3;
BA_ "GenSigStartValue" SG_ 947 CrashEvnt_D_Stat 3;
BA_ "GenSigStartValueInteger" SG_ 1084 BattULoChrg_URate_RqMx 5;
BA_ "GenSigStartValue" SG_ 1084 BattULoChrg_URate_RqMx 5;
BA_ "U_CX727_MY2021_Rx" SG_ 1084 BattULoChrg_URate_RqMx 1;
BA_ "U_P702_MY2021_Rx" SG_ 1084 BattULoChrg_URate_RqMx 1;
BA_ "U_T6_MCA_MY2020_Rx" SG_ 1084 BattULoChrg_URate_RqMx 1;
BA_ "U_CD542_MY2021_Rx" SG_ 1084 BattULoChrg_URate_RqMx 1;
BA_ "U_U55X_MY2022_Rx" SG_ 1084 BattULoChrg_URate_RqMx 1;
BA_ "U_CD764_MY2022_Rx" SG_ 1084 BattULoChrg_URate_RqMx 1;
BA_ "U_CDX706_MY2023_Rx" SG_ 1084 BattULoChrg_URate_RqMx 1;
BA_ "GenSigStartValueInteger" SG_ 1084 BattULoChrg_U_RqMx 34;
BA_ "GenSigStartValue" SG_ 1084 BattULoChrg_U_RqMx 34;
BA_ "U_P702_MY2021_Rx" SG_ 1084 BattULoChrg_U_RqMx 1;
BA_ "U_T6_MCA_MY2020_Rx" SG_ 1084 BattULoChrg_U_RqMx 1;
BA_ "U_CD542_MY2021_Rx" SG_ 1084 BattULoChrg_U_RqMx 1;
BA_ "U_U55X_MY2022_Rx" SG_ 1084 BattULoChrg_U_RqMx 1;
BA_ "U_CD764_MY2022_Rx" SG_ 1084 BattULoChrg_U_RqMx 1;
BA_ "U_CDX706_MY2023_Rx" SG_ 1084 BattULoChrg_U_RqMx 1;
BA_ "U_P702_MY2021_Rx" SG_ 1084 BattULoChrg_U_RqMn 1;
BA_ "U_T6_MCA_MY2020_Rx" SG_ 1084 BattULoChrg_U_RqMn 1;
BA_ "U_CD542_MY2021_Rx" SG_ 1084 BattULoChrg_U_RqMn 1;
BA_ "U_U55X_MY2022_Rx" SG_ 1084 BattULoChrg_U_RqMn 1;
BA_ "U_CD764_MY2022_Rx" SG_ 1084 BattULoChrg_U_RqMn 1;
BA_ "U_CDX706_MY2023_Rx" SG_ 1084 BattULoChrg_U_RqMn 1;
BA_ "U_P702_MY2021_Rx" SG_ 1084 BattULoState_D_Qlty 1;
BA_ "U_T6_MCA_MY2020_Rx" SG_ 1084 BattULoState_D_Qlty 1;
BA_ "U_CD542_MY2021_Rx" SG_ 1084 BattULoState_D_Qlty 1;
BA_ "U_U55X_MY2022_Rx" SG_ 1084 BattULoState_D_Qlty 1;
BA_ "U_CD764_MY2022_Rx" SG_ 1084 BattULoState_D_Qlty 1;
BA_ "U_CDX706_MY2023_Rx" SG_ 1084 BattULoState_D_Qlty 1;
BA_ "U_P702_MY2021_Rx" SG_ 1084 BSFault 1;
BA_ "U_T6_MCA_MY2020_Rx" SG_ 1084 BSFault 1;
BA_ "U_CD542_MY2021_Rx" SG_ 1084 BSFault 1;
BA_ "U_U55X_MY2022_Rx" SG_ 1084 BSFault 1;
BA_ "U_CD764_MY2022_Rx" SG_ 1084 BSFault 1;
BA_ "U_CDX706_MY2023_Rx" SG_ 1084 BSFault 1;
BA_ "GenSigStartValueInteger" SG_ 1084 BattULo2_Te_Actl 127;
BA_ "GenSigStartValue" SG_ 1084 BattULo2_Te_Actl 127;
BA_ "U_CX727_MY2021_Rx" SG_ 1084 BattULo2_Te_Actl 1;
BA_ "U_P702_MY2021_Rx" SG_ 1084 BattULo2_Te_Actl 1;
BA_ "U_T6_MCA_MY2020_Rx" SG_ 1084 BattULo2_Te_Actl 1;
BA_ "U_CD542_MY2021_Rx" SG_ 1084 BattULo2_Te_Actl 1;
BA_ "U_U55X_MY2022_Rx" SG_ 1084 BattULo2_Te_Actl 1;
BA_ "U_CD764_MY2022_Rx" SG_ 1084 BattULo2_Te_Actl 1;
BA_ "U_CDX706_MY2023_Rx" SG_ 1084 BattULo2_Te_Actl 1;
BA_ "U_CX727_MY2021_Rx" SG_ 1084 BSBattSOC 1;
BA_ "U_P702_MY2021_Rx" SG_ 1084 BSBattSOC 1;
BA_ "U_T6_MCA_MY2020_Rx" SG_ 1084 BSBattSOC 1;
BA_ "U_CD542_MY2021_Rx" SG_ 1084 BSBattSOC 1;
BA_ "U_U55X_MY2022_Rx" SG_ 1084 BSBattSOC 1;
BA_ "U_CD764_MY2022_Rx" SG_ 1084 BSBattSOC 1;
BA_ "U_CDX706_MY2023_Rx" SG_ 1084 BSBattSOC 1;
BA_ "GenSigStartValueInteger" SG_ 1084 BSBattQDeltaRideAh 12800;
BA_ "U_P702_MY2021_Rx" SG_ 1084 BSBattQDeltaRideAh 1;
BA_ "U_T6_MCA_MY2020_Rx" SG_ 1084 BSBattQDeltaRideAh 1;
BA_ "U_CD542_MY2021_Rx" SG_ 1084 BSBattQDeltaRideAh 1;
BA_ "U_U55X_MY2022_Rx" SG_ 1084 BSBattQDeltaRideAh 1;
BA_ "U_CD764_MY2022_Rx" SG_ 1084 BSBattQDeltaRideAh 1;
BA_ "U_CDX706_MY2023_Rx" SG_ 1084 BSBattQDeltaRideAh 1;
BA_ "U_P702_MY2021_Rx" SG_ 1084 BSBattQCapAh 1;
BA_ "U_T6_MCA_MY2020_Rx" SG_ 1084 BSBattQCapAh 1;
BA_ "U_CD542_MY2021_Rx" SG_ 1084 BSBattQCapAh 1;
BA_ "U_U55X_MY2022_Rx" SG_ 1084 BSBattQCapAh 1;
BA_ "U_CD764_MY2022_Rx" SG_ 1084 BSBattQCapAh 1;
BA_ "U_CDX706_MY2023_Rx" SG_ 1084 BSBattQCapAh 1;
BA_ "U_P702_MY2021_Rx" SG_ 1068 EngStrtInhbt_B_RqBatt 1;
BA_ "U_T6_MCA_MY2020_Rx" SG_ 1068 EngStrtInhbt_B_RqBatt 1;
BA_ "U_CD542_MY2021_Rx" SG_ 1068 EngStrtInhbt_B_RqBatt 1;
BA_ "U_U55X_MY2022_Rx" SG_ 1068 EngStrtInhbt_B_RqBatt 1;
BA_ "U_CD764_MY2022_Rx" SG_ 1068 EngStrtInhbt_B_RqBatt 1;
BA_ "U_CDX706_MY2023_Rx" SG_ 1068 EngStrtInhbt_B_RqBatt 1;
BA_ "U_P702_MY2021_Rx" SG_ 1068 BattULoChrg_D_Rq 1;
BA_ "U_T6_MCA_MY2020_Rx" SG_ 1068 BattULoChrg_D_Rq 1;
BA_ "U_CD542_MY2021_Rx" SG_ 1068 BattULoChrg_D_Rq 1;
BA_ "U_U55X_MY2022_Rx" SG_ 1068 BattULoChrg_D_Rq 1;
BA_ "U_CD764_MY2022_Rx" SG_ 1068 BattULoChrg_D_Rq 1;
BA_ "U_CDX706_MY2023_Rx" SG_ 1068 BattULoChrg_D_Rq 1;
BA_ "WakeupSignal" SG_ 1068 PwSysULoFalt_D_Stat 1;
BA_ "U_CX727_MY2021_Rx" SG_ 1068 PwSysULoFalt_D_Stat 1;
BA_ "U_CD542_MY2021_Rx" SG_ 1068 PwSysULoFalt_D_Stat 1;
BA_ "U_CD764_MY2022_Rx" SG_ 1068 PwSysULoFalt_D_Stat 1;
BA_ "WakeupSignal" SG_ 1068 Shed_Feature_Group_ID 1;
BA_ "U_CX727_MY2021_Rx" SG_ 1068 Shed_Feature_Group_ID 1;
BA_ "U_P702_MY2021_Rx" SG_ 1068 Shed_Feature_Group_ID 1;
BA_ "U_T6_MCA_MY2020_Rx" SG_ 1068 Shed_Feature_Group_ID 1;
BA_ "U_CD542_MY2021_Rx" SG_ 1068 Shed_Feature_Group_ID 1;
BA_ "U_U55X_MY2022_Rx" SG_ 1068 Shed_Feature_Group_ID 1;
BA_ "U_CD764_MY2022_Rx" SG_ 1068 Shed_Feature_Group_ID 1;
BA_ "U_CDX706_MY2023_Rx" SG_ 1068 Shed_Feature_Group_ID 1;
BA_ "WakeupSignal" SG_ 1068 Shed_Level_Req 1;
BA_ "U_CX727_MY2021_Rx" SG_ 1068 Shed_Level_Req 1;
BA_ "U_P702_MY2021_Rx" SG_ 1068 Shed_Level_Req 1;
BA_ "U_T6_MCA_MY2020_Rx" SG_ 1068 Shed_Level_Req 1;
BA_ "U_CD542_MY2021_Rx" SG_ 1068 Shed_Level_Req 1;
BA_ "U_U55X_MY2022_Rx" SG_ 1068 Shed_Level_Req 1;
BA_ "U_CD764_MY2022_Rx" SG_ 1068 Shed_Level_Req 1;
BA_ "U_CDX706_MY2023_Rx" SG_ 1068 Shed_Level_Req 1;
BA_ "U_CX727_MY2021_Rx" SG_ 1068 BattULoSrvc_T_Actl 1;
BA_ "U_CD542_MY2021_Rx" SG_ 1068 BattULoSrvc_T_Actl 1;
BA_ "U_CDX706_MY2023_Rx" SG_ 1068 BattULoSrvc_T_Actl 1;
BA_ "U_P702_MY2021_Rx" SG_ 1068 ULoRgenTestMde_B_Rq 1;
BA_ "U_T6_MCA_MY2020_Rx" SG_ 1068 ULoRgenTestMde_B_Rq 1;
BA_ "U_CD542_MY2021_Rx" SG_ 1068 ULoRgenTestMde_B_Rq 1;
BA_ "U_U55X_MY2022_Rx" SG_ 1068 ULoRgenTestMde_B_Rq 1;
BA_ "U_CD764_MY2022_Rx" SG_ 1068 ULoRgenTestMde_B_Rq 1;
BA_ "U_CDX706_MY2023_Rx" SG_ 1068 ULoRgenTestMde_B_Rq 1;
BA_ "U_P702_MY2021_Rx" SG_ 1068 ChargeMode 1;
BA_ "U_T6_MCA_MY2020_Rx" SG_ 1068 ChargeMode 1;
BA_ "U_CD542_MY2021_Rx" SG_ 1068 ChargeMode 1;
BA_ "U_U55X_MY2022_Rx" SG_ 1068 ChargeMode 1;
BA_ "U_CD764_MY2022_Rx" SG_ 1068 ChargeMode 1;
BA_ "U_CDX706_MY2023_Rx" SG_ 1068 ChargeMode 1;
BA_ "U_P702_MY2021_Rx" SG_ 1068 PeriodicElLoad_B_Stat 1;
BA_ "U_T6_MCA_MY2020_Rx" SG_ 1068 PeriodicElLoad_B_Stat 1;
BA_ "ContentDependant" SG_ 524 PrplWhlTotTqRqMxAwd_No_Cs 1;
BA_ "MetaData" SG_ 524 PrplWhlTotTqRqMxAwd_No_Cs 1;
BA_ "U_T6_MCA_MY2020_Rx" SG_ 524 PrplWhlTotTqRqMxAwd_No_Cs 1;
BA_ "U_CDX706_MY2023_Rx" SG_ 524 PrplWhlTotTqRqMxAwd_No_Cs 1;
BA_ "U_T6_MCA_MY2020_Tx" SG_ 524 PrplWhlTotTqRqMxAwd_No_Cs 1;
BA_ "U_U55X_MY2022_Tx" SG_ 524 PrplWhlTotTqRqMxAwd_No_Cs 1;
BA_ "GenSigStartValueInteger" SG_ 524 PrplWhlTot_Tq_RqMxAwd 65535;
BA_ "GenSigStartValue" SG_ 524 PrplWhlTot_Tq_RqMxAwd 65535;
BA_ "U_T6_MCA_MY2020_Rx" SG_ 524 PrplWhlTot_Tq_RqMxAwd 1;
BA_ "U_CDX706_MY2023_Rx" SG_ 524 PrplWhlTot_Tq_RqMxAwd 1;
BA_ "U_T6_MCA_MY2020_Tx" SG_ 524 PrplWhlTot_Tq_RqMxAwd 1;
BA_ "U_U55X_MY2022_Tx" SG_ 524 PrplWhlTot_Tq_RqMxAwd 1;
BA_ "ContentDependant" SG_ 524 PrplWhlTotTqRqMxAwd_No_Cnt 1;
BA_ "MetaData" SG_ 524 PrplWhlTotTqRqMxAwd_No_Cnt 1;
BA_ "U_T6_MCA_MY2020_Rx" SG_ 524 PrplWhlTotTqRqMxAwd_No_Cnt 1;
BA_ "U_CDX706_MY2023_Rx" SG_ 524 PrplWhlTotTqRqMxAwd_No_Cnt 1;
BA_ "U_T6_MCA_MY2020_Tx" SG_ 524 PrplWhlTotTqRqMxAwd_No_Cnt 1;
BA_ "U_U55X_MY2022_Tx" SG_ 524 PrplWhlTotTqRqMxAwd_No_Cnt 1;
BA_ "GenSigStartValueInteger" SG_ 146 VehVert2_A_Actl 8190;
BA_ "GenSigStartValue" SG_ 146 VehVert2_A_Actl 8190;
BA_ "U_CX727_MY2021_Rx" SG_ 146 VehVert2_A_Actl 1;
BA_ "U_P702_MY2021_Rx" SG_ 146 VehVert2_A_Actl 1;
BA_ "U_T6_MCA_MY2020_Rx" SG_ 146 VehVert2_A_Actl 1;
BA_ "U_CD542_MY2021_Rx" SG_ 146 VehVert2_A_Actl 1;
BA_ "U_U55X_MY2022_Rx" SG_ 146 VehVert2_A_Actl 1;
BA_ "U_CD764_MY2022_Rx" SG_ 146 VehVert2_A_Actl 1;
BA_ "U_CDX706_MY2023_Rx" SG_ 146 VehVert2_A_Actl 1;
BA_ "MetaData" SG_ 146 VehLatLongVertA_No_Cs 1;
BA_ "U_CX727_MY2021_Rx" SG_ 146 VehLatLongVertA_No_Cs 1;
BA_ "U_P702_MY2021_Rx" SG_ 146 VehLatLongVertA_No_Cs 1;
BA_ "U_T6_MCA_MY2020_Rx" SG_ 146 VehLatLongVertA_No_Cs 1;
BA_ "U_CD542_MY2021_Rx" SG_ 146 VehLatLongVertA_No_Cs 1;
BA_ "U_U55X_MY2022_Rx" SG_ 146 VehLatLongVertA_No_Cs 1;
BA_ "U_CD764_MY2022_Rx" SG_ 146 VehLatLongVertA_No_Cs 1;
BA_ "U_CDX706_MY2023_Rx" SG_ 146 VehLatLongVertA_No_Cs 1;
BA_ "MetaData" SG_ 146 VehLatLongVert_No_Cnt 1;
BA_ "U_CX727_MY2021_Rx" SG_ 146 VehLatLongVert_No_Cnt 1;
BA_ "U_P702_MY2021_Rx" SG_ 146 VehLatLongVert_No_Cnt 1;
BA_ "U_T6_MCA_MY2020_Rx" SG_ 146 VehLatLongVert_No_Cnt 1;
BA_ "U_CD542_MY2021_Rx" SG_ 146 VehLatLongVert_No_Cnt 1;
BA_ "U_U55X_MY2022_Rx" SG_ 146 VehLatLongVert_No_Cnt 1;
BA_ "U_CD764_MY2022_Rx" SG_ 146 VehLatLongVert_No_Cnt 1;
BA_ "U_CDX706_MY2023_Rx" SG_ 146 VehLatLongVert_No_Cnt 1;
BA_ "GenSigStartValueInteger" SG_ 146 VehLong2_A_Actl 8190;
BA_ "GenSigStartValue" SG_ 146 VehLong2_A_Actl 8190;
BA_ "U_CX727_MY2021_Rx" SG_ 146 VehLong2_A_Actl 1;
BA_ "U_P702_MY2021_Rx" SG_ 146 VehLong2_A_Actl 1;
BA_ "U_T6_MCA_MY2020_Rx" SG_ 146 VehLong2_A_Actl 1;
BA_ "U_CD542_MY2021_Rx" SG_ 146 VehLong2_A_Actl 1;
BA_ "U_U55X_MY2022_Rx" SG_ 146 VehLong2_A_Actl 1;
BA_ "U_CD764_MY2022_Rx" SG_ 146 VehLong2_A_Actl 1;
BA_ "U_CDX706_MY2023_Rx" SG_ 146 VehLong2_A_Actl 1;
BA_ "GenSigStartValueInteger" SG_ 146 VehLat2_A_Actl 8190;
BA_ "GenSigStartValue" SG_ 146 VehLat2_A_Actl 8190;
BA_ "U_CX727_MY2021_Rx" SG_ 146 VehLat2_A_Actl 1;
BA_ "U_P702_MY2021_Rx" SG_ 146 VehLat2_A_Actl 1;
BA_ "U_T6_MCA_MY2020_Rx" SG_ 146 VehLat2_A_Actl 1;
BA_ "U_CD542_MY2021_Rx" SG_ 146 VehLat2_A_Actl 1;
BA_ "U_U55X_MY2022_Rx" SG_ 146 VehLat2_A_Actl 1;
BA_ "U_CD764_MY2022_Rx" SG_ 146 VehLat2_A_Actl 1;
BA_ "U_CDX706_MY2023_Rx" SG_ 146 VehLat2_A_Actl 1;
BA_ "GenSigStartValueInteger" SG_ 146 VehVertAActl_D_Qf 1;
BA_ "MetaData" SG_ 146 VehVertAActl_D_Qf 1;
BA_ "GenSigStartValue" SG_ 146 VehVertAActl_D_Qf 1;
BA_ "U_CX727_MY2021_Rx" SG_ 146 VehVertAActl_D_Qf 1;
BA_ "U_P702_MY2021_Rx" SG_ 146 VehVertAActl_D_Qf 1;
BA_ "U_T6_MCA_MY2020_Rx" SG_ 146 VehVertAActl_D_Qf 1;
BA_ "U_CD542_MY2021_Rx" SG_ 146 VehVertAActl_D_Qf 1;
BA_ "U_U55X_MY2022_Rx" SG_ 146 VehVertAActl_D_Qf 1;
BA_ "U_CD764_MY2022_Rx" SG_ 146 VehVertAActl_D_Qf 1;
BA_ "U_CDX706_MY2023_Rx" SG_ 146 VehVertAActl_D_Qf 1;
BA_ "GenSigStartValueInteger" SG_ 146 VehLongAActl_D_Qf 1;
BA_ "MetaData" SG_ 146 VehLongAActl_D_Qf 1;
BA_ "GenSigStartValue" SG_ 146 VehLongAActl_D_Qf 1;
BA_ "U_CX727_MY2021_Rx" SG_ 146 VehLongAActl_D_Qf 1;
BA_ "U_P702_MY2021_Rx" SG_ 146 VehLongAActl_D_Qf 1;
BA_ "U_T6_MCA_MY2020_Rx" SG_ 146 VehLongAActl_D_Qf 1;
BA_ "U_CD542_MY2021_Rx" SG_ 146 VehLongAActl_D_Qf 1;
BA_ "U_U55X_MY2022_Rx" SG_ 146 VehLongAActl_D_Qf 1;
BA_ "U_CD764_MY2022_Rx" SG_ 146 VehLongAActl_D_Qf 1;
BA_ "U_CDX706_MY2023_Rx" SG_ 146 VehLongAActl_D_Qf 1;
BA_ "GenSigStartValueInteger" SG_ 146 VehLatAActl_D_Qf 1;
BA_ "MetaData" SG_ 146 VehLatAActl_D_Qf 1;
BA_ "GenSigStartValue" SG_ 146 VehLatAActl_D_Qf 1;
BA_ "U_CX727_MY2021_Rx" SG_ 146 VehLatAActl_D_Qf 1;
BA_ "U_P702_MY2021_Rx" SG_ 146 VehLatAActl_D_Qf 1;
BA_ "U_T6_MCA_MY2020_Rx" SG_ 146 VehLatAActl_D_Qf 1;
BA_ "U_CD542_MY2021_Rx" SG_ 146 VehLatAActl_D_Qf 1;
BA_ "U_U55X_MY2022_Rx" SG_ 146 VehLatAActl_D_Qf 1;
BA_ "U_CD764_MY2022_Rx" SG_ 146 VehLatAActl_D_Qf 1;
BA_ "U_CDX706_MY2023_Rx" SG_ 146 VehLatAActl_D_Qf 1;
BA_ "GenSigSendType" SG_ 1892 TesterPhysicalReqCCM 3;
BA_ "U_T6_MCA_MY2020_Rx" SG_ 1892 TesterPhysicalReqCCM 1;
BA_ "U_CD542_MY2021_Rx" SG_ 1892 TesterPhysicalReqCCM 1;
BA_ "U_U55X_MY2022_Rx" SG_ 1892 TesterPhysicalReqCCM 1;
BA_ "U_CD764_MY2022_Rx" SG_ 1892 TesterPhysicalReqCCM 1;
BA_ "U_CDX706_MY2023_Rx" SG_ 1892 TesterPhysicalReqCCM 1;
BA_ "GenSigSendType" SG_ 1798 TesterPhysicalReqIPMA 3;
BA_ "U_T6_MCA_MY2020_Rx" SG_ 1798 TesterPhysicalReqIPMA 1;
BA_ "U_CD542_MY2021_Rx" SG_ 1798 TesterPhysicalReqIPMA 1;
BA_ "U_U55X_MY2022_Rx" SG_ 1798 TesterPhysicalReqIPMA 1;
BA_ "U_CD764_MY2022_Rx" SG_ 1798 TesterPhysicalReqIPMA 1;
BA_ "U_CDX706_MY2023_Rx" SG_ 1798 TesterPhysicalReqIPMA 1;
BA_ "GenSigSendType" SG_ 1900 TesterPhysicalResCCM 3;
BA_ "U_T6_MCA_MY2020_Tx" SG_ 1900 TesterPhysicalResCCM 1;
BA_ "U_CD542_MY2021_Tx" SG_ 1900 TesterPhysicalResCCM 1;
BA_ "U_U55X_MY2022_Tx" SG_ 1900 TesterPhysicalResCCM 1;
BA_ "U_CD764_MY2022_Tx" SG_ 1900 TesterPhysicalResCCM 1;
BA_ "U_CDX706_MY2023_Tx" SG_ 1900 TesterPhysicalResCCM 1;
BA_ "GenSigSendType" SG_ 1806 TesterPhysicalResIPMA 3;
BA_ "U_T6_MCA_MY2020_Tx" SG_ 1806 TesterPhysicalResIPMA 1;
BA_ "U_CD542_MY2021_Tx" SG_ 1806 TesterPhysicalResIPMA 1;
BA_ "U_U55X_MY2022_Tx" SG_ 1806 TesterPhysicalResIPMA 1;
BA_ "U_CD764_MY2022_Tx" SG_ 1806 TesterPhysicalResIPMA 1;
BA_ "U_CDX706_MY2023_Tx" SG_ 1806 TesterPhysicalResIPMA 1;
BA_ "U_CX727_MY2021_Rx" SG_ 1010 LightRng_L_Max 1;
BA_ "U_P702_MY2021_Rx" SG_ 1010 LightRng_L_Max 1;
BA_ "U_U55X_MY2022_Rx" SG_ 1010 LightRng_L_Max 1;
BA_ "U_CD764_MY2022_Rx" SG_ 1010 LightRng_L_Max 1;
BA_ "U_T6_MCA_MY2020_Tx" SG_ 1010 LightRng_L_Max 1;
BA_ "U_CD542_MY2021_Tx" SG_ 1010 LightRng_L_Max 1;
BA_ "U_U55X_MY2022_Tx" SG_ 1010 LightRng_L_Max 1;
BA_ "U_CD764_MY2022_Tx" SG_ 1010 LightRng_L_Max 1;
BA_ "U_CDX706_MY2023_Tx" SG_ 1010 LightRng_L_Max 1;
BA_ "GenSigStartValueInteger" SG_ 1010 LightPathOffst_L_Actl 512;
BA_ "U_CX727_MY2021_Rx" SG_ 1010 LightPathOffst_L_Actl 1;
BA_ "U_P702_MY2021_Rx" SG_ 1010 LightPathOffst_L_Actl 1;
BA_ "U_U55X_MY2022_Rx" SG_ 1010 LightPathOffst_L_Actl 1;
BA_ "U_CD764_MY2022_Rx" SG_ 1010 LightPathOffst_L_Actl 1;
BA_ "U_T6_MCA_MY2020_Tx" SG_ 1010 LightPathOffst_L_Actl 1;
BA_ "U_CD542_MY2021_Tx" SG_ 1010 LightPathOffst_L_Actl 1;
BA_ "U_U55X_MY2022_Tx" SG_ 1010 LightPathOffst_L_Actl 1;
BA_ "U_CD764_MY2022_Tx" SG_ 1010 LightPathOffst_L_Actl 1;
BA_ "U_CDX706_MY2023_Tx" SG_ 1010 LightPathOffst_L_Actl 1;
BA_ "GenSigStartValueInteger" SG_ 1010 LightPath_An_Actl 1000;
BA_ "U_CX727_MY2021_Rx" SG_ 1010 LightPath_An_Actl 1;
BA_ "U_P702_MY2021_Rx" SG_ 1010 LightPath_An_Actl 1;
BA_ "U_U55X_MY2022_Rx" SG_ 1010 LightPath_An_Actl 1;
BA_ "U_CD764_MY2022_Rx" SG_ 1010 LightPath_An_Actl 1;
BA_ "U_T6_MCA_MY2020_Tx" SG_ 1010 LightPath_An_Actl 1;
BA_ "U_CD542_MY2021_Tx" SG_ 1010 LightPath_An_Actl 1;
BA_ "U_U55X_MY2022_Tx" SG_ 1010 LightPath_An_Actl 1;
BA_ "U_CD764_MY2022_Tx" SG_ 1010 LightPath_An_Actl 1;
BA_ "U_CDX706_MY2023_Tx" SG_ 1010 LightPath_An_Actl 1;
BA_ "GenSigStartValueInteger" SG_ 1010 LightCurv_NoRate_Actl 4096;
BA_ "U_CX727_MY2021_Rx" SG_ 1010 LightCurv_NoRate_Actl 1;
BA_ "U_P702_MY2021_Rx" SG_ 1010 LightCurv_NoRate_Actl 1;
BA_ "U_U55X_MY2022_Rx" SG_ 1010 LightCurv_NoRate_Actl 1;
BA_ "U_CD764_MY2022_Rx" SG_ 1010 LightCurv_NoRate_Actl 1;
BA_ "U_T6_MCA_MY2020_Tx" SG_ 1010 LightCurv_NoRate_Actl 1;
BA_ "U_CD542_MY2021_Tx" SG_ 1010 LightCurv_NoRate_Actl 1;
BA_ "U_U55X_MY2022_Tx" SG_ 1010 LightCurv_NoRate_Actl 1;
BA_ "U_CD764_MY2022_Tx" SG_ 1010 LightCurv_NoRate_Actl 1;
BA_ "U_CDX706_MY2023_Tx" SG_ 1010 LightCurv_NoRate_Actl 1;
BA_ "GenSigStartValueInteger" SG_ 1010 LightCurv_No_Actl 1000;
BA_ "U_CX727_MY2021_Rx" SG_ 1010 LightCurv_No_Actl 1;
BA_ "U_P702_MY2021_Rx" SG_ 1010 LightCurv_No_Actl 1;
BA_ "U_U55X_MY2022_Rx" SG_ 1010 LightCurv_No_Actl 1;
BA_ "U_CD764_MY2022_Rx" SG_ 1010 LightCurv_No_Actl 1;
BA_ "U_T6_MCA_MY2020_Tx" SG_ 1010 LightCurv_No_Actl 1;
BA_ "U_CD542_MY2021_Tx" SG_ 1010 LightCurv_No_Actl 1;
BA_ "U_U55X_MY2022_Tx" SG_ 1010 LightCurv_No_Actl 1;
BA_ "U_CD764_MY2022_Tx" SG_ 1010 LightCurv_No_Actl 1;
BA_ "U_CDX706_MY2023_Tx" SG_ 1010 LightCurv_No_Actl 1;
BA_ "U_CD764_MY2022_Rx" SG_ 1010 MbdblActv_B_RqAdas 1;
BA_ "U_T6_MCA_MY2020_Tx" SG_ 1010 MbdblActv_B_RqAdas 1;
BA_ "U_U55X_MY2022_Tx" SG_ 1010 MbdblActv_B_RqAdas 1;
BA_ "U_CDX706_MY2023_Tx" SG_ 1010 MbdblActv_B_RqAdas 1;
BA_ "U_U55X_MY2022_Rx" SG_ 1010 CbdblActv_B_RqAdas 1;
BA_ "U_CD764_MY2022_Rx" SG_ 1010 CbdblActv_B_RqAdas 1;
BA_ "U_T6_MCA_MY2020_Tx" SG_ 1010 CbdblActv_B_RqAdas 1;
BA_ "U_CD542_MY2021_Tx" SG_ 1010 CbdblActv_B_RqAdas 1;
BA_ "U_U55X_MY2022_Tx" SG_ 1010 CbdblActv_B_RqAdas 1;
BA_ "U_CD764_MY2022_Tx" SG_ 1010 CbdblActv_B_RqAdas 1;
BA_ "U_CDX706_MY2023_Tx" SG_ 1010 CbdblActv_B_RqAdas 1;
BA_ "U_U55X_MY2022_Rx" SG_ 1010 AdbUrbanArea_B_Stat 1;
BA_ "U_CD764_MY2022_Rx" SG_ 1010 AdbUrbanArea_B_Stat 1;
BA_ "U_T6_MCA_MY2020_Tx" SG_ 1010 AdbUrbanArea_B_Stat 1;
BA_ "U_CD542_MY2021_Tx" SG_ 1010 AdbUrbanArea_B_Stat 1;
BA_ "U_U55X_MY2022_Tx" SG_ 1010 AdbUrbanArea_B_Stat 1;
BA_ "U_CD764_MY2022_Tx" SG_ 1010 AdbUrbanArea_B_Stat 1;
BA_ "U_CDX706_MY2023_Tx" SG_ 1010 AdbUrbanArea_B_Stat 1;
BA_ "GenSigSendType" SG_ 997 PersIndexCcm_D_Actl 3;
BA_ "GenSigStartValueInteger" SG_ 997 PersIndexCcm_D_Actl 4;
BA_ "GenSigStartValue" SG_ 997 PersIndexCcm_D_Actl 4;
BA_ "U_T6_MCA_MY2020_Tx" SG_ 997 PersIndexCcm_D_Actl 1;
BA_ "U_CD542_MY2021_Tx" SG_ 997 PersIndexCcm_D_Actl 1;
BA_ "U_U55X_MY2022_Tx" SG_ 997 PersIndexCcm_D_Actl 1;
BA_ "U_CD764_MY2022_Tx" SG_ 997 PersIndexCcm_D_Actl 1;
BA_ "U_CDX706_MY2023_Tx" SG_ 997 PersIndexCcm_D_Actl 1;
BA_ "GenSigSendType" SG_ 997 FeatNoCcmActl 3;
BA_ "U_T6_MCA_MY2020_Tx" SG_ 997 FeatNoCcmActl 1;
BA_ "U_CD542_MY2021_Tx" SG_ 997 FeatNoCcmActl 1;
BA_ "U_U55X_MY2022_Tx" SG_ 997 FeatNoCcmActl 1;
BA_ "U_CD764_MY2022_Tx" SG_ 997 FeatNoCcmActl 1;
BA_ "U_CDX706_MY2023_Tx" SG_ 997 FeatNoCcmActl 1;
BA_ "GenSigSendType" SG_ 997 FeatConfigCcmActl 3;
BA_ "U_T6_MCA_MY2020_Tx" SG_ 997 FeatConfigCcmActl 1;
BA_ "U_CD542_MY2021_Tx" SG_ 997 FeatConfigCcmActl 1;
BA_ "U_U55X_MY2022_Tx" SG_ 997 FeatConfigCcmActl 1;
BA_ "U_CD764_MY2022_Tx" SG_ 997 FeatConfigCcmActl 1;
BA_ "U_CDX706_MY2023_Tx" SG_ 997 FeatConfigCcmActl 1;
BA_ "GenSigSendType" SG_ 997 PersTurnSglView_D_Stat 3;
BA_ "GenSigStartValue" SG_ 997 PersTurnSglView_D_Stat 3;
BA_ "U_CDX706_MY2023_Tx" SG_ 997 PersTurnSglView_D_Stat 1;
BA_ "GenSigSendType" SG_ 985 LongCtrlBrk_D_Rq 3;
BA_ "U_CDX706_MY2023_Rx" SG_ 985 LongCtrlBrk_D_Rq 1;
BA_ "U_CD764_MY2022_Tx" SG_ 985 LongCtrlBrk_D_Rq 1;
BA_ "U_CDX706_MY2023_Tx" SG_ 985 LongCtrlBrk_D_Rq 1;
BA_ "ContentDependant" SG_ 985 LongCtrlEnblDRq_No_Cs 1;
BA_ "MetaData" SG_ 985 LongCtrlEnblDRq_No_Cs 1;
BA_ "U_CDX706_MY2023_Rx" SG_ 985 LongCtrlEnblDRq_No_Cs 1;
BA_ "U_U55X_MY2022_Tx" SG_ 985 LongCtrlEnblDRq_No_Cs 1;
BA_ "U_CD764_MY2022_Tx" SG_ 985 LongCtrlEnblDRq_No_Cs 1;
BA_ "U_CDX706_MY2023_Tx" SG_ 985 LongCtrlEnblDRq_No_Cs 1;
BA_ "ContentDependant" SG_ 985 LongCtrlEnblDRq_No_Cnt 1;
BA_ "MetaData" SG_ 985 LongCtrlEnblDRq_No_Cnt 1;
BA_ "U_CDX706_MY2023_Rx" SG_ 985 LongCtrlEnblDRq_No_Cnt 1;
BA_ "U_U55X_MY2022_Tx" SG_ 985 LongCtrlEnblDRq_No_Cnt 1;
BA_ "U_CD764_MY2022_Tx" SG_ 985 LongCtrlEnblDRq_No_Cnt 1;
BA_ "U_CDX706_MY2023_Tx" SG_ 985 LongCtrlEnblDRq_No_Cnt 1;
BA_ "GenSigSendType" SG_ 985 AdbDrvSide_B_Stat 3;
BA_ "U_U55X_MY2022_Rx" SG_ 985 AdbDrvSide_B_Stat 1;
BA_ "U_CD764_MY2022_Rx" SG_ 985 AdbDrvSide_B_Stat 1;
BA_ "U_T6_MCA_MY2020_Tx" SG_ 985 AdbDrvSide_B_Stat 1;
BA_ "U_CD542_MY2021_Tx" SG_ 985 AdbDrvSide_B_Stat 1;
BA_ "U_U55X_MY2022_Tx" SG_ 985 AdbDrvSide_B_Stat 1;
BA_ "U_CD764_MY2022_Tx" SG_ 985 AdbDrvSide_B_Stat 1;
BA_ "U_CDX706_MY2023_Tx" SG_ 985 AdbDrvSide_B_Stat 1;
BA_ "GenSigSendType" SG_ 985 LcwaMsgTxt_D_Stat 3;
BA_ "U_T6_MCA_MY2020_Tx" SG_ 985 LcwaMsgTxt_D_Stat 1;
BA_ "U_CD542_MY2021_Tx" SG_ 985 LcwaMsgTxt_D_Stat 1;
BA_ "U_U55X_MY2022_Tx" SG_ 985 LcwaMsgTxt_D_Stat 1;
BA_ "U_CD764_MY2022_Tx" SG_ 985 LcwaMsgTxt_D_Stat 1;
BA_ "U_CDX706_MY2023_Tx" SG_ 985 LcwaMsgTxt_D_Stat 1;
BA_ "GenSigSendType" SG_ 985 AdbDividedRoad_B_Stat 3;
BA_ "U_CX727_MY2021_Rx" SG_ 985 AdbDividedRoad_B_Stat 1;
BA_ "U_P702_MY2021_Rx" SG_ 985 AdbDividedRoad_B_Stat 1;
BA_ "U_U55X_MY2022_Rx" SG_ 985 AdbDividedRoad_B_Stat 1;
BA_ "U_CD764_MY2022_Rx" SG_ 985 AdbDividedRoad_B_Stat 1;
BA_ "U_T6_MCA_MY2020_Tx" SG_ 985 AdbDividedRoad_B_Stat 1;
BA_ "U_CD542_MY2021_Tx" SG_ 985 AdbDividedRoad_B_Stat 1;
BA_ "U_U55X_MY2022_Tx" SG_ 985 AdbDividedRoad_B_Stat 1;
BA_ "U_CD764_MY2022_Tx" SG_ 985 AdbDividedRoad_B_Stat 1;
BA_ "U_CDX706_MY2023_Tx" SG_ 985 AdbDividedRoad_B_Stat 1;
BA_ "GenSigSendType" SG_ 985 IsaVLimUnit_D_Rq 3;
BA_ "U_P702_MY2021_Rx" SG_ 985 IsaVLimUnit_D_Rq 1;
BA_ "U_T6_MCA_MY2020_Rx" SG_ 985 IsaVLimUnit_D_Rq 1;
BA_ "U_CD542_MY2021_Rx" SG_ 985 IsaVLimUnit_D_Rq 1;
BA_ "U_CD764_MY2022_Rx" SG_ 985 IsaVLimUnit_D_Rq 1;
BA_ "U_CDX706_MY2023_Rx" SG_ 985 IsaVLimUnit_D_Rq 1;
BA_ "U_T6_MCA_MY2020_Tx" SG_ 985 IsaVLimUnit_D_Rq 1;
BA_ "U_CD542_MY2021_Tx" SG_ 985 IsaVLimUnit_D_Rq 1;
BA_ "U_U55X_MY2022_Tx" SG_ 985 IsaVLimUnit_D_Rq 1;
BA_ "U_CD764_MY2022_Tx" SG_ 985 IsaVLimUnit_D_Rq 1;
BA_ "U_CDX706_MY2023_Tx" SG_ 985 IsaVLimUnit_D_Rq 1;
BA_ "GenSigSendType" SG_ 985 SblmYieldScnr_B_Stat 3;
BA_ "U_CX727_MY2021_Rx" SG_ 985 SblmYieldScnr_B_Stat 1;
BA_ "U_P702_MY2021_Rx" SG_ 985 SblmYieldScnr_B_Stat 1;
BA_ "U_U55X_MY2022_Rx" SG_ 985 SblmYieldScnr_B_Stat 1;
BA_ "U_CD764_MY2022_Rx" SG_ 985 SblmYieldScnr_B_Stat 1;
BA_ "U_T6_MCA_MY2020_Tx" SG_ 985 SblmYieldScnr_B_Stat 1;
BA_ "U_CD542_MY2021_Tx" SG_ 985 SblmYieldScnr_B_Stat 1;
BA_ "U_U55X_MY2022_Tx" SG_ 985 SblmYieldScnr_B_Stat 1;
BA_ "U_CD764_MY2022_Tx" SG_ 985 SblmYieldScnr_B_Stat 1;
BA_ "U_CDX706_MY2023_Tx" SG_ 985 SblmYieldScnr_B_Stat 1;
BA_ "GenSigSendType" SG_ 985 SblmStopScnr_B_Stat 3;
BA_ "U_CX727_MY2021_Rx" SG_ 985 SblmStopScnr_B_Stat 1;
BA_ "U_P702_MY2021_Rx" SG_ 985 SblmStopScnr_B_Stat 1;
BA_ "U_U55X_MY2022_Rx" SG_ 985 SblmStopScnr_B_Stat 1;
BA_ "U_CD764_MY2022_Rx" SG_ 985 SblmStopScnr_B_Stat 1;
BA_ "U_T6_MCA_MY2020_Tx" SG_ 985 SblmStopScnr_B_Stat 1;
BA_ "U_CD542_MY2021_Tx" SG_ 985 SblmStopScnr_B_Stat 1;
BA_ "U_U55X_MY2022_Tx" SG_ 985 SblmStopScnr_B_Stat 1;
BA_ "U_CD764_MY2022_Tx" SG_ 985 SblmStopScnr_B_Stat 1;
BA_ "U_CDX706_MY2023_Tx" SG_ 985 SblmStopScnr_B_Stat 1;
BA_ "GenSigSendType" SG_ 985 IsaVLim_D_Rq 3;
BA_ "GenSigStartValueInteger" SG_ 985 IsaVLim_D_Rq 254;
BA_ "GenSigStartValue" SG_ 985 IsaVLim_D_Rq 254;
BA_ "U_P702_MY2021_Rx" SG_ 985 IsaVLim_D_Rq 1;
BA_ "U_T6_MCA_MY2020_Rx" SG_ 985 IsaVLim_D_Rq 1;
BA_ "U_CD542_MY2021_Rx" SG_ 985 IsaVLim_D_Rq 1;
BA_ "U_CD764_MY2022_Rx" SG_ 985 IsaVLim_D_Rq 1;
BA_ "U_CDX706_MY2023_Rx" SG_ 985 IsaVLim_D_Rq 1;
BA_ "U_T6_MCA_MY2020_Tx" SG_ 985 IsaVLim_D_Rq 1;
BA_ "U_CD542_MY2021_Tx" SG_ 985 IsaVLim_D_Rq 1;
BA_ "U_U55X_MY2022_Tx" SG_ 985 IsaVLim_D_Rq 1;
BA_ "U_CD764_MY2022_Tx" SG_ 985 IsaVLim_D_Rq 1;
BA_ "U_CDX706_MY2023_Tx" SG_ 985 IsaVLim_D_Rq 1;
BA_ "GenSigSendType" SG_ 985 IaccVLimUnit_D_Rq 3;
BA_ "GenSigStartValueInteger" SG_ 985 IaccVLimUnit_D_Rq 3;
BA_ "GenSigStartValue" SG_ 985 IaccVLimUnit_D_Rq 3;
BA_ "U_P702_MY2021_Rx" SG_ 985 IaccVLimUnit_D_Rq 1;
BA_ "U_T6_MCA_MY2020_Rx" SG_ 985 IaccVLimUnit_D_Rq 1;
BA_ "U_CD542_MY2021_Rx" SG_ 985 IaccVLimUnit_D_Rq 1;
BA_ "U_CD764_MY2022_Rx" SG_ 985 IaccVLimUnit_D_Rq 1;
BA_ "U_CDX706_MY2023_Rx" SG_ 985 IaccVLimUnit_D_Rq 1;
BA_ "U_T6_MCA_MY2020_Tx" SG_ 985 IaccVLimUnit_D_Rq 1;
BA_ "U_CD542_MY2021_Tx" SG_ 985 IaccVLimUnit_D_Rq 1;
BA_ "U_U55X_MY2022_Tx" SG_ 985 IaccVLimUnit_D_Rq 1;
BA_ "U_CD764_MY2022_Tx" SG_ 985 IaccVLimUnit_D_Rq 1;
BA_ "U_CDX706_MY2023_Tx" SG_ 985 IaccVLimUnit_D_Rq 1;
BA_ "GenSigSendType" SG_ 985 IaccVLim_D_Rq 3;
BA_ "GenSigStartValueInteger" SG_ 985 IaccVLim_D_Rq 254;
BA_ "GenSigStartValue" SG_ 985 IaccVLim_D_Rq 254;
BA_ "U_P702_MY2021_Rx" SG_ 985 IaccVLim_D_Rq 1;
BA_ "U_T6_MCA_MY2020_Rx" SG_ 985 IaccVLim_D_Rq 1;
BA_ "U_CD542_MY2021_Rx" SG_ 985 IaccVLim_D_Rq 1;
BA_ "U_CD764_MY2022_Rx" SG_ 985 IaccVLim_D_Rq 1;
BA_ "U_CDX706_MY2023_Rx" SG_ 985 IaccVLim_D_Rq 1;
BA_ "U_T6_MCA_MY2020_Tx" SG_ 985 IaccVLim_D_Rq 1;
BA_ "U_CD542_MY2021_Tx" SG_ 985 IaccVLim_D_Rq 1;
BA_ "U_U55X_MY2022_Tx" SG_ 985 IaccVLim_D_Rq 1;
BA_ "U_CD764_MY2022_Tx" SG_ 985 IaccVLim_D_Rq 1;
BA_ "U_CDX706_MY2023_Tx" SG_ 985 IaccVLim_D_Rq 1;
BA_ "GenSigSendType" SG_ 985 DasAlrtInfo_D_Dsply 3;
BA_ "U_T6_MCA_MY2020_Tx" SG_ 985 DasAlrtInfo_D_Dsply 1;
BA_ "U_CD542_MY2021_Tx" SG_ 985 DasAlrtInfo_D_Dsply 1;
BA_ "U_U55X_MY2022_Tx" SG_ 985 DasAlrtInfo_D_Dsply 1;
BA_ "U_CD764_MY2022_Tx" SG_ 985 DasAlrtInfo_D_Dsply 1;
BA_ "U_CDX706_MY2023_Tx" SG_ 985 DasAlrtInfo_D_Dsply 1;
BA_ "GenSigSendType" SG_ 985 SblmRndAbtScnr_B_Stat 3;
BA_ "U_CX727_MY2021_Rx" SG_ 985 SblmRndAbtScnr_B_Stat 1;
BA_ "U_P702_MY2021_Rx" SG_ 985 SblmRndAbtScnr_B_Stat 1;
BA_ "U_U55X_MY2022_Rx" SG_ 985 SblmRndAbtScnr_B_Stat 1;
BA_ "U_CD764_MY2022_Rx" SG_ 985 SblmRndAbtScnr_B_Stat 1;
BA_ "U_T6_MCA_MY2020_Tx" SG_ 985 SblmRndAbtScnr_B_Stat 1;
BA_ "U_CD542_MY2021_Tx" SG_ 985 SblmRndAbtScnr_B_Stat 1;
BA_ "U_U55X_MY2022_Tx" SG_ 985 SblmRndAbtScnr_B_Stat 1;
BA_ "U_CD764_MY2022_Tx" SG_ 985 SblmRndAbtScnr_B_Stat 1;
BA_ "U_CDX706_MY2023_Tx" SG_ 985 SblmRndAbtScnr_B_Stat 1;
BA_ "GenSigSendType" SG_ 985 PwSustnAdas_B_Rq 3;
BA_ "U_U55X_MY2022_Tx" SG_ 985 PwSustnAdas_B_Rq 1;
BA_ "U_CDX706_MY2023_Tx" SG_ 985 PwSustnAdas_B_Rq 1;
BA_ "GenSigSendType" SG_ 985 ClrExitAsstMsgTxt_D_Rq 3;
BA_ "U_U55X_MY2022_Tx" SG_ 985 ClrExitAsstMsgTxt_D_Rq 1;
BA_ "U_CD764_MY2022_Tx" SG_ 985 ClrExitAsstMsgTxt_D_Rq 1;
BA_ "U_CDX706_MY2023_Tx" SG_ 985 ClrExitAsstMsgTxt_D_Rq 1;
BA_ "GenSigSendType" SG_ 985 ClrExitAsstChime_D_Rq 3;
BA_ "U_U55X_MY2022_Tx" SG_ 985 ClrExitAsstChime_D_Rq 1;
BA_ "U_CD764_MY2022_Tx" SG_ 985 ClrExitAsstChime_D_Rq 1;
BA_ "U_CDX706_MY2023_Tx" SG_ 985 ClrExitAsstChime_D_Rq 1;
BA_ "GenSigSendType" SG_ 985 LongCtrlEnbl_D_Rq 3;
BA_ "U_T6_MCA_MY2020_Rx" SG_ 985 LongCtrlEnbl_D_Rq 1;
BA_ "U_CDX706_MY2023_Rx" SG_ 985 LongCtrlEnbl_D_Rq 1;
BA_ "U_T6_MCA_MY2020_Tx" SG_ 985 LongCtrlEnbl_D_Rq 1;
BA_ "U_CD542_MY2021_Tx" SG_ 985 LongCtrlEnbl_D_Rq 1;
BA_ "U_U55X_MY2022_Tx" SG_ 985 LongCtrlEnbl_D_Rq 1;
BA_ "U_CD764_MY2022_Tx" SG_ 985 LongCtrlEnbl_D_Rq 1;
BA_ "U_CDX706_MY2023_Tx" SG_ 985 LongCtrlEnbl_D_Rq 1;
BA_ "GenSigSendType" SG_ 985 SblmPedCrossScnr_B_Stat 3;
BA_ "U_U55X_MY2022_Rx" SG_ 985 SblmPedCrossScnr_B_Stat 1;
BA_ "U_CD764_MY2022_Rx" SG_ 985 SblmPedCrossScnr_B_Stat 1;
BA_ "U_T6_MCA_MY2020_Tx" SG_ 985 SblmPedCrossScnr_B_Stat 1;
BA_ "U_CD542_MY2021_Tx" SG_ 985 SblmPedCrossScnr_B_Stat 1;
BA_ "U_U55X_MY2022_Tx" SG_ 985 SblmPedCrossScnr_B_Stat 1;
BA_ "U_CD764_MY2022_Tx" SG_ 985 SblmPedCrossScnr_B_Stat 1;
BA_ "U_CDX706_MY2023_Tx" SG_ 985 SblmPedCrossScnr_B_Stat 1;
BA_ "GenSigSendType" SG_ 985 TsrRegionTxt_D_Stat 3;
BA_ "U_T6_MCA_MY2020_Tx" SG_ 985 TsrRegionTxt_D_Stat 1;
BA_ "U_CD542_MY2021_Tx" SG_ 985 TsrRegionTxt_D_Stat 1;
BA_ "U_U55X_MY2022_Tx" SG_ 985 TsrRegionTxt_D_Stat 1;
BA_ "U_CD764_MY2022_Tx" SG_ 985 TsrRegionTxt_D_Stat 1;
BA_ "U_CDX706_MY2023_Tx" SG_ 985 TsrRegionTxt_D_Stat 1;
BA_ "GenSigSendType" SG_ 985 LdwChime_B_Rq 3;
BA_ "U_T6_MCA_MY2020_Tx" SG_ 985 LdwChime_B_Rq 1;
BA_ "U_CD542_MY2021_Tx" SG_ 985 LdwChime_B_Rq 1;
BA_ "U_U55X_MY2022_Tx" SG_ 985 LdwChime_B_Rq 1;
BA_ "U_CD764_MY2022_Tx" SG_ 985 LdwChime_B_Rq 1;
BA_ "U_CDX706_MY2023_Tx" SG_ 985 LdwChime_B_Rq 1;
BA_ "GenSigSendType" SG_ 985 ClrExitAsst_D_Stat 3;
BA_ "U_U55X_MY2022_Tx" SG_ 985 ClrExitAsst_D_Stat 1;
BA_ "U_CD764_MY2022_Tx" SG_ 985 ClrExitAsst_D_Stat 1;
BA_ "U_CDX706_MY2023_Tx" SG_ 985 ClrExitAsst_D_Stat 1;
BA_ "GenSigSendType" SG_ 984 DasFalt_B_Dsply 3;
BA_ "GenSigSendType" SG_ 984 HzrdWarnLamp_B_Rq 3;
BA_ "GenSigSendType" SG_ 984 DasWarn_D_Dsply 3;
BA_ "U_T6_MCA_MY2020_Tx" SG_ 984 DasWarn_D_Dsply 1;
BA_ "U_CD542_MY2021_Tx" SG_ 984 DasWarn_D_Dsply 1;
BA_ "U_U55X_MY2022_Tx" SG_ 984 DasWarn_D_Dsply 1;
BA_ "U_CD764_MY2022_Tx" SG_ 984 DasWarn_D_Dsply 1;
BA_ "U_CDX706_MY2023_Tx" SG_ 984 DasWarn_D_Dsply 1;
BA_ "GenSigSendType" SG_ 984 DasStats_D_Dsply 3;
BA_ "U_T6_MCA_MY2020_Tx" SG_ 984 DasStats_D_Dsply 1;
BA_ "U_CD542_MY2021_Tx" SG_ 984 DasStats_D_Dsply 1;
BA_ "U_U55X_MY2022_Tx" SG_ 984 DasStats_D_Dsply 1;
BA_ "U_CD764_MY2022_Tx" SG_ 984 DasStats_D_Dsply 1;
BA_ "U_CDX706_MY2023_Tx" SG_ 984 DasStats_D_Dsply 1;
BA_ "GenSigSendType" SG_ 984 DasAlrtLvl_D_Dsply 3;
BA_ "U_T6_MCA_MY2020_Tx" SG_ 984 DasAlrtLvl_D_Dsply 1;
BA_ "U_CD542_MY2021_Tx" SG_ 984 DasAlrtLvl_D_Dsply 1;
BA_ "U_U55X_MY2022_Tx" SG_ 984 DasAlrtLvl_D_Dsply 1;
BA_ "U_CD764_MY2022_Tx" SG_ 984 DasAlrtLvl_D_Dsply 1;
BA_ "U_CDX706_MY2023_Tx" SG_ 984 DasAlrtLvl_D_Dsply 1;
BA_ "GenSigSendType" SG_ 984 CamraStats_D_Dsply 3;
BA_ "U_T6_MCA_MY2020_Tx" SG_ 984 CamraStats_D_Dsply 1;
BA_ "U_CD542_MY2021_Tx" SG_ 984 CamraStats_D_Dsply 1;
BA_ "U_U55X_MY2022_Tx" SG_ 984 CamraStats_D_Dsply 1;
BA_ "U_CD764_MY2022_Tx" SG_ 984 CamraStats_D_Dsply 1;
BA_ "U_CDX706_MY2023_Tx" SG_ 984 CamraStats_D_Dsply 1;
BA_ "GenSigSendType" SG_ 984 CamraDefog_B_Req 3;
BA_ "U_T6_MCA_MY2020_Tx" SG_ 984 CamraDefog_B_Req 1;
BA_ "U_CD542_MY2021_Tx" SG_ 984 CamraDefog_B_Req 1;
BA_ "U_U55X_MY2022_Tx" SG_ 984 CamraDefog_B_Req 1;
BA_ "U_CD764_MY2022_Tx" SG_ 984 CamraDefog_B_Req 1;
BA_ "U_CDX706_MY2023_Tx" SG_ 984 CamraDefog_B_Req 1;
BA_ "GenSigSendType" SG_ 984 LaHandsOff_D_Dsply 3;
BA_ "U_T6_MCA_MY2020_Tx" SG_ 984 LaHandsOff_D_Dsply 1;
BA_ "U_CD542_MY2021_Tx" SG_ 984 LaHandsOff_D_Dsply 1;
BA_ "U_U55X_MY2022_Tx" SG_ 984 LaHandsOff_D_Dsply 1;
BA_ "U_CD764_MY2022_Tx" SG_ 984 LaHandsOff_D_Dsply 1;
BA_ "U_CDX706_MY2023_Tx" SG_ 984 LaHandsOff_D_Dsply 1;
BA_ "GenSigSendType" SG_ 984 LaDenyStats_B_Dsply 3;
BA_ "U_T6_MCA_MY2020_Tx" SG_ 984 LaDenyStats_B_Dsply 1;
BA_ "U_CD542_MY2021_Tx" SG_ 984 LaDenyStats_B_Dsply 1;
BA_ "U_U55X_MY2022_Tx" SG_ 984 LaDenyStats_B_Dsply 1;
BA_ "U_CD764_MY2022_Tx" SG_ 984 LaDenyStats_B_Dsply 1;
BA_ "U_CDX706_MY2023_Tx" SG_ 984 LaDenyStats_B_Dsply 1;
BA_ "GenSigSendType" SG_ 984 AhbcRampingV_D_Rq 3;
BA_ "U_CX727_MY2021_Rx" SG_ 984 AhbcRampingV_D_Rq 1;
BA_ "U_P702_MY2021_Rx" SG_ 984 AhbcRampingV_D_Rq 1;
BA_ "U_U55X_MY2022_Rx" SG_ 984 AhbcRampingV_D_Rq 1;
BA_ "U_CD764_MY2022_Rx" SG_ 984 AhbcRampingV_D_Rq 1;
BA_ "U_T6_MCA_MY2020_Tx" SG_ 984 AhbcRampingV_D_Rq 1;
BA_ "U_CD542_MY2021_Tx" SG_ 984 AhbcRampingV_D_Rq 1;
BA_ "U_U55X_MY2022_Tx" SG_ 984 AhbcRampingV_D_Rq 1;
BA_ "U_CD764_MY2022_Tx" SG_ 984 AhbcRampingV_D_Rq 1;
BA_ "U_CDX706_MY2023_Tx" SG_ 984 AhbcRampingV_D_Rq 1;
BA_ "GenSigSendType" SG_ 984 PersIndexIpma_D_Actl 3;
BA_ "GenSigStartValueInteger" SG_ 984 PersIndexIpma_D_Actl 4;
BA_ "GenSigStartValue" SG_ 984 PersIndexIpma_D_Actl 4;
BA_ "U_T6_MCA_MY2020_Tx" SG_ 984 PersIndexIpma_D_Actl 1;
BA_ "U_CD542_MY2021_Tx" SG_ 984 PersIndexIpma_D_Actl 1;
BA_ "U_U55X_MY2022_Tx" SG_ 984 PersIndexIpma_D_Actl 1;
BA_ "U_CD764_MY2022_Tx" SG_ 984 PersIndexIpma_D_Actl 1;
BA_ "U_CDX706_MY2023_Tx" SG_ 984 PersIndexIpma_D_Actl 1;
BA_ "GenSigSendType" SG_ 984 FeatNoIpmaActl 3;
BA_ "U_T6_MCA_MY2020_Tx" SG_ 984 FeatNoIpmaActl 1;
BA_ "U_CD542_MY2021_Tx" SG_ 984 FeatNoIpmaActl 1;
BA_ "U_U55X_MY2022_Tx" SG_ 984 FeatNoIpmaActl 1;
BA_ "U_CD764_MY2022_Tx" SG_ 984 FeatNoIpmaActl 1;
BA_ "U_CDX706_MY2023_Tx" SG_ 984 FeatNoIpmaActl 1;
BA_ "GenSigSendType" SG_ 984 FeatConfigIpmaActl 3;
BA_ "U_T6_MCA_MY2020_Tx" SG_ 984 FeatConfigIpmaActl 1;
BA_ "U_CD542_MY2021_Tx" SG_ 984 FeatConfigIpmaActl 1;
BA_ "U_U55X_MY2022_Tx" SG_ 984 FeatConfigIpmaActl 1;
BA_ "U_CD764_MY2022_Tx" SG_ 984 FeatConfigIpmaActl 1;
BA_ "U_CDX706_MY2023_Tx" SG_ 984 FeatConfigIpmaActl 1;
BA_ "GenSigSendType" SG_ 984 AhbFeat_D_Stat 3;
BA_ "U_CDX706_MY2023_Tx" SG_ 984 AhbFeat_D_Stat 1;
BA_ "GenSigSendType" SG_ 984 DsmcMsgTxt_D_Dsply 3;
BA_ "U_T6_MCA_MY2020_Tx" SG_ 984 DsmcMsgTxt_D_Dsply 1;
BA_ "U_U55X_MY2022_Tx" SG_ 984 DsmcMsgTxt_D_Dsply 1;
BA_ "U_CDX706_MY2023_Tx" SG_ 984 DsmcMsgTxt_D_Dsply 1;
BA_ "GenSigSendType" SG_ 984 AhbHiBeam_D_Rq 3;
BA_ "U_T6_MCA_MY2020_Tx" SG_ 984 AhbHiBeam_D_Rq 1;
BA_ "U_U55X_MY2022_Tx" SG_ 984 AhbHiBeam_D_Rq 1;
BA_ "U_CD764_MY2022_Tx" SG_ 984 AhbHiBeam_D_Rq 1;
BA_ "U_CDX706_MY2023_Tx" SG_ 984 AhbHiBeam_D_Rq 1;
BA_ "GenSigSendType" SG_ 984 LaActvStats_D2_Dsply 3;
BA_ "U_CDX706_MY2023_Tx" SG_ 984 LaActvStats_D2_Dsply 1;
BA_ "GenSigStartValueInteger" SG_ 983 CmbbObjRelLong_V_Actl 1022;
BA_ "U_CX727_MY2021_Rx" SG_ 983 CmbbObjRelLong_V_Actl 1;
BA_ "U_P702_MY2021_Rx" SG_ 983 CmbbObjRelLong_V_Actl 1;
BA_ "U_T6_MCA_MY2020_Rx" SG_ 983 CmbbObjRelLong_V_Actl 1;
BA_ "U_CD542_MY2021_Rx" SG_ 983 CmbbObjRelLong_V_Actl 1;
BA_ "U_U55X_MY2022_Rx" SG_ 983 CmbbObjRelLong_V_Actl 1;
BA_ "U_CD764_MY2022_Rx" SG_ 983 CmbbObjRelLong_V_Actl 1;
BA_ "U_CDX706_MY2023_Rx" SG_ 983 CmbbObjRelLong_V_Actl 1;
BA_ "U_T6_MCA_MY2020_Tx" SG_ 983 CmbbObjRelLong_V_Actl 1;
BA_ "U_CD542_MY2021_Tx" SG_ 983 CmbbObjRelLong_V_Actl 1;
BA_ "U_U55X_MY2022_Tx" SG_ 983 CmbbObjRelLong_V_Actl 1;
BA_ "U_CD764_MY2022_Tx" SG_ 983 CmbbObjRelLong_V_Actl 1;
BA_ "U_CDX706_MY2023_Tx" SG_ 983 CmbbObjRelLong_V_Actl 1;
BA_ "GenSigStartValueInteger" SG_ 983 CmbbObjRelLat_V_Actl 510;
BA_ "GenSigStartValue" SG_ 983 CmbbObjRelLat_V_Actl 510;
BA_ "U_CX727_MY2021_Rx" SG_ 983 CmbbObjRelLat_V_Actl 1;
BA_ "U_P702_MY2021_Rx" SG_ 983 CmbbObjRelLat_V_Actl 1;
BA_ "U_T6_MCA_MY2020_Rx" SG_ 983 CmbbObjRelLat_V_Actl 1;
BA_ "U_CD542_MY2021_Rx" SG_ 983 CmbbObjRelLat_V_Actl 1;
BA_ "U_U55X_MY2022_Rx" SG_ 983 CmbbObjRelLat_V_Actl 1;
BA_ "U_CD764_MY2022_Rx" SG_ 983 CmbbObjRelLat_V_Actl 1;
BA_ "U_CDX706_MY2023_Rx" SG_ 983 CmbbObjRelLat_V_Actl 1;
BA_ "U_T6_MCA_MY2020_Tx" SG_ 983 CmbbObjRelLat_V_Actl 1;
BA_ "U_CD542_MY2021_Tx" SG_ 983 CmbbObjRelLat_V_Actl 1;
BA_ "U_U55X_MY2022_Tx" SG_ 983 CmbbObjRelLat_V_Actl 1;
BA_ "U_CD764_MY2022_Tx" SG_ 983 CmbbObjRelLat_V_Actl 1;
BA_ "U_CDX706_MY2023_Tx" SG_ 983 CmbbObjRelLat_V_Actl 1;
BA_ "GenSigStartValueInteger" SG_ 983 CmbbObjDistLong_L_Actl 1022;
BA_ "GenSigStartValue" SG_ 983 CmbbObjDistLong_L_Actl 1022;
BA_ "U_CX727_MY2021_Rx" SG_ 983 CmbbObjDistLong_L_Actl 1;
BA_ "U_P702_MY2021_Rx" SG_ 983 CmbbObjDistLong_L_Actl 1;
BA_ "U_T6_MCA_MY2020_Rx" SG_ 983 CmbbObjDistLong_L_Actl 1;
BA_ "U_CD542_MY2021_Rx" SG_ 983 CmbbObjDistLong_L_Actl 1;
BA_ "U_U55X_MY2022_Rx" SG_ 983 CmbbObjDistLong_L_Actl 1;
BA_ "U_CD764_MY2022_Rx" SG_ 983 CmbbObjDistLong_L_Actl 1;
BA_ "U_CDX706_MY2023_Rx" SG_ 983 CmbbObjDistLong_L_Actl 1;
BA_ "U_T6_MCA_MY2020_Tx" SG_ 983 CmbbObjDistLong_L_Actl 1;
BA_ "U_CD542_MY2021_Tx" SG_ 983 CmbbObjDistLong_L_Actl 1;
BA_ "U_U55X_MY2022_Tx" SG_ 983 CmbbObjDistLong_L_Actl 1;
BA_ "U_CD764_MY2022_Tx" SG_ 983 CmbbObjDistLong_L_Actl 1;
BA_ "U_CDX706_MY2023_Tx" SG_ 983 CmbbObjDistLong_L_Actl 1;
BA_ "GenSigStartValueInteger" SG_ 983 CmbbObjDistLat_L_Actl 510;
BA_ "GenSigStartValue" SG_ 983 CmbbObjDistLat_L_Actl 510;
BA_ "U_CX727_MY2021_Rx" SG_ 983 CmbbObjDistLat_L_Actl 1;
BA_ "U_P702_MY2021_Rx" SG_ 983 CmbbObjDistLat_L_Actl 1;
BA_ "U_T6_MCA_MY2020_Rx" SG_ 983 CmbbObjDistLat_L_Actl 1;
BA_ "U_CD542_MY2021_Rx" SG_ 983 CmbbObjDistLat_L_Actl 1;
BA_ "U_U55X_MY2022_Rx" SG_ 983 CmbbObjDistLat_L_Actl 1;
BA_ "U_CD764_MY2022_Rx" SG_ 983 CmbbObjDistLat_L_Actl 1;
BA_ "U_CDX706_MY2023_Rx" SG_ 983 CmbbObjDistLat_L_Actl 1;
BA_ "U_T6_MCA_MY2020_Tx" SG_ 983 CmbbObjDistLat_L_Actl 1;
BA_ "U_CD542_MY2021_Tx" SG_ 983 CmbbObjDistLat_L_Actl 1;
BA_ "U_U55X_MY2022_Tx" SG_ 983 CmbbObjDistLat_L_Actl 1;
BA_ "U_CD764_MY2022_Tx" SG_ 983 CmbbObjDistLat_L_Actl 1;
BA_ "U_CDX706_MY2023_Tx" SG_ 983 CmbbObjDistLat_L_Actl 1;
BA_ "U_CX727_MY2021_Rx" SG_ 983 CmbbObjConfdnc_D_Stat 1;
BA_ "U_P702_MY2021_Rx" SG_ 983 CmbbObjConfdnc_D_Stat 1;
BA_ "U_T6_MCA_MY2020_Rx" SG_ 983 CmbbObjConfdnc_D_Stat 1;
BA_ "U_CD542_MY2021_Rx" SG_ 983 CmbbObjConfdnc_D_Stat 1;
BA_ "U_U55X_MY2022_Rx" SG_ 983 CmbbObjConfdnc_D_Stat 1;
BA_ "U_CD764_MY2022_Rx" SG_ 983 CmbbObjConfdnc_D_Stat 1;
BA_ "U_CDX706_MY2023_Rx" SG_ 983 CmbbObjConfdnc_D_Stat 1;
BA_ "U_T6_MCA_MY2020_Tx" SG_ 983 CmbbObjConfdnc_D_Stat 1;
BA_ "U_CD542_MY2021_Tx" SG_ 983 CmbbObjConfdnc_D_Stat 1;
BA_ "U_U55X_MY2022_Tx" SG_ 983 CmbbObjConfdnc_D_Stat 1;
BA_ "U_CD764_MY2022_Tx" SG_ 983 CmbbObjConfdnc_D_Stat 1;
BA_ "U_CDX706_MY2023_Tx" SG_ 983 CmbbObjConfdnc_D_Stat 1;
BA_ "GenSigStartValueInteger" SG_ 983 CmbbObjColl_T_Actl 126;
BA_ "GenSigStartValue" SG_ 983 CmbbObjColl_T_Actl 125;
BA_ "U_CX727_MY2021_Rx" SG_ 983 CmbbObjColl_T_Actl 1;
BA_ "U_P702_MY2021_Rx" SG_ 983 CmbbObjColl_T_Actl 1;
BA_ "U_T6_MCA_MY2020_Rx" SG_ 983 CmbbObjColl_T_Actl 1;
BA_ "U_CD542_MY2021_Rx" SG_ 983 CmbbObjColl_T_Actl 1;
BA_ "U_U55X_MY2022_Rx" SG_ 983 CmbbObjColl_T_Actl 1;
BA_ "U_CD764_MY2022_Rx" SG_ 983 CmbbObjColl_T_Actl 1;
BA_ "U_CDX706_MY2023_Rx" SG_ 983 CmbbObjColl_T_Actl 1;
BA_ "U_T6_MCA_MY2020_Tx" SG_ 983 CmbbObjColl_T_Actl 1;
BA_ "U_CD542_MY2021_Tx" SG_ 983 CmbbObjColl_T_Actl 1;
BA_ "U_U55X_MY2022_Tx" SG_ 983 CmbbObjColl_T_Actl 1;
BA_ "U_CD764_MY2022_Tx" SG_ 983 CmbbObjColl_T_Actl 1;
BA_ "U_CDX706_MY2023_Tx" SG_ 983 CmbbObjColl_T_Actl 1;
BA_ "U_CX727_MY2021_Rx" SG_ 983 CmbbObjClass_D_Stat 1;
BA_ "U_P702_MY2021_Rx" SG_ 983 CmbbObjClass_D_Stat 1;
BA_ "U_T6_MCA_MY2020_Rx" SG_ 983 CmbbObjClass_D_Stat 1;
BA_ "U_CD542_MY2021_Rx" SG_ 983 CmbbObjClass_D_Stat 1;
BA_ "U_U55X_MY2022_Rx" SG_ 983 CmbbObjClass_D_Stat 1;
BA_ "U_CD764_MY2022_Rx" SG_ 983 CmbbObjClass_D_Stat 1;
BA_ "U_CDX706_MY2023_Rx" SG_ 983 CmbbObjClass_D_Stat 1;
BA_ "U_T6_MCA_MY2020_Tx" SG_ 983 CmbbObjClass_D_Stat 1;
BA_ "U_CD542_MY2021_Tx" SG_ 983 CmbbObjClass_D_Stat 1;
BA_ "U_U55X_MY2022_Tx" SG_ 983 CmbbObjClass_D_Stat 1;
BA_ "U_CD764_MY2022_Tx" SG_ 983 CmbbObjClass_D_Stat 1;
BA_ "U_CDX706_MY2023_Tx" SG_ 983 CmbbObjClass_D_Stat 1;
BA_ "U_CX727_MY2021_Rx" SG_ 983 EsaEnbl_D2_Rq 1;
BA_ "U_P702_MY2021_Rx" SG_ 983 EsaEnbl_D2_Rq 1;
BA_ "U_T6_MCA_MY2020_Rx" SG_ 983 EsaEnbl_D2_Rq 1;
BA_ "U_CD542_MY2021_Rx" SG_ 983 EsaEnbl_D2_Rq 1;
BA_ "U_U55X_MY2022_Rx" SG_ 983 EsaEnbl_D2_Rq 1;
BA_ "U_CD764_MY2022_Rx" SG_ 983 EsaEnbl_D2_Rq 1;
BA_ "U_CDX706_MY2023_Rx" SG_ 983 EsaEnbl_D2_Rq 1;
BA_ "U_T6_MCA_MY2020_Tx" SG_ 983 EsaEnbl_D2_Rq 1;
BA_ "U_CD542_MY2021_Tx" SG_ 983 EsaEnbl_D2_Rq 1;
BA_ "U_U55X_MY2022_Tx" SG_ 983 EsaEnbl_D2_Rq 1;
BA_ "U_CD764_MY2022_Tx" SG_ 983 EsaEnbl_D2_Rq 1;
BA_ "U_CDX706_MY2023_Tx" SG_ 983 EsaEnbl_D2_Rq 1;
BA_ "U_U55X_MY2022_Rx" SG_ 976 SuspClkSync_No_Actl 1;
BA_ "U_T6_MCA_MY2020_Tx" SG_ 976 SuspClkSync_No_Actl 1;
BA_ "U_CD542_MY2021_Tx" SG_ 976 SuspClkSync_No_Actl 1;
BA_ "U_U55X_MY2022_Tx" SG_ 976 SuspClkSync_No_Actl 1;
BA_ "U_CD764_MY2022_Tx" SG_ 976 SuspClkSync_No_Actl 1;
BA_ "U_CDX706_MY2023_Tx" SG_ 976 SuspClkSync_No_Actl 1;
BA_ "U_U55X_MY2022_Rx" SG_ 976 SrpSigValid_B_Stat 1;
BA_ "U_T6_MCA_MY2020_Tx" SG_ 976 SrpSigValid_B_Stat 1;
BA_ "U_CD542_MY2021_Tx" SG_ 976 SrpSigValid_B_Stat 1;
BA_ "U_U55X_MY2022_Tx" SG_ 976 SrpSigValid_B_Stat 1;
BA_ "U_CD764_MY2022_Tx" SG_ 976 SrpSigValid_B_Stat 1;
BA_ "U_CDX706_MY2023_Tx" SG_ 976 SrpSigValid_B_Stat 1;
BA_ "GenSigStartValueInteger" SG_ 976 SrpHghtRight_L_Actl 256;
BA_ "U_U55X_MY2022_Rx" SG_ 976 SrpHghtRight_L_Actl 1;
BA_ "U_T6_MCA_MY2020_Tx" SG_ 976 SrpHghtRight_L_Actl 1;
BA_ "U_CD542_MY2021_Tx" SG_ 976 SrpHghtRight_L_Actl 1;
BA_ "U_U55X_MY2022_Tx" SG_ 976 SrpHghtRight_L_Actl 1;
BA_ "U_CD764_MY2022_Tx" SG_ 976 SrpHghtRight_L_Actl 1;
BA_ "U_CDX706_MY2023_Tx" SG_ 976 SrpHghtRight_L_Actl 1;
BA_ "GenSigStartValueInteger" SG_ 976 SrpHghtLeft_L_Actl 256;
BA_ "U_U55X_MY2022_Rx" SG_ 976 SrpHghtLeft_L_Actl 1;
BA_ "U_T6_MCA_MY2020_Tx" SG_ 976 SrpHghtLeft_L_Actl 1;
BA_ "U_CD542_MY2021_Tx" SG_ 976 SrpHghtLeft_L_Actl 1;
BA_ "U_U55X_MY2022_Tx" SG_ 976 SrpHghtLeft_L_Actl 1;
BA_ "U_CD764_MY2022_Tx" SG_ 976 SrpHghtLeft_L_Actl 1;
BA_ "U_CDX706_MY2023_Tx" SG_ 976 SrpHghtLeft_L_Actl 1;
BA_ "U_U55X_MY2022_Rx" SG_ 976 SrpEventRight_D_Stat 1;
BA_ "U_T6_MCA_MY2020_Tx" SG_ 976 SrpEventRight_D_Stat 1;
BA_ "U_CD542_MY2021_Tx" SG_ 976 SrpEventRight_D_Stat 1;
BA_ "U_U55X_MY2022_Tx" SG_ 976 SrpEventRight_D_Stat 1;
BA_ "U_CD764_MY2022_Tx" SG_ 976 SrpEventRight_D_Stat 1;
BA_ "U_CDX706_MY2023_Tx" SG_ 976 SrpEventRight_D_Stat 1;
BA_ "U_U55X_MY2022_Rx" SG_ 976 SrpEventLeft_D_Stat 1;
BA_ "U_T6_MCA_MY2020_Tx" SG_ 976 SrpEventLeft_D_Stat 1;
BA_ "U_CD542_MY2021_Tx" SG_ 976 SrpEventLeft_D_Stat 1;
BA_ "U_U55X_MY2022_Tx" SG_ 976 SrpEventLeft_D_Stat 1;
BA_ "U_CD764_MY2022_Tx" SG_ 976 SrpEventLeft_D_Stat 1;
BA_ "U_CDX706_MY2023_Tx" SG_ 976 SrpEventLeft_D_Stat 1;
BA_ "U_U55X_MY2022_Rx" SG_ 976 SrpDistRight_L_Actl 1;
BA_ "U_T6_MCA_MY2020_Tx" SG_ 976 SrpDistRight_L_Actl 1;
BA_ "U_CD542_MY2021_Tx" SG_ 976 SrpDistRight_L_Actl 1;
BA_ "U_U55X_MY2022_Tx" SG_ 976 SrpDistRight_L_Actl 1;
BA_ "U_CD764_MY2022_Tx" SG_ 976 SrpDistRight_L_Actl 1;
BA_ "U_CDX706_MY2023_Tx" SG_ 976 SrpDistRight_L_Actl 1;
BA_ "U_U55X_MY2022_Rx" SG_ 976 SrpDistLeft_L_Actl 1;
BA_ "U_T6_MCA_MY2020_Tx" SG_ 976 SrpDistLeft_L_Actl 1;
BA_ "U_CD542_MY2021_Tx" SG_ 976 SrpDistLeft_L_Actl 1;
BA_ "U_U55X_MY2022_Tx" SG_ 976 SrpDistLeft_L_Actl 1;
BA_ "U_CD764_MY2022_Tx" SG_ 976 SrpDistLeft_L_Actl 1;
BA_ "U_CDX706_MY2023_Tx" SG_ 976 SrpDistLeft_L_Actl 1;
BA_ "GenSigSendType" SG_ 973 TsrChime_D_Rq 3;
BA_ "GenSigSendType" SG_ 973 PersCtaSplitView_D_Stat 3;
BA_ "U_CDX706_MY2023_Tx" SG_ 973 PersCtaSplitView_D_Stat 1;
BA_ "GenSigSendType" SG_ 973 TsrVl2PrmntMsgTxt_D_Rq 3;
BA_ "U_T6_MCA_MY2020_Tx" SG_ 973 TsrVl2PrmntMsgTxt_D_Rq 1;
BA_ "U_CD542_MY2021_Tx" SG_ 973 TsrVl2PrmntMsgTxt_D_Rq 1;
BA_ "U_U55X_MY2022_Tx" SG_ 973 TsrVl2PrmntMsgTxt_D_Rq 1;
BA_ "U_CD764_MY2022_Tx" SG_ 973 TsrVl2PrmntMsgTxt_D_Rq 1;
BA_ "U_CDX706_MY2023_Tx" SG_ 973 TsrVl2PrmntMsgTxt_D_Rq 1;
BA_ "GenSigSendType" SG_ 973 TsrVl1PrmntMsgTxt_D_Rq 3;
BA_ "U_T6_MCA_MY2020_Tx" SG_ 973 TsrVl1PrmntMsgTxt_D_Rq 1;
BA_ "U_CD542_MY2021_Tx" SG_ 973 TsrVl1PrmntMsgTxt_D_Rq 1;
BA_ "U_U55X_MY2022_Tx" SG_ 973 TsrVl1PrmntMsgTxt_D_Rq 1;
BA_ "U_CD764_MY2022_Tx" SG_ 973 TsrVl1PrmntMsgTxt_D_Rq 1;
BA_ "U_CDX706_MY2023_Tx" SG_ 973 TsrVl1PrmntMsgTxt_D_Rq 1;
BA_ "GenSigSendType" SG_ 973 TsrVl2RstrcMsgTxt2_D_Rq 3;
BA_ "GenSigStartValueInteger" SG_ 973 TsrVl2RstrcMsgTxt2_D_Rq 1;
BA_ "GenSigStartValue" SG_ 973 TsrVl2RstrcMsgTxt2_D_Rq 1;
BA_ "U_T6_MCA_MY2020_Tx" SG_ 973 TsrVl2RstrcMsgTxt2_D_Rq 1;
BA_ "U_CD542_MY2021_Tx" SG_ 973 TsrVl2RstrcMsgTxt2_D_Rq 1;
BA_ "U_U55X_MY2022_Tx" SG_ 973 TsrVl2RstrcMsgTxt2_D_Rq 1;
BA_ "U_CD764_MY2022_Tx" SG_ 973 TsrVl2RstrcMsgTxt2_D_Rq 1;
BA_ "U_CDX706_MY2023_Tx" SG_ 973 TsrVl2RstrcMsgTxt2_D_Rq 1;
BA_ "GenSigSendType" SG_ 973 TsrVl1RstrcMsgTxt2_D_Rq 3;
BA_ "GenSigStartValueInteger" SG_ 973 TsrVl1RstrcMsgTxt2_D_Rq 1;
BA_ "GenSigStartValue" SG_ 973 TsrVl1RstrcMsgTxt2_D_Rq 1;
BA_ "U_T6_MCA_MY2020_Tx" SG_ 973 TsrVl1RstrcMsgTxt2_D_Rq 1;
BA_ "U_CD542_MY2021_Tx" SG_ 973 TsrVl1RstrcMsgTxt2_D_Rq 1;
BA_ "U_U55X_MY2022_Tx" SG_ 973 TsrVl1RstrcMsgTxt2_D_Rq 1;
BA_ "U_CD764_MY2022_Tx" SG_ 973 TsrVl1RstrcMsgTxt2_D_Rq 1;
BA_ "U_CDX706_MY2023_Tx" SG_ 973 TsrVl1RstrcMsgTxt2_D_Rq 1;
BA_ "GenSigSendType" SG_ 973 TsrOvtkMsgTxt2_D_Rq 3;
BA_ "U_T6_MCA_MY2020_Tx" SG_ 973 TsrOvtkMsgTxt2_D_Rq 1;
BA_ "U_CD542_MY2021_Tx" SG_ 973 TsrOvtkMsgTxt2_D_Rq 1;
BA_ "U_U55X_MY2022_Tx" SG_ 973 TsrOvtkMsgTxt2_D_Rq 1;
BA_ "U_CD764_MY2022_Tx" SG_ 973 TsrOvtkMsgTxt2_D_Rq 1;
BA_ "U_CDX706_MY2023_Tx" SG_ 973 TsrOvtkMsgTxt2_D_Rq 1;
BA_ "GenSigSendType" SG_ 973 WwaWarn_B_Rq 3;
BA_ "U_T6_MCA_MY2020_Tx" SG_ 973 WwaWarn_B_Rq 1;
BA_ "U_CD542_MY2021_Tx" SG_ 973 WwaWarn_B_Rq 1;
BA_ "U_U55X_MY2022_Tx" SG_ 973 WwaWarn_B_Rq 1;
BA_ "U_CD764_MY2022_Tx" SG_ 973 WwaWarn_B_Rq 1;
BA_ "U_CDX706_MY2023_Tx" SG_ 973 WwaWarn_B_Rq 1;
BA_ "GenSigSendType" SG_ 973 TsrVlUnitMsgTxt_D_Rq 3;
BA_ "GenSigStartValueInteger" SG_ 973 TsrVlUnitMsgTxt_D_Rq 2;
BA_ "GenSigStartValue" SG_ 973 TsrVlUnitMsgTxt_D_Rq 2;
BA_ "U_T6_MCA_MY2020_Tx" SG_ 973 TsrVlUnitMsgTxt_D_Rq 1;
BA_ "U_CD542_MY2021_Tx" SG_ 973 TsrVlUnitMsgTxt_D_Rq 1;
BA_ "U_U55X_MY2022_Tx" SG_ 973 TsrVlUnitMsgTxt_D_Rq 1;
BA_ "U_CD764_MY2022_Tx" SG_ 973 TsrVlUnitMsgTxt_D_Rq 1;
BA_ "U_CDX706_MY2023_Tx" SG_ 973 TsrVlUnitMsgTxt_D_Rq 1;
BA_ "GenSigSendType" SG_ 973 TsrVLim2MsgTxt_D_Rq 3;
BA_ "GenSigStartValueInteger" SG_ 973 TsrVLim2MsgTxt_D_Rq 255;
BA_ "GenSigStartValue" SG_ 973 TsrVLim2MsgTxt_D_Rq 255;
BA_ "U_T6_MCA_MY2020_Tx" SG_ 973 TsrVLim2MsgTxt_D_Rq 1;
BA_ "U_CD542_MY2021_Tx" SG_ 973 TsrVLim2MsgTxt_D_Rq 1;
BA_ "U_U55X_MY2022_Tx" SG_ 973 TsrVLim2MsgTxt_D_Rq 1;
BA_ "U_CD764_MY2022_Tx" SG_ 973 TsrVLim2MsgTxt_D_Rq 1;
BA_ "U_CDX706_MY2023_Tx" SG_ 973 TsrVLim2MsgTxt_D_Rq 1;
BA_ "GenSigSendType" SG_ 973 TsrVLim1MsgTxt_D_Rq 3;
BA_ "GenSigStartValueInteger" SG_ 973 TsrVLim1MsgTxt_D_Rq 255;
BA_ "GenSigStartValue" SG_ 973 TsrVLim1MsgTxt_D_Rq 255;
BA_ "U_T6_MCA_MY2020_Tx" SG_ 973 TsrVLim1MsgTxt_D_Rq 1;
BA_ "U_CD542_MY2021_Tx" SG_ 973 TsrVLim1MsgTxt_D_Rq 1;
BA_ "U_U55X_MY2022_Tx" SG_ 973 TsrVLim1MsgTxt_D_Rq 1;
BA_ "U_CD764_MY2022_Tx" SG_ 973 TsrVLim1MsgTxt_D_Rq 1;
BA_ "U_CDX706_MY2023_Tx" SG_ 973 TsrVLim1MsgTxt_D_Rq 1;
BA_ "GenSigSendType" SG_ 973 TsrVl2StatMsgTxt_D_Rq 3;
BA_ "U_T6_MCA_MY2020_Tx" SG_ 973 TsrVl2StatMsgTxt_D_Rq 1;
BA_ "U_CD542_MY2021_Tx" SG_ 973 TsrVl2StatMsgTxt_D_Rq 1;
BA_ "U_U55X_MY2022_Tx" SG_ 973 TsrVl2StatMsgTxt_D_Rq 1;
BA_ "U_CD764_MY2022_Tx" SG_ 973 TsrVl2StatMsgTxt_D_Rq 1;
BA_ "U_CDX706_MY2023_Tx" SG_ 973 TsrVl2StatMsgTxt_D_Rq 1;
BA_ "GenSigSendType" SG_ 973 TsrVl2RstrcMsgTxt_D_Rq 3;
BA_ "U_T6_MCA_MY2020_Tx" SG_ 973 TsrVl2RstrcMsgTxt_D_Rq 1;
BA_ "U_CD542_MY2021_Tx" SG_ 973 TsrVl2RstrcMsgTxt_D_Rq 1;
BA_ "U_U55X_MY2022_Tx" SG_ 973 TsrVl2RstrcMsgTxt_D_Rq 1;
BA_ "U_CD764_MY2022_Tx" SG_ 973 TsrVl2RstrcMsgTxt_D_Rq 1;
BA_ "U_CDX706_MY2023_Tx" SG_ 973 TsrVl2RstrcMsgTxt_D_Rq 1;
BA_ "GenSigSendType" SG_ 973 TsrVl1StatMsgTxt_D_Rq 3;
BA_ "U_T6_MCA_MY2020_Tx" SG_ 973 TsrVl1StatMsgTxt_D_Rq 1;
BA_ "U_CD542_MY2021_Tx" SG_ 973 TsrVl1StatMsgTxt_D_Rq 1;
BA_ "U_U55X_MY2022_Tx" SG_ 973 TsrVl1StatMsgTxt_D_Rq 1;
BA_ "U_CD764_MY2022_Tx" SG_ 973 TsrVl1StatMsgTxt_D_Rq 1;
BA_ "U_CDX706_MY2023_Tx" SG_ 973 TsrVl1StatMsgTxt_D_Rq 1;
BA_ "GenSigSendType" SG_ 973 TsrVl1RstrcMsgTxt_D_Rq 3;
BA_ "U_T6_MCA_MY2020_Tx" SG_ 973 TsrVl1RstrcMsgTxt_D_Rq 1;
BA_ "U_CD542_MY2021_Tx" SG_ 973 TsrVl1RstrcMsgTxt_D_Rq 1;
BA_ "U_U55X_MY2022_Tx" SG_ 973 TsrVl1RstrcMsgTxt_D_Rq 1;
BA_ "U_CD764_MY2022_Tx" SG_ 973 TsrVl1RstrcMsgTxt_D_Rq 1;
BA_ "U_CDX706_MY2023_Tx" SG_ 973 TsrVl1RstrcMsgTxt_D_Rq 1;
BA_ "GenSigSendType" SG_ 973 TsrStatMsgTxt_D_Rq 3;
BA_ "U_T6_MCA_MY2020_Tx" SG_ 973 TsrStatMsgTxt_D_Rq 1;
BA_ "U_CD542_MY2021_Tx" SG_ 973 TsrStatMsgTxt_D_Rq 1;
BA_ "U_U55X_MY2022_Tx" SG_ 973 TsrStatMsgTxt_D_Rq 1;
BA_ "U_CD764_MY2022_Tx" SG_ 973 TsrStatMsgTxt_D_Rq 1;
BA_ "U_CDX706_MY2023_Tx" SG_ 973 TsrStatMsgTxt_D_Rq 1;
BA_ "GenSigSendType" SG_ 973 TsrOvtkStatMsgTxt_D_Rq 3;
BA_ "U_T6_MCA_MY2020_Tx" SG_ 973 TsrOvtkStatMsgTxt_D_Rq 1;
BA_ "U_CD542_MY2021_Tx" SG_ 973 TsrOvtkStatMsgTxt_D_Rq 1;
BA_ "U_U55X_MY2022_Tx" SG_ 973 TsrOvtkStatMsgTxt_D_Rq 1;
BA_ "U_CD764_MY2022_Tx" SG_ 973 TsrOvtkStatMsgTxt_D_Rq 1;
BA_ "U_CDX706_MY2023_Tx" SG_ 973 TsrOvtkStatMsgTxt_D_Rq 1;
BA_ "GenSigSendType" SG_ 973 TsrOvtkMsgTxt_D_Rq 3;
BA_ "GenSigStartValueInteger" SG_ 973 TsrOvtkMsgTxt_D_Rq 1;
BA_ "GenSigStartValue" SG_ 973 TsrOvtkMsgTxt_D_Rq 1;
BA_ "U_T6_MCA_MY2020_Tx" SG_ 973 TsrOvtkMsgTxt_D_Rq 1;
BA_ "U_CD542_MY2021_Tx" SG_ 973 TsrOvtkMsgTxt_D_Rq 1;
BA_ "U_U55X_MY2022_Tx" SG_ 973 TsrOvtkMsgTxt_D_Rq 1;
BA_ "U_CD764_MY2022_Tx" SG_ 973 TsrOvtkMsgTxt_D_Rq 1;
BA_ "U_CDX706_MY2023_Tx" SG_ 973 TsrOvtkMsgTxt_D_Rq 1;
BA_ "GenSigSendType" SG_ 973 TsrOswWarnMsgTxt_D_Rq 3;
BA_ "GenSigStartValueInteger" SG_ 973 TsrOswWarnMsgTxt_D_Rq 1;
BA_ "GenSigStartValue" SG_ 973 TsrOswWarnMsgTxt_D_Rq 1;
BA_ "U_T6_MCA_MY2020_Tx" SG_ 973 TsrOswWarnMsgTxt_D_Rq 1;
BA_ "U_CD542_MY2021_Tx" SG_ 973 TsrOswWarnMsgTxt_D_Rq 1;
BA_ "U_U55X_MY2022_Tx" SG_ 973 TsrOswWarnMsgTxt_D_Rq 1;
BA_ "U_CD764_MY2022_Tx" SG_ 973 TsrOswWarnMsgTxt_D_Rq 1;
BA_ "U_CDX706_MY2023_Tx" SG_ 973 TsrOswWarnMsgTxt_D_Rq 1;
BA_ "GenSigSendType" SG_ 973 TsrMsgTxt_D_Rq 3;
BA_ "GenSigStartValueInteger" SG_ 973 TsrMsgTxt_D_Rq 1;
BA_ "GenSigStartValue" SG_ 973 TsrMsgTxt_D_Rq 1;
BA_ "U_T6_MCA_MY2020_Tx" SG_ 973 TsrMsgTxt_D_Rq 1;
BA_ "U_CD542_MY2021_Tx" SG_ 973 TsrMsgTxt_D_Rq 1;
BA_ "U_U55X_MY2022_Tx" SG_ 973 TsrMsgTxt_D_Rq 1;
BA_ "U_CD764_MY2022_Tx" SG_ 973 TsrMsgTxt_D_Rq 1;
BA_ "U_CDX706_MY2023_Tx" SG_ 973 TsrMsgTxt_D_Rq 1;
BA_ "GenSigSendType" SG_ 973 LaSysOffStat_D_Dsply 3;
BA_ "U_T6_MCA_MY2020_Tx" SG_ 973 LaSysOffStat_D_Dsply 1;
BA_ "U_U55X_MY2022_Tx" SG_ 973 LaSysOffStat_D_Dsply 1;
BA_ "U_CD764_MY2022_Tx" SG_ 973 LaSysOffStat_D_Dsply 1;
BA_ "U_CDX706_MY2023_Tx" SG_ 973 LaSysOffStat_D_Dsply 1;
BA_ "GenSigSendType" SG_ 973 RoadSignRgltry_D_Dsply 3;
BA_ "U_CDX706_MY2023_Tx" SG_ 973 RoadSignRgltry_D_Dsply 1;
BA_ "U_CX727_MY2021_Rx" SG_ 970 LkaDrvOvrrd_D_Rq 1;
BA_ "U_P702_MY2021_Rx" SG_ 970 LkaDrvOvrrd_D_Rq 1;
BA_ "U_T6_MCA_MY2020_Rx" SG_ 970 LkaDrvOvrrd_D_Rq 1;
BA_ "U_CD542_MY2021_Rx" SG_ 970 LkaDrvOvrrd_D_Rq 1;
BA_ "U_U55X_MY2022_Rx" SG_ 970 LkaDrvOvrrd_D_Rq 1;
BA_ "U_CD764_MY2022_Rx" SG_ 970 LkaDrvOvrrd_D_Rq 1;
BA_ "U_CDX706_MY2023_Rx" SG_ 970 LkaDrvOvrrd_D_Rq 1;
BA_ "U_T6_MCA_MY2020_Tx" SG_ 970 LkaDrvOvrrd_D_Rq 1;
BA_ "U_CD542_MY2021_Tx" SG_ 970 LkaDrvOvrrd_D_Rq 1;
BA_ "U_U55X_MY2022_Tx" SG_ 970 LkaDrvOvrrd_D_Rq 1;
BA_ "U_CDX706_MY2023_Tx" SG_ 970 LkaDrvOvrrd_D_Rq 1;
BA_ "U_CX727_MY2021_Rx" SG_ 970 LkaActvStats_D2_Req 1;
BA_ "U_P702_MY2021_Rx" SG_ 970 LkaActvStats_D2_Req 1;
BA_ "U_T6_MCA_MY2020_Rx" SG_ 970 LkaActvStats_D2_Req 1;
BA_ "U_CD542_MY2021_Rx" SG_ 970 LkaActvStats_D2_Req 1;
BA_ "U_U55X_MY2022_Rx" SG_ 970 LkaActvStats_D2_Req 1;
BA_ "U_CD764_MY2022_Rx" SG_ 970 LkaActvStats_D2_Req 1;
BA_ "U_CDX706_MY2023_Rx" SG_ 970 LkaActvStats_D2_Req 1;
BA_ "U_T6_MCA_MY2020_Tx" SG_ 970 LkaActvStats_D2_Req 1;
BA_ "U_CD542_MY2021_Tx" SG_ 970 LkaActvStats_D2_Req 1;
BA_ "U_U55X_MY2022_Tx" SG_ 970 LkaActvStats_D2_Req 1;
BA_ "U_CD764_MY2022_Tx" SG_ 970 LkaActvStats_D2_Req 1;
BA_ "U_CDX706_MY2023_Tx" SG_ 970 LkaActvStats_D2_Req 1;
BA_ "GenSigStartValueInteger" SG_ 970 LaRefAng_No_Req 2048;
BA_ "U_CX727_MY2021_Rx" SG_ 970 LaRefAng_No_Req 1;
BA_ "U_P702_MY2021_Rx" SG_ 970 LaRefAng_No_Req 1;
BA_ "U_T6_MCA_MY2020_Rx" SG_ 970 LaRefAng_No_Req 1;
BA_ "U_CD542_MY2021_Rx" SG_ 970 LaRefAng_No_Req 1;
BA_ "U_U55X_MY2022_Rx" SG_ 970 LaRefAng_No_Req 1;
BA_ "U_CD764_MY2022_Rx" SG_ 970 LaRefAng_No_Req 1;
BA_ "U_CDX706_MY2023_Rx" SG_ 970 LaRefAng_No_Req 1;
BA_ "U_T6_MCA_MY2020_Tx" SG_ 970 LaRefAng_No_Req 1;
BA_ "U_CD542_MY2021_Tx" SG_ 970 LaRefAng_No_Req 1;
BA_ "U_U55X_MY2022_Tx" SG_ 970 LaRefAng_No_Req 1;
BA_ "U_CD764_MY2022_Tx" SG_ 970 LaRefAng_No_Req 1;
BA_ "U_CDX706_MY2023_Tx" SG_ 970 LaRefAng_No_Req 1;
BA_ "U_CX727_MY2021_Rx" SG_ 970 LaRampType_B_Req 1;
BA_ "U_P702_MY2021_Rx" SG_ 970 LaRampType_B_Req 1;
BA_ "U_T6_MCA_MY2020_Rx" SG_ 970 LaRampType_B_Req 1;
BA_ "U_CD542_MY2021_Rx" SG_ 970 LaRampType_B_Req 1;
BA_ "U_U55X_MY2022_Rx" SG_ 970 LaRampType_B_Req 1;
BA_ "U_CD764_MY2022_Rx" SG_ 970 LaRampType_B_Req 1;
BA_ "U_CDX706_MY2023_Rx" SG_ 970 LaRampType_B_Req 1;
BA_ "U_T6_MCA_MY2020_Tx" SG_ 970 LaRampType_B_Req 1;
BA_ "U_CD542_MY2021_Tx" SG_ 970 LaRampType_B_Req 1;
BA_ "U_U55X_MY2022_Tx" SG_ 970 LaRampType_B_Req 1;
BA_ "U_CD764_MY2022_Tx" SG_ 970 LaRampType_B_Req 1;
BA_ "U_CDX706_MY2023_Tx" SG_ 970 LaRampType_B_Req 1;
BA_ "GenSigStartValueInteger" SG_ 970 LaCurvature_No_Calc 2048;
BA_ "U_CX727_MY2021_Rx" SG_ 970 LaCurvature_No_Calc 1;
BA_ "U_P702_MY2021_Rx" SG_ 970 LaCurvature_No_Calc 1;
BA_ "U_T6_MCA_MY2020_Rx" SG_ 970 LaCurvature_No_Calc 1;
BA_ "U_CD542_MY2021_Rx" SG_ 970 LaCurvature_No_Calc 1;
BA_ "U_U55X_MY2022_Rx" SG_ 970 LaCurvature_No_Calc 1;
BA_ "U_CD764_MY2022_Rx" SG_ 970 LaCurvature_No_Calc 1;
BA_ "U_CDX706_MY2023_Rx" SG_ 970 LaCurvature_No_Calc 1;
BA_ "U_T6_MCA_MY2020_Tx" SG_ 970 LaCurvature_No_Calc 1;
BA_ "U_CD542_MY2021_Tx" SG_ 970 LaCurvature_No_Calc 1;
BA_ "U_U55X_MY2022_Tx" SG_ 970 LaCurvature_No_Calc 1;
BA_ "U_CD764_MY2022_Tx" SG_ 970 LaCurvature_No_Calc 1;
BA_ "U_CDX706_MY2023_Tx" SG_ 970 LaCurvature_No_Calc 1;
BA_ "U_CX727_MY2021_Rx" SG_ 970 LdwActvStats_D_Req 1;
BA_ "U_P702_MY2021_Rx" SG_ 970 LdwActvStats_D_Req 1;
BA_ "U_T6_MCA_MY2020_Rx" SG_ 970 LdwActvStats_D_Req 1;
BA_ "U_CD542_MY2021_Rx" SG_ 970 LdwActvStats_D_Req 1;
BA_ "U_U55X_MY2022_Rx" SG_ 970 LdwActvStats_D_Req 1;
BA_ "U_CD764_MY2022_Rx" SG_ 970 LdwActvStats_D_Req 1;
BA_ "U_CDX706_MY2023_Rx" SG_ 970 LdwActvStats_D_Req 1;
BA_ "U_T6_MCA_MY2020_Tx" SG_ 970 LdwActvStats_D_Req 1;
BA_ "U_CD542_MY2021_Tx" SG_ 970 LdwActvStats_D_Req 1;
BA_ "U_U55X_MY2022_Tx" SG_ 970 LdwActvStats_D_Req 1;
BA_ "U_CD764_MY2022_Tx" SG_ 970 LdwActvStats_D_Req 1;
BA_ "U_CDX706_MY2023_Tx" SG_ 970 LdwActvStats_D_Req 1;
BA_ "U_CX727_MY2021_Rx" SG_ 970 LdwActvIntns_D_Req 1;
BA_ "U_P702_MY2021_Rx" SG_ 970 LdwActvIntns_D_Req 1;
BA_ "U_T6_MCA_MY2020_Rx" SG_ 970 LdwActvIntns_D_Req 1;
BA_ "U_CD542_MY2021_Rx" SG_ 970 LdwActvIntns_D_Req 1;
BA_ "U_U55X_MY2022_Rx" SG_ 970 LdwActvIntns_D_Req 1;
BA_ "U_CD764_MY2022_Rx" SG_ 970 LdwActvIntns_D_Req 1;
BA_ "U_CDX706_MY2023_Rx" SG_ 970 LdwActvIntns_D_Req 1;
BA_ "U_T6_MCA_MY2020_Tx" SG_ 970 LdwActvIntns_D_Req 1;
BA_ "U_CD542_MY2021_Tx" SG_ 970 LdwActvIntns_D_Req 1;
BA_ "U_U55X_MY2022_Tx" SG_ 970 LdwActvIntns_D_Req 1;
BA_ "U_CD764_MY2022_Tx" SG_ 970 LdwActvIntns_D_Req 1;
BA_ "U_CDX706_MY2023_Tx" SG_ 970 LdwActvIntns_D_Req 1;
BA_ "GenSigSendType" SG_ 394 AccTrgDist2_D_Dsply 3;
BA_ "U_T6_MCA_MY2020_Tx" SG_ 394 AccTrgDist2_D_Dsply 1;
BA_ "U_CD542_MY2021_Tx" SG_ 394 AccTrgDist2_D_Dsply 1;
BA_ "U_U55X_MY2022_Tx" SG_ 394 AccTrgDist2_D_Dsply 1;
BA_ "U_CD764_MY2022_Tx" SG_ 394 AccTrgDist2_D_Dsply 1;
BA_ "U_CDX706_MY2023_Tx" SG_ 394 AccTrgDist2_D_Dsply 1;
BA_ "GenSigSendType" SG_ 394 AccStopRes_B_Dsply 3;
BA_ "U_T6_MCA_MY2020_Tx" SG_ 394 AccStopRes_B_Dsply 1;
BA_ "U_CD542_MY2021_Tx" SG_ 394 AccStopRes_B_Dsply 1;
BA_ "U_U55X_MY2022_Tx" SG_ 394 AccStopRes_B_Dsply 1;
BA_ "U_CD764_MY2022_Tx" SG_ 394 AccStopRes_B_Dsply 1;
BA_ "U_CDX706_MY2023_Tx" SG_ 394 AccStopRes_B_Dsply 1;
BA_ "GenSigSendType" SG_ 394 TjaWarn_D_Rq 3;
BA_ "U_T6_MCA_MY2020_Tx" SG_ 394 TjaWarn_D_Rq 1;
BA_ "U_CD542_MY2021_Tx" SG_ 394 TjaWarn_D_Rq 1;
BA_ "U_U55X_MY2022_Tx" SG_ 394 TjaWarn_D_Rq 1;
BA_ "U_CD764_MY2022_Tx" SG_ 394 TjaWarn_D_Rq 1;
BA_ "U_CDX706_MY2023_Tx" SG_ 394 TjaWarn_D_Rq 1;
BA_ "GenSigSendType" SG_ 394 Tja_D_Stat 3;
BA_ "U_T6_MCA_MY2020_Rx" SG_ 394 Tja_D_Stat 1;
BA_ "U_CD542_MY2021_Rx" SG_ 394 Tja_D_Stat 1;
BA_ "U_U55X_MY2022_Rx" SG_ 394 Tja_D_Stat 1;
BA_ "U_CD764_MY2022_Rx" SG_ 394 Tja_D_Stat 1;
BA_ "U_CDX706_MY2023_Rx" SG_ 394 Tja_D_Stat 1;
BA_ "U_T6_MCA_MY2020_Tx" SG_ 394 Tja_D_Stat 1;
BA_ "U_CD542_MY2021_Tx" SG_ 394 Tja_D_Stat 1;
BA_ "U_U55X_MY2022_Tx" SG_ 394 Tja_D_Stat 1;
BA_ "U_CD764_MY2022_Tx" SG_ 394 Tja_D_Stat 1;
BA_ "U_CDX706_MY2023_Tx" SG_ 394 Tja_D_Stat 1;
BA_ "GenSigSendType" SG_ 394 TjaMsgTxt_D_Dsply 3;
BA_ "U_T6_MCA_MY2020_Tx" SG_ 394 TjaMsgTxt_D_Dsply 1;
BA_ "U_CD542_MY2021_Tx" SG_ 394 TjaMsgTxt_D_Dsply 1;
BA_ "U_U55X_MY2022_Tx" SG_ 394 TjaMsgTxt_D_Dsply 1;
BA_ "U_CD764_MY2022_Tx" SG_ 394 TjaMsgTxt_D_Dsply 1;
BA_ "U_CDX706_MY2023_Tx" SG_ 394 TjaMsgTxt_D_Dsply 1;
BA_ "GenSigSendType" SG_ 394 IaccLamp_D_Rq 3;
BA_ "U_T6_MCA_MY2020_Tx" SG_ 394 IaccLamp_D_Rq 1;
BA_ "U_CD542_MY2021_Tx" SG_ 394 IaccLamp_D_Rq 1;
BA_ "U_U55X_MY2022_Tx" SG_ 394 IaccLamp_D_Rq 1;
BA_ "U_CD764_MY2022_Tx" SG_ 394 IaccLamp_D_Rq 1;
BA_ "U_CDX706_MY2023_Tx" SG_ 394 IaccLamp_D_Rq 1;
BA_ "GenSigSendType" SG_ 394 AccMsgTxt_D2_Rq 3;
BA_ "U_T6_MCA_MY2020_Tx" SG_ 394 AccMsgTxt_D2_Rq 1;
BA_ "U_CD542_MY2021_Tx" SG_ 394 AccMsgTxt_D2_Rq 1;
BA_ "U_U55X_MY2022_Tx" SG_ 394 AccMsgTxt_D2_Rq 1;
BA_ "U_CD764_MY2022_Tx" SG_ 394 AccMsgTxt_D2_Rq 1;
BA_ "U_CDX706_MY2023_Tx" SG_ 394 AccMsgTxt_D2_Rq 1;
BA_ "GenSigSendType" SG_ 394 FcwDeny_B_Dsply 3;
BA_ "U_T6_MCA_MY2020_Tx" SG_ 394 FcwDeny_B_Dsply 1;
BA_ "U_CD542_MY2021_Tx" SG_ 394 FcwDeny_B_Dsply 1;
BA_ "U_U55X_MY2022_Tx" SG_ 394 FcwDeny_B_Dsply 1;
BA_ "U_CD764_MY2022_Tx" SG_ 394 FcwDeny_B_Dsply 1;
BA_ "U_CDX706_MY2023_Tx" SG_ 394 FcwDeny_B_Dsply 1;
BA_ "GenSigSendType" SG_ 394 FcwMemStat_B_Actl 3;
BA_ "U_T6_MCA_MY2020_Rx" SG_ 394 FcwMemStat_B_Actl 1;
BA_ "ECGUsedRxSignal" SG_ 394 FcwMemStat_B_Actl 1;
BA_ "U_CD542_MY2021_Rx" SG_ 394 FcwMemStat_B_Actl 1;
BA_ "U_U55X_MY2022_Rx" SG_ 394 FcwMemStat_B_Actl 1;
BA_ "U_CD764_MY2022_Rx" SG_ 394 FcwMemStat_B_Actl 1;
BA_ "U_CDX706_MY2023_Rx" SG_ 394 FcwMemStat_B_Actl 1;
BA_ "U_T6_MCA_MY2020_Tx" SG_ 394 FcwMemStat_B_Actl 1;
BA_ "U_CD542_MY2021_Tx" SG_ 394 FcwMemStat_B_Actl 1;
BA_ "U_U55X_MY2022_Tx" SG_ 394 FcwMemStat_B_Actl 1;
BA_ "U_CD764_MY2022_Tx" SG_ 394 FcwMemStat_B_Actl 1;
BA_ "U_CDX706_MY2023_Tx" SG_ 394 FcwMemStat_B_Actl 1;
BA_ "GenSigSendType" SG_ 394 AccTGap_B_Dsply 3;
BA_ "U_T6_MCA_MY2020_Tx" SG_ 394 AccTGap_B_Dsply 1;
BA_ "U_CD542_MY2021_Tx" SG_ 394 AccTGap_B_Dsply 1;
BA_ "U_U55X_MY2022_Tx" SG_ 394 AccTGap_B_Dsply 1;
BA_ "U_CD764_MY2022_Tx" SG_ 394 AccTGap_B_Dsply 1;
BA_ "U_CDX706_MY2023_Tx" SG_ 394 AccTGap_B_Dsply 1;
BA_ "GenSigSendType" SG_ 394 CadsAlignIncplt_B_Actl 3;
BA_ "U_T6_MCA_MY2020_Tx" SG_ 394 CadsAlignIncplt_B_Actl 1;
BA_ "U_CD542_MY2021_Tx" SG_ 394 CadsAlignIncplt_B_Actl 1;
BA_ "U_U55X_MY2022_Tx" SG_ 394 CadsAlignIncplt_B_Actl 1;
BA_ "U_CD764_MY2022_Tx" SG_ 394 CadsAlignIncplt_B_Actl 1;
BA_ "U_CDX706_MY2023_Tx" SG_ 394 CadsAlignIncplt_B_Actl 1;
BA_ "GenSigSendType" SG_ 394 AccFllwMde_B_Dsply 3;
BA_ "U_T6_MCA_MY2020_Tx" SG_ 394 AccFllwMde_B_Dsply 1;
BA_ "U_CD542_MY2021_Tx" SG_ 394 AccFllwMde_B_Dsply 1;
BA_ "U_U55X_MY2022_Tx" SG_ 394 AccFllwMde_B_Dsply 1;
BA_ "U_CD764_MY2022_Tx" SG_ 394 AccFllwMde_B_Dsply 1;
BA_ "U_CDX706_MY2023_Tx" SG_ 394 AccFllwMde_B_Dsply 1;
BA_ "GenSigSendType" SG_ 394 CadsRadrBlck_B_Actl 3;
BA_ "U_T6_MCA_MY2020_Tx" SG_ 394 CadsRadrBlck_B_Actl 1;
BA_ "U_CD542_MY2021_Tx" SG_ 394 CadsRadrBlck_B_Actl 1;
BA_ "U_U55X_MY2022_Tx" SG_ 394 CadsRadrBlck_B_Actl 1;
BA_ "U_CD764_MY2022_Tx" SG_ 394 CadsRadrBlck_B_Actl 1;
BA_ "U_CDX706_MY2023_Tx" SG_ 394 CadsRadrBlck_B_Actl 1;
BA_ "GenSigSendType" SG_ 394 CmbbPostEvnt_B_Dsply 3;
BA_ "U_T6_MCA_MY2020_Tx" SG_ 394 CmbbPostEvnt_B_Dsply 1;
BA_ "U_CD542_MY2021_Tx" SG_ 394 CmbbPostEvnt_B_Dsply 1;
BA_ "U_U55X_MY2022_Tx" SG_ 394 CmbbPostEvnt_B_Dsply 1;
BA_ "U_CD764_MY2022_Tx" SG_ 394 CmbbPostEvnt_B_Dsply 1;
BA_ "U_CDX706_MY2023_Tx" SG_ 394 CmbbPostEvnt_B_Dsply 1;
BA_ "GenSigSendType" SG_ 394 AccStopMde_B_Dsply 3;
BA_ "U_T6_MCA_MY2020_Tx" SG_ 394 AccStopMde_B_Dsply 1;
BA_ "U_CD542_MY2021_Tx" SG_ 394 AccStopMde_B_Dsply 1;
BA_ "U_U55X_MY2022_Tx" SG_ 394 AccStopMde_B_Dsply 1;
BA_ "U_CD764_MY2022_Tx" SG_ 394 AccStopMde_B_Dsply 1;
BA_ "U_CDX706_MY2023_Tx" SG_ 394 AccStopMde_B_Dsply 1;
BA_ "GenSigSendType" SG_ 394 FcwMemSens_D_Actl 3;
BA_ "U_T6_MCA_MY2020_Rx" SG_ 394 FcwMemSens_D_Actl 1;
BA_ "ECGUsedRxSignal" SG_ 394 FcwMemSens_D_Actl 1;
BA_ "U_CD542_MY2021_Rx" SG_ 394 FcwMemSens_D_Actl 1;
BA_ "U_U55X_MY2022_Rx" SG_ 394 FcwMemSens_D_Actl 1;
BA_ "U_CD764_MY2022_Rx" SG_ 394 FcwMemSens_D_Actl 1;
BA_ "U_CDX706_MY2023_Rx" SG_ 394 FcwMemSens_D_Actl 1;
BA_ "U_T6_MCA_MY2020_Tx" SG_ 394 FcwMemSens_D_Actl 1;
BA_ "U_CD542_MY2021_Tx" SG_ 394 FcwMemSens_D_Actl 1;
BA_ "U_U55X_MY2022_Tx" SG_ 394 FcwMemSens_D_Actl 1;
BA_ "U_CD764_MY2022_Tx" SG_ 394 FcwMemSens_D_Actl 1;
BA_ "U_CDX706_MY2023_Tx" SG_ 394 FcwMemSens_D_Actl 1;
BA_ "GenSigSendType" SG_ 394 FcwMsgTxt_D_Rq 3;
BA_ "U_T6_MCA_MY2020_Tx" SG_ 394 FcwMsgTxt_D_Rq 1;
BA_ "U_CD542_MY2021_Tx" SG_ 394 FcwMsgTxt_D_Rq 1;
BA_ "U_U55X_MY2022_Tx" SG_ 394 FcwMsgTxt_D_Rq 1;
BA_ "U_CD764_MY2022_Tx" SG_ 394 FcwMsgTxt_D_Rq 1;
BA_ "U_CDX706_MY2023_Tx" SG_ 394 FcwMsgTxt_D_Rq 1;
BA_ "GenSigSendType" SG_ 394 AccWarn_D_Dsply 3;
BA_ "U_T6_MCA_MY2020_Tx" SG_ 394 AccWarn_D_Dsply 1;
BA_ "U_CD542_MY2021_Tx" SG_ 394 AccWarn_D_Dsply 1;
BA_ "U_U55X_MY2022_Tx" SG_ 394 AccWarn_D_Dsply 1;
BA_ "U_CD764_MY2022_Tx" SG_ 394 AccWarn_D_Dsply 1;
BA_ "U_CDX706_MY2023_Tx" SG_ 394 AccWarn_D_Dsply 1;
BA_ "GenSigSendType" SG_ 394 FcwVisblWarn_B_Rq 3;
BA_ "U_T6_MCA_MY2020_Tx" SG_ 394 FcwVisblWarn_B_Rq 1;
BA_ "U_CD542_MY2021_Tx" SG_ 394 FcwVisblWarn_B_Rq 1;
BA_ "U_U55X_MY2022_Tx" SG_ 394 FcwVisblWarn_B_Rq 1;
BA_ "U_CD764_MY2022_Tx" SG_ 394 FcwVisblWarn_B_Rq 1;
BA_ "U_CDX706_MY2023_Tx" SG_ 394 FcwVisblWarn_B_Rq 1;
BA_ "GenSigSendType" SG_ 394 FcwAudioWarn_B_Rq 3;
BA_ "U_T6_MCA_MY2020_Rx" SG_ 394 FcwAudioWarn_B_Rq 1;
BA_ "ECGUsedRxSignal" SG_ 394 FcwAudioWarn_B_Rq 1;
BA_ "U_CD542_MY2021_Rx" SG_ 394 FcwAudioWarn_B_Rq 1;
BA_ "U_U55X_MY2022_Rx" SG_ 394 FcwAudioWarn_B_Rq 1;
BA_ "U_CD764_MY2022_Rx" SG_ 394 FcwAudioWarn_B_Rq 1;
BA_ "U_CDX706_MY2023_Rx" SG_ 394 FcwAudioWarn_B_Rq 1;
BA_ "U_T6_MCA_MY2020_Tx" SG_ 394 FcwAudioWarn_B_Rq 1;
BA_ "U_CD542_MY2021_Tx" SG_ 394 FcwAudioWarn_B_Rq 1;
BA_ "U_U55X_MY2022_Tx" SG_ 394 FcwAudioWarn_B_Rq 1;
BA_ "U_CD764_MY2022_Tx" SG_ 394 FcwAudioWarn_B_Rq 1;
BA_ "U_CDX706_MY2023_Tx" SG_ 394 FcwAudioWarn_B_Rq 1;
BA_ "GenSigSendType" SG_ 394 AccTGap_D_Dsply 3;
BA_ "GenSigStartValueInteger" SG_ 394 AccTGap_D_Dsply 3;
BA_ "GenSigStartValue" SG_ 394 AccTGap_D_Dsply 3;
BA_ "U_T6_MCA_MY2020_Tx" SG_ 394 AccTGap_D_Dsply 1;
BA_ "U_CD542_MY2021_Tx" SG_ 394 AccTGap_D_Dsply 1;
BA_ "U_U55X_MY2022_Tx" SG_ 394 AccTGap_D_Dsply 1;
BA_ "U_CD764_MY2022_Tx" SG_ 394 AccTGap_D_Dsply 1;
BA_ "U_CDX706_MY2023_Tx" SG_ 394 AccTGap_D_Dsply 1;
BA_ "GenSigSendType" SG_ 394 AccMemEnbl_B_RqDrv 3;
BA_ "GenSigStartValueInteger" SG_ 394 AccMemEnbl_B_RqDrv 1;
BA_ "GenSigStartValue" SG_ 394 AccMemEnbl_B_RqDrv 1;
BA_ "U_T6_MCA_MY2020_Tx" SG_ 394 AccMemEnbl_B_RqDrv 1;
BA_ "U_CD542_MY2021_Tx" SG_ 394 AccMemEnbl_B_RqDrv 1;
BA_ "U_U55X_MY2022_Tx" SG_ 394 AccMemEnbl_B_RqDrv 1;
BA_ "U_CD764_MY2022_Tx" SG_ 394 AccMemEnbl_B_RqDrv 1;
BA_ "U_CDX706_MY2023_Tx" SG_ 394 AccMemEnbl_B_RqDrv 1;
BA_ "GenSigSendType" SG_ 394 AccStopStat_D_Dsply 3;
BA_ "U_T6_MCA_MY2020_Tx" SG_ 394 AccStopStat_D_Dsply 1;
BA_ "U_CD542_MY2021_Tx" SG_ 394 AccStopStat_D_Dsply 1;
BA_ "U_U55X_MY2022_Tx" SG_ 394 AccStopStat_D_Dsply 1;
BA_ "U_CD764_MY2022_Tx" SG_ 394 AccStopStat_D_Dsply 1;
BA_ "U_CDX706_MY2023_Tx" SG_ 394 AccStopStat_D_Dsply 1;
BA_ "GenSigSendType" SG_ 394 HaDsply_No_Cs 3;
BA_ "ContentDependant" SG_ 394 HaDsply_No_Cs 1;
BA_ "MetaData" SG_ 394 HaDsply_No_Cs 1;
BA_ "U_T6_MCA_MY2020_Tx" SG_ 394 HaDsply_No_Cs 1;
BA_ "U_U55X_MY2022_Tx" SG_ 394 HaDsply_No_Cs 1;
BA_ "U_CD764_MY2022_Tx" SG_ 394 HaDsply_No_Cs 1;
BA_ "U_CDX706_MY2023_Tx" SG_ 394 HaDsply_No_Cs 1;
BA_ "GenSigSendType" SG_ 394 HaDsply_No_Cnt 3;
BA_ "ContentDependant" SG_ 394 HaDsply_No_Cnt 1;
BA_ "MetaData" SG_ 394 HaDsply_No_Cnt 1;
BA_ "U_T6_MCA_MY2020_Tx" SG_ 394 HaDsply_No_Cnt 1;
BA_ "U_U55X_MY2022_Tx" SG_ 394 HaDsply_No_Cnt 1;
BA_ "U_CD764_MY2022_Tx" SG_ 394 HaDsply_No_Cnt 1;
BA_ "U_CDX706_MY2023_Tx" SG_ 394 HaDsply_No_Cnt 1;
BA_ "MetaData" SG_ 391 CmbbBrkDecel_No_Cnt 1;
BA_ "U_CX727_MY2021_Rx" SG_ 391 CmbbBrkDecel_No_Cnt 1;
BA_ "U_P702_MY2021_Rx" SG_ 391 CmbbBrkDecel_No_Cnt 1;
BA_ "U_T6_MCA_MY2020_Rx" SG_ 391 CmbbBrkDecel_No_Cnt 1;
BA_ "U_CD542_MY2021_Rx" SG_ 391 CmbbBrkDecel_No_Cnt 1;
BA_ "U_U55X_MY2022_Rx" SG_ 391 CmbbBrkDecel_No_Cnt 1;
BA_ "U_CD764_MY2022_Rx" SG_ 391 CmbbBrkDecel_No_Cnt 1;
BA_ "U_CDX706_MY2023_Rx" SG_ 391 CmbbBrkDecel_No_Cnt 1;
BA_ "U_T6_MCA_MY2020_Tx" SG_ 391 CmbbBrkDecel_No_Cnt 1;
BA_ "U_CD542_MY2021_Tx" SG_ 391 CmbbBrkDecel_No_Cnt 1;
BA_ "U_U55X_MY2022_Tx" SG_ 391 CmbbBrkDecel_No_Cnt 1;
BA_ "U_CD764_MY2022_Tx" SG_ 391 CmbbBrkDecel_No_Cnt 1;
BA_ "U_CDX706_MY2023_Tx" SG_ 391 CmbbBrkDecel_No_Cnt 1;
BA_ "U_T6_MCA_MY2020_Tx" SG_ 391 HudDsplyIntns_No_Actl 1;
BA_ "U_CD542_MY2021_Tx" SG_ 391 HudDsplyIntns_No_Actl 1;
BA_ "U_U55X_MY2022_Tx" SG_ 391 HudDsplyIntns_No_Actl 1;
BA_ "U_CD764_MY2022_Tx" SG_ 391 HudDsplyIntns_No_Actl 1;
BA_ "U_CDX706_MY2023_Tx" SG_ 391 HudDsplyIntns_No_Actl 1;
BA_ "U_T6_MCA_MY2020_Tx" SG_ 391 HudBlk3_B_Rq 1;
BA_ "U_CD542_MY2021_Tx" SG_ 391 HudBlk3_B_Rq 1;
BA_ "U_U55X_MY2022_Tx" SG_ 391 HudBlk3_B_Rq 1;
BA_ "U_CD764_MY2022_Tx" SG_ 391 HudBlk3_B_Rq 1;
BA_ "U_CDX706_MY2023_Tx" SG_ 391 HudBlk3_B_Rq 1;
BA_ "U_T6_MCA_MY2020_Tx" SG_ 391 HudBlk2_B_Rq 1;
BA_ "U_CD542_MY2021_Tx" SG_ 391 HudBlk2_B_Rq 1;
BA_ "U_U55X_MY2022_Tx" SG_ 391 HudBlk2_B_Rq 1;
BA_ "U_CD764_MY2022_Tx" SG_ 391 HudBlk2_B_Rq 1;
BA_ "U_CDX706_MY2023_Tx" SG_ 391 HudBlk2_B_Rq 1;
BA_ "U_T6_MCA_MY2020_Tx" SG_ 391 HudBlk1_B_Rq 1;
BA_ "U_CD542_MY2021_Tx" SG_ 391 HudBlk1_B_Rq 1;
BA_ "U_U55X_MY2022_Tx" SG_ 391 HudBlk1_B_Rq 1;
BA_ "U_CD764_MY2022_Tx" SG_ 391 HudBlk1_B_Rq 1;
BA_ "U_CDX706_MY2023_Tx" SG_ 391 HudBlk1_B_Rq 1;
BA_ "U_T6_MCA_MY2020_Tx" SG_ 391 HudFlashRate_D_Actl 1;
BA_ "U_CD542_MY2021_Tx" SG_ 391 HudFlashRate_D_Actl 1;
BA_ "U_U55X_MY2022_Tx" SG_ 391 HudFlashRate_D_Actl 1;
BA_ "U_CD764_MY2022_Tx" SG_ 391 HudFlashRate_D_Actl 1;
BA_ "U_CDX706_MY2023_Tx" SG_ 391 HudFlashRate_D_Actl 1;
BA_ "MetaData" SG_ 391 CmbbBrkDecel_No_Cs 1;
BA_ "U_CX727_MY2021_Rx" SG_ 391 CmbbBrkDecel_No_Cs 1;
BA_ "U_P702_MY2021_Rx" SG_ 391 CmbbBrkDecel_No_Cs 1;
BA_ "U_T6_MCA_MY2020_Rx" SG_ 391 CmbbBrkDecel_No_Cs 1;
BA_ "U_CD542_MY2021_Rx" SG_ 391 CmbbBrkDecel_No_Cs 1;
BA_ "U_U55X_MY2022_Rx" SG_ 391 CmbbBrkDecel_No_Cs 1;
BA_ "U_CD764_MY2022_Rx" SG_ 391 CmbbBrkDecel_No_Cs 1;
BA_ "U_CDX706_MY2023_Rx" SG_ 391 CmbbBrkDecel_No_Cs 1;
BA_ "U_T6_MCA_MY2020_Tx" SG_ 391 CmbbBrkDecel_No_Cs 1;
BA_ "U_CD542_MY2021_Tx" SG_ 391 CmbbBrkDecel_No_Cs 1;
BA_ "U_U55X_MY2022_Tx" SG_ 391 CmbbBrkDecel_No_Cs 1;
BA_ "U_CD764_MY2022_Tx" SG_ 391 CmbbBrkDecel_No_Cs 1;
BA_ "U_CDX706_MY2023_Tx" SG_ 391 CmbbBrkDecel_No_Cs 1;
BA_ "GenSigStartValueInteger" SG_ 391 CmbbBrkDecel_A_Rq 5129;
BA_ "U_CX727_MY2021_Rx" SG_ 391 CmbbBrkDecel_A_Rq 1;
BA_ "U_P702_MY2021_Rx" SG_ 391 CmbbBrkDecel_A_Rq 1;
BA_ "U_T6_MCA_MY2020_Rx" SG_ 391 CmbbBrkDecel_A_Rq 1;
BA_ "U_CD542_MY2021_Rx" SG_ 391 CmbbBrkDecel_A_Rq 1;
BA_ "U_U55X_MY2022_Rx" SG_ 391 CmbbBrkDecel_A_Rq 1;
BA_ "U_CD764_MY2022_Rx" SG_ 391 CmbbBrkDecel_A_Rq 1;
BA_ "U_CDX706_MY2023_Rx" SG_ 391 CmbbBrkDecel_A_Rq 1;
BA_ "U_T6_MCA_MY2020_Tx" SG_ 391 CmbbBrkDecel_A_Rq 1;
BA_ "U_CD542_MY2021_Tx" SG_ 391 CmbbBrkDecel_A_Rq 1;
BA_ "U_U55X_MY2022_Tx" SG_ 391 CmbbBrkDecel_A_Rq 1;
BA_ "U_CD764_MY2022_Tx" SG_ 391 CmbbBrkDecel_A_Rq 1;
BA_ "U_CDX706_MY2023_Tx" SG_ 391 CmbbBrkDecel_A_Rq 1;
BA_ "U_CX727_MY2021_Rx" SG_ 391 CmbbBrkPrchg_D_Rq 1;
BA_ "U_P702_MY2021_Rx" SG_ 391 CmbbBrkPrchg_D_Rq 1;
BA_ "U_T6_MCA_MY2020_Rx" SG_ 391 CmbbBrkPrchg_D_Rq 1;
BA_ "ECGUsedRxSignal" SG_ 391 CmbbBrkPrchg_D_Rq 1;
BA_ "U_CD542_MY2021_Rx" SG_ 391 CmbbBrkPrchg_D_Rq 1;
BA_ "U_U55X_MY2022_Rx" SG_ 391 CmbbBrkPrchg_D_Rq 1;
BA_ "U_CD764_MY2022_Rx" SG_ 391 CmbbBrkPrchg_D_Rq 1;
BA_ "U_CDX706_MY2023_Rx" SG_ 391 CmbbBrkPrchg_D_Rq 1;
BA_ "U_T6_MCA_MY2020_Tx" SG_ 391 CmbbBrkPrchg_D_Rq 1;
BA_ "U_CD542_MY2021_Tx" SG_ 391 CmbbBrkPrchg_D_Rq 1;
BA_ "U_U55X_MY2022_Tx" SG_ 391 CmbbBrkPrchg_D_Rq 1;
BA_ "U_CD764_MY2022_Tx" SG_ 391 CmbbBrkPrchg_D_Rq 1;
BA_ "U_CDX706_MY2023_Tx" SG_ 391 CmbbBrkPrchg_D_Rq 1;
BA_ "U_CX727_MY2021_Rx" SG_ 391 CmbbBrkDecel_B_Rq 1;
BA_ "U_P702_MY2021_Rx" SG_ 391 CmbbBrkDecel_B_Rq 1;
BA_ "U_T6_MCA_MY2020_Rx" SG_ 391 CmbbBrkDecel_B_Rq 1;
BA_ "ECGUsedRxSignal" SG_ 391 CmbbBrkDecel_B_Rq 1;
BA_ "U_CD542_MY2021_Rx" SG_ 391 CmbbBrkDecel_B_Rq 1;
BA_ "U_U55X_MY2022_Rx" SG_ 391 CmbbBrkDecel_B_Rq 1;
BA_ "U_CD764_MY2022_Rx" SG_ 391 CmbbBrkDecel_B_Rq 1;
BA_ "U_CDX706_MY2023_Rx" SG_ 391 CmbbBrkDecel_B_Rq 1;
BA_ "U_T6_MCA_MY2020_Tx" SG_ 391 CmbbBrkDecel_B_Rq 1;
BA_ "U_CD542_MY2021_Tx" SG_ 391 CmbbBrkDecel_B_Rq 1;
BA_ "U_U55X_MY2022_Tx" SG_ 391 CmbbBrkDecel_B_Rq 1;
BA_ "U_CD764_MY2022_Tx" SG_ 391 CmbbBrkDecel_B_Rq 1;
BA_ "U_CDX706_MY2023_Tx" SG_ 391 CmbbBrkDecel_B_Rq 1;
BA_ "U_CX727_MY2021_Rx" SG_ 391 CmbbBaSens_D_Rq 1;
BA_ "U_P702_MY2021_Rx" SG_ 391 CmbbBaSens_D_Rq 1;
BA_ "U_T6_MCA_MY2020_Rx" SG_ 391 CmbbBaSens_D_Rq 1;
BA_ "U_CD542_MY2021_Rx" SG_ 391 CmbbBaSens_D_Rq 1;
BA_ "U_U55X_MY2022_Rx" SG_ 391 CmbbBaSens_D_Rq 1;
BA_ "U_CD764_MY2022_Rx" SG_ 391 CmbbBaSens_D_Rq 1;
BA_ "U_CDX706_MY2023_Rx" SG_ 391 CmbbBaSens_D_Rq 1;
BA_ "U_T6_MCA_MY2020_Tx" SG_ 391 CmbbBaSens_D_Rq 1;
BA_ "U_CD542_MY2021_Tx" SG_ 391 CmbbBaSens_D_Rq 1;
BA_ "U_U55X_MY2022_Tx" SG_ 391 CmbbBaSens_D_Rq 1;
BA_ "U_CD764_MY2022_Tx" SG_ 391 CmbbBaSens_D_Rq 1;
BA_ "U_CDX706_MY2023_Tx" SG_ 391 CmbbBaSens_D_Rq 1;
BA_ "GenSigStartValueInteger" SG_ 390 AccBrkTot_A_Rq 5129;
BA_ "U_CX727_MY2021_Rx" SG_ 390 AccBrkTot_A_Rq 1;
BA_ "U_P702_MY2021_Rx" SG_ 390 AccBrkTot_A_Rq 1;
BA_ "U_T6_MCA_MY2020_Rx" SG_ 390 AccBrkTot_A_Rq 1;
BA_ "U_CD542_MY2021_Rx" SG_ 390 AccBrkTot_A_Rq 1;
BA_ "U_U55X_MY2022_Rx" SG_ 390 AccBrkTot_A_Rq 1;
BA_ "U_CD764_MY2022_Rx" SG_ 390 AccBrkTot_A_Rq 1;
BA_ "U_CDX706_MY2023_Rx" SG_ 390 AccBrkTot_A_Rq 1;
BA_ "U_T6_MCA_MY2020_Tx" SG_ 390 AccBrkTot_A_Rq 1;
BA_ "U_CD542_MY2021_Tx" SG_ 390 AccBrkTot_A_Rq 1;
BA_ "U_U55X_MY2022_Tx" SG_ 390 AccBrkTot_A_Rq 1;
BA_ "U_CD764_MY2022_Tx" SG_ 390 AccBrkTot_A_Rq 1;
BA_ "U_CDX706_MY2023_Tx" SG_ 390 AccBrkTot_A_Rq 1;
BA_ "U_CX727_MY2021_Rx" SG_ 390 AccPrpl_A_Pred 1;
BA_ "U_P702_MY2021_Rx" SG_ 390 AccPrpl_A_Pred 1;
BA_ "U_T6_MCA_MY2020_Rx" SG_ 390 AccPrpl_A_Pred 1;
BA_ "U_CD542_MY2021_Rx" SG_ 390 AccPrpl_A_Pred 1;
BA_ "U_U55X_MY2022_Rx" SG_ 390 AccPrpl_A_Pred 1;
BA_ "U_CD764_MY2022_Rx" SG_ 390 AccPrpl_A_Pred 1;
BA_ "U_CDX706_MY2023_Rx" SG_ 390 AccPrpl_A_Pred 1;
BA_ "U_T6_MCA_MY2020_Tx" SG_ 390 AccPrpl_A_Pred 1;
BA_ "U_CD542_MY2021_Tx" SG_ 390 AccPrpl_A_Pred 1;
BA_ "U_U55X_MY2022_Tx" SG_ 390 AccPrpl_A_Pred 1;
BA_ "U_CD764_MY2022_Tx" SG_ 390 AccPrpl_A_Pred 1;
BA_ "U_CDX706_MY2023_Tx" SG_ 390 AccPrpl_A_Pred 1;
BA_ "U_P702_MY2021_Rx" SG_ 390 AccVeh_V_Trg 1;
BA_ "U_T6_MCA_MY2020_Rx" SG_ 390 AccVeh_V_Trg 1;
BA_ "U_CD542_MY2021_Rx" SG_ 390 AccVeh_V_Trg 1;
BA_ "U_U55X_MY2022_Rx" SG_ 390 AccVeh_V_Trg 1;
BA_ "U_CD764_MY2022_Rx" SG_ 390 AccVeh_V_Trg 1;
BA_ "U_CDX706_MY2023_Rx" SG_ 390 AccVeh_V_Trg 1;
BA_ "U_T6_MCA_MY2020_Tx" SG_ 390 AccVeh_V_Trg 1;
BA_ "U_CD542_MY2021_Tx" SG_ 390 AccVeh_V_Trg 1;
BA_ "U_U55X_MY2022_Tx" SG_ 390 AccVeh_V_Trg 1;
BA_ "U_CD764_MY2022_Tx" SG_ 390 AccVeh_V_Trg 1;
BA_ "U_CDX706_MY2023_Tx" SG_ 390 AccVeh_V_Trg 1;
BA_ "U_CX727_MY2021_Rx" SG_ 390 AccBrkPrkEl_B_Rq 1;
BA_ "U_P702_MY2021_Rx" SG_ 390 AccBrkPrkEl_B_Rq 1;
BA_ "U_T6_MCA_MY2020_Rx" SG_ 390 AccBrkPrkEl_B_Rq 1;
BA_ "U_CD542_MY2021_Rx" SG_ 390 AccBrkPrkEl_B_Rq 1;
BA_ "U_U55X_MY2022_Rx" SG_ 390 AccBrkPrkEl_B_Rq 1;
BA_ "U_CD764_MY2022_Rx" SG_ 390 AccBrkPrkEl_B_Rq 1;
BA_ "U_CDX706_MY2023_Rx" SG_ 390 AccBrkPrkEl_B_Rq 1;
BA_ "U_T6_MCA_MY2020_Tx" SG_ 390 AccBrkPrkEl_B_Rq 1;
BA_ "U_CD542_MY2021_Tx" SG_ 390 AccBrkPrkEl_B_Rq 1;
BA_ "U_U55X_MY2022_Tx" SG_ 390 AccBrkPrkEl_B_Rq 1;
BA_ "U_CD764_MY2022_Tx" SG_ 390 AccBrkPrkEl_B_Rq 1;
BA_ "U_CDX706_MY2023_Tx" SG_ 390 AccBrkPrkEl_B_Rq 1;
BA_ "U_T6_MCA_MY2020_Tx" SG_ 390 Cmbb_B_Enbl 1;
BA_ "U_CD542_MY2021_Tx" SG_ 390 Cmbb_B_Enbl 1;
BA_ "U_U55X_MY2022_Tx" SG_ 390 Cmbb_B_Enbl 1;
BA_ "U_CD764_MY2022_Tx" SG_ 390 Cmbb_B_Enbl 1;
BA_ "U_CDX706_MY2023_Tx" SG_ 390 Cmbb_B_Enbl 1;
BA_ "U_T6_MCA_MY2020_Tx" SG_ 390 CmbbOvrrd_B_RqDrv 1;
BA_ "U_CD542_MY2021_Tx" SG_ 390 CmbbOvrrd_B_RqDrv 1;
BA_ "U_U55X_MY2022_Tx" SG_ 390 CmbbOvrrd_B_RqDrv 1;
BA_ "U_CD764_MY2022_Tx" SG_ 390 CmbbOvrrd_B_RqDrv 1;
BA_ "U_CDX706_MY2023_Tx" SG_ 390 CmbbOvrrd_B_RqDrv 1;
BA_ "U_CX727_MY2021_Rx" SG_ 390 CmbbDeny_B_Actl 1;
BA_ "U_P702_MY2021_Rx" SG_ 390 CmbbDeny_B_Actl 1;
BA_ "U_T6_MCA_MY2020_Rx" SG_ 390 CmbbDeny_B_Actl 1;
BA_ "U_CD542_MY2021_Rx" SG_ 390 CmbbDeny_B_Actl 1;
BA_ "U_U55X_MY2022_Rx" SG_ 390 CmbbDeny_B_Actl 1;
BA_ "U_CD764_MY2022_Rx" SG_ 390 CmbbDeny_B_Actl 1;
BA_ "U_CDX706_MY2023_Rx" SG_ 390 CmbbDeny_B_Actl 1;
BA_ "U_T6_MCA_MY2020_Tx" SG_ 390 CmbbDeny_B_Actl 1;
BA_ "U_CD542_MY2021_Tx" SG_ 390 CmbbDeny_B_Actl 1;
BA_ "U_U55X_MY2022_Tx" SG_ 390 CmbbDeny_B_Actl 1;
BA_ "U_CD764_MY2022_Tx" SG_ 390 CmbbDeny_B_Actl 1;
BA_ "U_CDX706_MY2023_Tx" SG_ 390 CmbbDeny_B_Actl 1;
BA_ "U_CX727_MY2021_Rx" SG_ 390 CmbbEngTqMn_B_Rq 1;
BA_ "U_P702_MY2021_Rx" SG_ 390 CmbbEngTqMn_B_Rq 1;
BA_ "U_T6_MCA_MY2020_Rx" SG_ 390 CmbbEngTqMn_B_Rq 1;
BA_ "U_CD542_MY2021_Rx" SG_ 390 CmbbEngTqMn_B_Rq 1;
BA_ "U_U55X_MY2022_Rx" SG_ 390 CmbbEngTqMn_B_Rq 1;
BA_ "U_CD764_MY2022_Rx" SG_ 390 CmbbEngTqMn_B_Rq 1;
BA_ "U_CDX706_MY2023_Rx" SG_ 390 CmbbEngTqMn_B_Rq 1;
BA_ "U_T6_MCA_MY2020_Tx" SG_ 390 CmbbEngTqMn_B_Rq 1;
BA_ "U_CD542_MY2021_Tx" SG_ 390 CmbbEngTqMn_B_Rq 1;
BA_ "U_U55X_MY2022_Tx" SG_ 390 CmbbEngTqMn_B_Rq 1;
BA_ "U_CD764_MY2022_Tx" SG_ 390 CmbbEngTqMn_B_Rq 1;
BA_ "U_CDX706_MY2023_Tx" SG_ 390 CmbbEngTqMn_B_Rq 1;
BA_ "U_CX727_MY2021_Rx" SG_ 390 AccPrpl_A_Rq 1;
BA_ "U_P702_MY2021_Rx" SG_ 390 AccPrpl_A_Rq 1;
BA_ "U_T6_MCA_MY2020_Rx" SG_ 390 AccPrpl_A_Rq 1;
BA_ "U_CD542_MY2021_Rx" SG_ 390 AccPrpl_A_Rq 1;
BA_ "U_U55X_MY2022_Rx" SG_ 390 AccPrpl_A_Rq 1;
BA_ "U_CD764_MY2022_Rx" SG_ 390 AccPrpl_A_Rq 1;
BA_ "U_CDX706_MY2023_Rx" SG_ 390 AccPrpl_A_Rq 1;
BA_ "U_T6_MCA_MY2020_Tx" SG_ 390 AccPrpl_A_Rq 1;
BA_ "U_CD542_MY2021_Tx" SG_ 390 AccPrpl_A_Rq 1;
BA_ "U_U55X_MY2022_Tx" SG_ 390 AccPrpl_A_Rq 1;
BA_ "U_CD764_MY2022_Tx" SG_ 390 AccPrpl_A_Rq 1;
BA_ "U_CDX706_MY2023_Tx" SG_ 390 AccPrpl_A_Rq 1;
BA_ "U_CX727_MY2021_Rx" SG_ 390 AccDeny_B_Rq 1;
BA_ "U_P702_MY2021_Rx" SG_ 390 AccDeny_B_Rq 1;
BA_ "U_T6_MCA_MY2020_Rx" SG_ 390 AccDeny_B_Rq 1;
BA_ "U_CD542_MY2021_Rx" SG_ 390 AccDeny_B_Rq 1;
BA_ "U_U55X_MY2022_Rx" SG_ 390 AccDeny_B_Rq 1;
BA_ "U_CD764_MY2022_Rx" SG_ 390 AccDeny_B_Rq 1;
BA_ "U_CDX706_MY2023_Rx" SG_ 390 AccDeny_B_Rq 1;
BA_ "U_T6_MCA_MY2020_Tx" SG_ 390 AccDeny_B_Rq 1;
BA_ "U_CD542_MY2021_Tx" SG_ 390 AccDeny_B_Rq 1;
BA_ "U_U55X_MY2022_Tx" SG_ 390 AccDeny_B_Rq 1;
BA_ "U_CD764_MY2022_Tx" SG_ 390 AccDeny_B_Rq 1;
BA_ "U_CDX706_MY2023_Tx" SG_ 390 AccDeny_B_Rq 1;
BA_ "WakeupSignal" SG_ 390 AccResumEnbl_B_Rq 1;
BA_ "U_CX727_MY2021_Rx" SG_ 390 AccResumEnbl_B_Rq 1;
BA_ "U_P702_MY2021_Rx" SG_ 390 AccResumEnbl_B_Rq 1;
BA_ "U_T6_MCA_MY2020_Rx" SG_ 390 AccResumEnbl_B_Rq 1;
BA_ "U_CD542_MY2021_Rx" SG_ 390 AccResumEnbl_B_Rq 1;
BA_ "U_U55X_MY2022_Rx" SG_ 390 AccResumEnbl_B_Rq 1;
BA_ "U_CD764_MY2022_Rx" SG_ 390 AccResumEnbl_B_Rq 1;
BA_ "U_CDX706_MY2023_Rx" SG_ 390 AccResumEnbl_B_Rq 1;
BA_ "U_T6_MCA_MY2020_Tx" SG_ 390 AccResumEnbl_B_Rq 1;
BA_ "U_CD542_MY2021_Tx" SG_ 390 AccResumEnbl_B_Rq 1;
BA_ "U_U55X_MY2022_Tx" SG_ 390 AccResumEnbl_B_Rq 1;
BA_ "U_CD764_MY2022_Tx" SG_ 390 AccResumEnbl_B_Rq 1;
BA_ "U_CDX706_MY2023_Tx" SG_ 390 AccResumEnbl_B_Rq 1;
BA_ "U_CX727_MY2021_Rx" SG_ 390 AccCancl_B_Rq 1;
BA_ "U_P702_MY2021_Rx" SG_ 390 AccCancl_B_Rq 1;
BA_ "U_T6_MCA_MY2020_Rx" SG_ 390 AccCancl_B_Rq 1;
BA_ "U_CD542_MY2021_Rx" SG_ 390 AccCancl_B_Rq 1;
BA_ "U_U55X_MY2022_Rx" SG_ 390 AccCancl_B_Rq 1;
BA_ "U_CD764_MY2022_Rx" SG_ 390 AccCancl_B_Rq 1;
BA_ "U_CDX706_MY2023_Rx" SG_ 390 AccCancl_B_Rq 1;
BA_ "U_T6_MCA_MY2020_Tx" SG_ 390 AccCancl_B_Rq 1;
BA_ "U_CD542_MY2021_Tx" SG_ 390 AccCancl_B_Rq 1;
BA_ "U_U55X_MY2022_Tx" SG_ 390 AccCancl_B_Rq 1;
BA_ "U_CD764_MY2022_Tx" SG_ 390 AccCancl_B_Rq 1;
BA_ "U_CDX706_MY2023_Tx" SG_ 390 AccCancl_B_Rq 1;
BA_ "U_CX727_MY2021_Rx" SG_ 390 AccBrkPrchg_B_Rq 1;
BA_ "U_P702_MY2021_Rx" SG_ 390 AccBrkPrchg_B_Rq 1;
BA_ "U_T6_MCA_MY2020_Rx" SG_ 390 AccBrkPrchg_B_Rq 1;
BA_ "U_CD542_MY2021_Rx" SG_ 390 AccBrkPrchg_B_Rq 1;
BA_ "U_U55X_MY2022_Rx" SG_ 390 AccBrkPrchg_B_Rq 1;
BA_ "U_CD764_MY2022_Rx" SG_ 390 AccBrkPrchg_B_Rq 1;
BA_ "U_CDX706_MY2023_Rx" SG_ 390 AccBrkPrchg_B_Rq 1;
BA_ "U_T6_MCA_MY2020_Tx" SG_ 390 AccBrkPrchg_B_Rq 1;
BA_ "U_CD542_MY2021_Tx" SG_ 390 AccBrkPrchg_B_Rq 1;
BA_ "U_U55X_MY2022_Tx" SG_ 390 AccBrkPrchg_B_Rq 1;
BA_ "U_CD764_MY2022_Tx" SG_ 390 AccBrkPrchg_B_Rq 1;
BA_ "U_CDX706_MY2023_Tx" SG_ 390 AccBrkPrchg_B_Rq 1;
BA_ "U_CX727_MY2021_Rx" SG_ 390 AccBrkDecel_B_Rq 1;
BA_ "U_P702_MY2021_Rx" SG_ 390 AccBrkDecel_B_Rq 1;
BA_ "U_T6_MCA_MY2020_Rx" SG_ 390 AccBrkDecel_B_Rq 1;
BA_ "U_CD542_MY2021_Rx" SG_ 390 AccBrkDecel_B_Rq 1;
BA_ "U_U55X_MY2022_Rx" SG_ 390 AccBrkDecel_B_Rq 1;
BA_ "U_CD764_MY2022_Rx" SG_ 390 AccBrkDecel_B_Rq 1;
BA_ "U_CDX706_MY2023_Rx" SG_ 390 AccBrkDecel_B_Rq 1;
BA_ "U_T6_MCA_MY2020_Tx" SG_ 390 AccBrkDecel_B_Rq 1;
BA_ "U_CD542_MY2021_Tx" SG_ 390 AccBrkDecel_B_Rq 1;
BA_ "U_U55X_MY2022_Tx" SG_ 390 AccBrkDecel_B_Rq 1;
BA_ "U_CD764_MY2022_Tx" SG_ 390 AccBrkDecel_B_Rq 1;
BA_ "U_CDX706_MY2023_Tx" SG_ 390 AccBrkDecel_B_Rq 1;
BA_ "U_CX727_MY2021_Rx" SG_ 390 AccStopStat_B_Rq 1;
BA_ "U_P702_MY2021_Rx" SG_ 390 AccStopStat_B_Rq 1;
BA_ "U_T6_MCA_MY2020_Rx" SG_ 390 AccStopStat_B_Rq 1;
BA_ "U_CD542_MY2021_Rx" SG_ 390 AccStopStat_B_Rq 1;
BA_ "U_U55X_MY2022_Rx" SG_ 390 AccStopStat_B_Rq 1;
BA_ "U_CD764_MY2022_Rx" SG_ 390 AccStopStat_B_Rq 1;
BA_ "U_CDX706_MY2023_Rx" SG_ 390 AccStopStat_B_Rq 1;
BA_ "U_T6_MCA_MY2020_Tx" SG_ 390 AccStopStat_B_Rq 1;
BA_ "U_CD542_MY2021_Tx" SG_ 390 AccStopStat_B_Rq 1;
BA_ "U_U55X_MY2022_Tx" SG_ 390 AccStopStat_B_Rq 1;
BA_ "U_CD764_MY2022_Tx" SG_ 390 AccStopStat_B_Rq 1;
BA_ "U_CDX706_MY2023_Tx" SG_ 390 AccStopStat_B_Rq 1;
BA_ "U_T6_MCA_MY2020_Rx" SG_ 390 AccAutoResum_D_Rq 1;
BA_ "U_U55X_MY2022_Rx" SG_ 390 AccAutoResum_D_Rq 1;
BA_ "U_CD764_MY2022_Rx" SG_ 390 AccAutoResum_D_Rq 1;
BA_ "U_CDX706_MY2023_Rx" SG_ 390 AccAutoResum_D_Rq 1;
BA_ "U_T6_MCA_MY2020_Tx" SG_ 390 AccAutoResum_D_Rq 1;
BA_ "U_CD542_MY2021_Tx" SG_ 390 AccAutoResum_D_Rq 1;
BA_ "U_U55X_MY2022_Tx" SG_ 390 AccAutoResum_D_Rq 1;
BA_ "U_CD764_MY2022_Tx" SG_ 390 AccAutoResum_D_Rq 1;
BA_ "U_CDX706_MY2023_Tx" SG_ 390 AccAutoResum_D_Rq 1;
BA_ "U_T6_MCA_MY2020_Rx" SG_ 390 AccBrkPulse_B_Rq 1;
BA_ "U_CD542_MY2021_Rx" SG_ 390 AccBrkPulse_B_Rq 1;
BA_ "U_U55X_MY2022_Rx" SG_ 390 AccBrkPulse_B_Rq 1;
BA_ "U_CD764_MY2022_Rx" SG_ 390 AccBrkPulse_B_Rq 1;
BA_ "U_CDX706_MY2023_Rx" SG_ 390 AccBrkPulse_B_Rq 1;
BA_ "U_T6_MCA_MY2020_Tx" SG_ 390 AccBrkPulse_B_Rq 1;
BA_ "U_CD542_MY2021_Tx" SG_ 390 AccBrkPulse_B_Rq 1;
BA_ "U_U55X_MY2022_Tx" SG_ 390 AccBrkPulse_B_Rq 1;
BA_ "U_CD764_MY2022_Tx" SG_ 390 AccBrkPulse_B_Rq 1;
BA_ "U_CDX706_MY2023_Tx" SG_ 390 AccBrkPulse_B_Rq 1;
BA_ "GenSigStartValueInteger" SG_ 1441 TCCM_GWOnBoardTester 255;
BA_ "ContentDependant" SG_ 1441 TCCM_GWOnBoardTester 1;
BA_ "GenSigStartValue" SG_ 1441 TCCM_GWOnBoardTester 255;
BA_ "U_P702_MY2021_Tx" SG_ 1441 TCCM_GWOnBoardTester 1;
BA_ "U_U55X_MY2022_Tx" SG_ 1441 TCCM_GWOnBoardTester 1;
BA_ "GenSigStartValueInteger" SG_ 1441 TCCM_GWNMProxy 255;
BA_ "ContentDependant" SG_ 1441 TCCM_GWNMProxy 1;
BA_ "GenSigStartValue" SG_ 1441 TCCM_GWNMProxy 255;
BA_ "U_P702_MY2021_Tx" SG_ 1441 TCCM_GWNMProxy 1;
BA_ "U_U55X_MY2022_Tx" SG_ 1441 TCCM_GWNMProxy 1;
BA_ "GenSigStartValueInteger" SG_ 1441 TCCM_AutoSarNMReserved4 255;
BA_ "ContentDependant" SG_ 1441 TCCM_AutoSarNMReserved4 1;
BA_ "GenSigStartValue" SG_ 1441 TCCM_AutoSarNMReserved4 255;
BA_ "U_P702_MY2021_Tx" SG_ 1441 TCCM_AutoSarNMReserved4 1;
BA_ "U_U55X_MY2022_Tx" SG_ 1441 TCCM_AutoSarNMReserved4 1;
BA_ "GenSigStartValueInteger" SG_ 1441 TCCM_AutoSarNMReserved3 255;
BA_ "ContentDependant" SG_ 1441 TCCM_AutoSarNMReserved3 1;
BA_ "GenSigStartValue" SG_ 1441 TCCM_AutoSarNMReserved3 255;
BA_ "U_P702_MY2021_Tx" SG_ 1441 TCCM_AutoSarNMReserved3 1;
BA_ "U_U55X_MY2022_Tx" SG_ 1441 TCCM_AutoSarNMReserved3 1;
BA_ "GenSigStartValueInteger" SG_ 1441 TCCM_AutoSarNMReserved2 255;
BA_ "ContentDependant" SG_ 1441 TCCM_AutoSarNMReserved2 1;
BA_ "GenSigStartValue" SG_ 1441 TCCM_AutoSarNMReserved2 255;
BA_ "U_P702_MY2021_Tx" SG_ 1441 TCCM_AutoSarNMReserved2 1;
BA_ "U_U55X_MY2022_Tx" SG_ 1441 TCCM_AutoSarNMReserved2 1;
BA_ "GenSigStartValueInteger" SG_ 1441 TCCM_AutoSarNMReserved1 255;
BA_ "ContentDependant" SG_ 1441 TCCM_AutoSarNMReserved1 1;
BA_ "GenSigStartValue" SG_ 1441 TCCM_AutoSarNMReserved1 255;
BA_ "U_P702_MY2021_Tx" SG_ 1441 TCCM_AutoSarNMReserved1 1;
BA_ "U_U55X_MY2022_Tx" SG_ 1441 TCCM_AutoSarNMReserved1 1;
BA_ "GenSigStartValueInteger" SG_ 1441 TCCM_AutoSarNMNodeId 161;
BA_ "ContentDependant" SG_ 1441 TCCM_AutoSarNMNodeId 1;
BA_ "GenSigStartValue" SG_ 1441 TCCM_AutoSarNMNodeId 161;
BA_ "U_P702_MY2021_Tx" SG_ 1441 TCCM_AutoSarNMNodeId 1;
BA_ "U_U55X_MY2022_Tx" SG_ 1441 TCCM_AutoSarNMNodeId 1;
BA_ "ContentDependant" SG_ 1441 TCCM_AutoSarNMControl 1;
BA_ "U_P702_MY2021_Tx" SG_ 1441 TCCM_AutoSarNMControl 1;
BA_ "U_U55X_MY2022_Tx" SG_ 1441 TCCM_AutoSarNMControl 1;
BA_ "U_T6_MCA_MY2020_Tx" SG_ 1186 FrontDiffLckMsg_D_Rq 1;
BA_ "GenSigStartValueInteger" SG_ 1186 SelDrvMdeAwd2_D_Stat 31;
BA_ "GenSigStartValue" SG_ 1186 SelDrvMdeAwd2_D_Stat 31;
BA_ "U_CX727_MY2021_Rx" SG_ 1186 SelDrvMdeAwd2_D_Stat 1;
BA_ "U_P702_MY2021_Rx" SG_ 1186 SelDrvMdeAwd2_D_Stat 1;
BA_ "U_T6_MCA_MY2020_Rx" SG_ 1186 SelDrvMdeAwd2_D_Stat 1;
BA_ "U_U55X_MY2022_Rx" SG_ 1186 SelDrvMdeAwd2_D_Stat 1;
BA_ "U_P702_MY2021_Tx" SG_ 1186 SelDrvMdeAwd2_D_Stat 1;
BA_ "U_T6_MCA_MY2020_Tx" SG_ 1186 SelDrvMdeAwd2_D_Stat 1;
BA_ "U_U55X_MY2022_Tx" SG_ 1186 SelDrvMdeAwd2_D_Stat 1;
BA_ "U_P702_MY2021_Tx" SG_ 1186 RearDiffLckMsg_D_Rq 1;
BA_ "U_T6_MCA_MY2020_Tx" SG_ 1186 RearDiffLckMsg_D_Rq 1;
BA_ "U_P702_MY2021_Rx" SG_ 1186 RearDiffLck_Tq_Actl 1;
BA_ "U_T6_MCA_MY2020_Rx" SG_ 1186 RearDiffLck_Tq_Actl 1;
BA_ "U_U55X_MY2022_Rx" SG_ 1186 RearDiffLck_Tq_Actl 1;
BA_ "U_CDX706_MY2023_Rx" SG_ 1186 RearDiffLck_Tq_Actl 1;
BA_ "U_P702_MY2021_Tx" SG_ 1186 RearDiffLck_Tq_Actl 1;
BA_ "U_T6_MCA_MY2020_Tx" SG_ 1186 RearDiffLck_Tq_Actl 1;
BA_ "U_P702_MY2021_Rx" SG_ 1186 RearDiffFalt_D_Stat 1;
BA_ "U_T6_MCA_MY2020_Rx" SG_ 1186 RearDiffFalt_D_Stat 1;
BA_ "U_U55X_MY2022_Rx" SG_ 1186 RearDiffFalt_D_Stat 1;
BA_ "U_P702_MY2021_Tx" SG_ 1186 RearDiffFalt_D_Stat 1;
BA_ "U_T6_MCA_MY2020_Tx" SG_ 1186 RearDiffFalt_D_Stat 1;
BA_ "U_P702_MY2021_Tx" SG_ 1186 LsdSrvcRqd_B_Rq 1;
BA_ "U_T6_MCA_MY2020_Tx" SG_ 1186 LsdSrvcRqd_B_Rq 1;
BA_ "U_T6_MCA_MY2020_Tx" SG_ 1186 AwdStat2_D_RqDsply 1;
BA_ "U_T6_MCA_MY2020_Rx" SG_ 1186 FrontDiffFalt_D_Stat 1;
BA_ "U_T6_MCA_MY2020_Tx" SG_ 1186 FrontDiffFalt_D_Stat 1;
BA_ "GenSigStartValue" SG_ 1186 FrontDiffLck_Tq_Actl 16382;
BA_ "U_T6_MCA_MY2020_Rx" SG_ 1186 FrontDiffLck_Tq_Actl 1;
BA_ "U_T6_MCA_MY2020_Tx" SG_ 1186 FrontDiffLck_Tq_Actl 1;
BA_ "U_T6_MCA_MY2020_Rx" SG_ 1186 FrontDiffLckLamp_D_Rq 1;
BA_ "ECGUsedRxSignal" SG_ 1186 FrontDiffLckLamp_D_Rq 1;
BA_ "U_CD542_MY2021_Rx" SG_ 1186 FrontDiffLckLamp_D_Rq 1;
BA_ "U_CD764_MY2022_Rx" SG_ 1186 FrontDiffLckLamp_D_Rq 1;
BA_ "U_CDX706_MY2023_Rx" SG_ 1186 FrontDiffLckLamp_D_Rq 1;
BA_ "U_T6_MCA_MY2020_Tx" SG_ 1186 FrontDiffLckLamp_D_Rq 1;
BA_ "U_P702_MY2021_Rx" SG_ 1186 RearDiffLckLamp_D_Rq 1;
BA_ "U_T6_MCA_MY2020_Rx" SG_ 1186 RearDiffLckLamp_D_Rq 1;
BA_ "U_U55X_MY2022_Rx" SG_ 1186 RearDiffLckLamp_D_Rq 1;
BA_ "U_P702_MY2021_Tx" SG_ 1186 RearDiffLckLamp_D_Rq 1;
BA_ "U_T6_MCA_MY2020_Tx" SG_ 1186 RearDiffLckLamp_D_Rq 1;
VAL_ 963 Illuminated_Entry_Stat 3 "Invalid" 2 "Unknown" 1 "On" 0 "Off" ;
VAL_ 963 Dr_Courtesy_Light_Stat 3 "Invalid" 2 "Unknown" 1 "On" 0 "Off" ;
VAL_ 963 Courtesy_Delay_Status 3 "Invalid" 2 "Unknown" 1 "On" 0 "Off" ;
VAL_ 963 ImpactEvntFdbck_D_Stat 3 "NotUsed" 2 "EventComplete" 1 "EventInProgress" 0 "Normal" ;
VAL_ 963 WrlssAcsyChrgInhbt_B_Rq 1 "Yes" 0 "No" ;
VAL_ 963 PudLampPsngr_D_Rq 3 "Ramp_Down" 2 "Ramp_Up" 1 "On" 0 "Off" ;
VAL_ 963 HeadLampLoOut_B_Stat 1 "Out" 0 "Null" ;
VAL_ 963 HeadLghtHiFdbck_D_Stat 3 "NotUsed" 2 "Cancel" 1 "Hold" 0 "Allow_Change" ;
VAL_ 963 PudLampDrv_D_Rq 3 "Ramp_Down" 2 "Ramp_Up" 1 "On" 0 "Off" ;
VAL_ 963 TrnNotInPrkChime_B_Rq 1 "On" 0 "Off" ;
VAL_ 963 PrkLightChime_B_Rq 1 "On" 0 "Off" ;
VAL_ 963 KeyInIgnWarn_B_Cmd 1 "On" 0 "Off" ;
VAL_ 963 HomeSafeLtChime_B_Rq 1 "On" 0 "Off" ;
VAL_ 963 StopLghtOn_B_Stat 1 "On" 0 "Off" ;
VAL_ 963 RvrseLghtOn_B_Stat 1 "On" 0 "Off" ;
VAL_ 963 PrkLght_D_Stat 3 "Park_Both" 2 "Park_Right" 1 "Park_Left" 0 "Off" ;
VAL_ 963 HeadLghtSwtch_D_Stat 3 "Autolamp" 2 "Headlamp" 1 "Parklamp" 0 "Off" ;
VAL_ 963 HeadLampLoFrOn_B_Stat 1 "Low" 0 "Not_Low" ;
VAL_ 963 HeadLampLoFlOn_B_Stat 1 "Low" 0 "Not_Low" ;
VAL_ 963 HeadLampLoActv_B_Stat 1 "On" 0 "Off" ;
VAL_ 963 Headlamp_On_Wrning_Cmd 1 "On" 0 "Off" ;
VAL_ 963 Park_Brake_Chime_Rqst 1 "On" 0 "Off" ;
VAL_ 963 HeadLghtHiOn_B_Stat 1 "On" 0 "Off" ;
VAL_ 963 BrkWarnInd_B_Rq 1 "On" 0 "Off" ;
VAL_ 963 Brk_Fluid_Lvl_Low 3 "Invalid" 2 "Unknown" 1 "Low" 0 "OK" ;
VAL_ 963 ReducedGuard_D_Stat 3 "NotUsed" 2 "Alarm_On" 1 "Alarm_Off_Previously_On" 0 "Alarm_Off" ;
VAL_ 963 Perimeter_Alarm_Status 3 "Activated" 2 "Armed" 1 "Prearmed" 0 "Disarmed" ;
VAL_ 963 Courtesy_BSave_Stat 3 "Invalid" 2 "Unknown" 1 "No_Effect" 0 "Off" ;
VAL_ 963 DrTgateLck_D_Stat 3 "NotUsed" 2 "Unlock" 1 "Lock" 0 "Null" ;
VAL_ 963 WndwGlbl_D_Cmd 7 "NotUsed3" 6 "NotUsed2" 5 "NotUsed1" 4 "GLEARN" 3 "GCLOSE" 2 "GOPEN" 1 "GSTOP" 0 "Null" ;
VAL_ 963 PudLamp_D_Rq 3 "RAMP_DOWN" 2 "RAMP_UP" 1 "ON" 0 "OFF" ;
VAL_ 963 PerimeterAlarmChimeRq 1 "On" 0 "Off" ;
VAL_ 963 DayRnngLampOn_B_Stat 1 "On" 0 "Off" ;
VAL_ 145 VehYawWActl_D_Qf 3 "OK" 2 "Not_Within_Specifications" 1 "No_Data_Exists" 0 "Faulty" ;
VAL_ 145 VehRolWActl_D_Qf 3 "OK" 2 "Not_Within_Specifications" 1 "No_Data_Exists" 0 "Faulty" ;
VAL_ 145 VehYaw_W_Actl 65535 "Faulty" 65534 "NoDataExists" ;
VAL_ 145 VehRol_W_Actl 65535 "Faulty" 65534 "NoDataExists" ;
VAL_ 76 RstrnPsngrOn_D_Stat 15 "Faulty" 14 "NotUsed_11" 13 "NotUsed_10" 12 "ConfiguredOff" 11 "NotUsed_9" 10 "On" 9 "NotUsed_8" 8 "NotUsed_7" 7 "NotUsed_6" 6 "NotUsed_5" 5 "Off" 4 "NotUsed_4" 3 "NotUsed_3" 2 "NotUsed_2" 1 "NotUsed_1" 0 "NoAction" ;
VAL_ 76 PsngrFmidDetct_D_Actl 3 "Unknown" 2 "Empty" 1 "Occupied" 0 "Fault" ;
VAL_ 76 FirstRowBuckleMid 3 "Unknown" 2 "Unbelted" 1 "Belted" 0 "Faulty" ;
VAL_ 76 ThirdRowBucklePsngr 3 "Unknown" 2 "Unbelted" 1 "Belted" 0 "Faulty" ;
VAL_ 76 ThirdRowBuckleMid 3 "Unknown" 2 "Unbelted" 1 "Belted" 0 "Faulty" ;
VAL_ 76 ThirdRowBuckleDriver 3 "Unknown" 2 "Unbelted" 1 "Belted" 0 "Faulty" ;
VAL_ 76 SecondRowBucklePsngr 3 "Unknown" 2 "Unbelted" 1 "Belted" 0 "Faulty" ;
VAL_ 76 SecondRowBuckleMid 3 "Unknown" 2 "Unbelted" 1 "Belted" 0 "Faulty" ;
VAL_ 76 SecondRowBuckleDriver 3 "Unknown" 2 "Unbelted" 1 "Belted" 0 "Faulty" ;
VAL_ 76 FirstRowBuckleDriver 3 "Unknown" 2 "Unbelted" 1 "Belted" 0 "Faulty" ;
VAL_ 76 RILReq 3 "Not_Used" 2 "Plant_Mode" 1 "On" 0 "Off" ;
VAL_ 76 FirstRowBucklePsngr 3 "Unknown" 2 "Unbelted" 1 "Belted" 0 "Faulty" ;
VAL_ 76 RstrnImpactEvntStatus 7 "Invalid" 6 "Not_Used_4" 5 "Threshold_2_Exceeded" 4 "Not_Used_3" 3 "Threshold_1_Exceeded" 2 "Not_Used_2" 1 "Not_Used_1" 0 "Normal" ;
VAL_ 76 PsngrFrntDetct_D_Actl 3 "Unknown" 2 "Empty" 0 "Faulty" 1 "Occupied" ;
VAL_ 76 EDRTriggerEvntSync 1 "Threshold_Exceeded" 0 "Normal" ;
VAL_ 76 PassRstrnInd_Req 3 "ABOnNotIllum_OffNotIllum" 2 "AirbagOnNot_Illum_OffIllum" 1 "AirbagOn_Illum_OffNotIllum" 0 "AirbagOn_Illum_Off_Illum" ;
VAL_ 65 immoControlCmd_T1 0 "IDLE" 1 "MOTIVE_START_RQST" 2 "NONMOTIVE_START_RQST" 3 "RQST_TARGET1_IDBLOCK1" 4 "RQST_TARGET1_IDBLOCK2" 5 "LIMITEDMOTIVE_START_RQST" 6 "ECHO_TARGET1_IDBLOCK2" 7 "SHUTDOWN" ;
VAL_ 1076 AutoRgen_D_Rq 3 "NotUsed" 2 "AutExhFilterCleanOFF" 1 "AutExhFilterCleanON" 0 "No_Mode_Selected" ;
VAL_ 1076 W2S_LAMP_OK 1 "Yes" 0 "No" ;
VAL_ 1076 OdoTripRx_B_Actl 1 "Yes" 0 "No" ;
VAL_ 1076 DrvSlipCtlMde_B_RqMyKey 1 "On" 0 "Off" ;
VAL_ 1076 FuelLvlWarn_D_Actl 3 "NotUsed" 2 "VeryLow" 1 "Low" 0 "OK" ;
VAL_ 1076 DieslFuelBio_B_ActlDrv 1 "Biodiesel_User" 0 "Non_Biodiesel_User" ;
VAL_ 1076 FuelSecndActv_B_Actl 1 "Yes" 0 "No" ;
VAL_ 1076 HILL_DESC_SW 1 "On" 0 "Off" ;
VAL_ 1076 FUEL_SENSOR_NUM 1 "Dual_Sensors" 0 "Single_Sensor" ;
VAL_ 1076 TirePReset_B_Rq 1 "Reset" 0 "Null" ;
VAL_ 836 Foh_D_Stat 7 "Unused3" 6 "Unused2" 5 "Unused1" 4 "Stopping" 3 "Running" 2 "Starting" 1 "Prestart" 0 "Off" ;
VAL_ 836 EngClnt_Te_ActlFoh 255 "Fault" ;
VAL_ 836 FohFalt_D_Stat 15 "NotUsed4" 14 "NotUsed3" 13 "NotUsed2" 12 "NotUsed1" 11 "FuelTypeDoesNotMatchFOH" 10 "Lifecycle_ModeNotSet" 9 "AuxElectricCoolantPumpInop" 8 "TimeDelayAvoidExcessCycl" 7 "Fuel_Level_OutofRange" 6 "External_Fault" 5 "Internal_Fault" 4 "Voltage_limitation" 3 "Impact_Event" 2 "CoolantTemp_OutofRange" 1 "AmbientTemp_OutofRange" 0 "No_Disable" ;
VAL_ 836 FohEnbl_B_RqDrv 1 "On" 0 "Off" ;
VAL_ 836 FohRqRun_B_Rq 1 "SubmitRequest_toRun" 0 "DoesNotSubmitRequest_toRun" ;
VAL_ 836 HvacPrecondMode_D_Rq 15 "NotUsed4" 14 "NotUsed3" 13 "NotUsed2" 12 "Low_Blower_Auto" 11 "Last_User_Settings" 10 "Auto" 9 "Max_Defrost" 8 "Windshield_Panel_Floor" 7 "Windshield_Panel" 6 "Windshield" 5 "Windshield_Floor" 4 "Floor" 3 "Panel_Floor" 2 "Panel" 1 "MAX_AC" 0 "Off" ;
VAL_ 836 HvacPrecondBlwr_D_Rq 15 "NotUsed6" 14 "NotUsed5" 13 "NotUsed4" 12 "NotUsed3" 11 "NotUsed2" 10 "NotUsed1" 9 "Last_User_Setting" 8 "Auto" 7 "Speed7" 6 "Speed6" 5 "Speed5" 4 "Speed4" 3 "Speed3" 2 "Speed2" 1 "Speed1" 0 "Off" ;
VAL_ 862 EcoMde_D_RqDrv 3 "Faulty" 2 "On" 1 "Off" 0 "Null" ;
VAL_ 862 TwHlGrdAsst_B_RqTrn 1 "On" 0 "Off" ;
VAL_ 862 ApaSwtch_D_RqDrv 3 "NotUsed2" 2 "NotUsed1" 1 "Pressed" 0 "Not_Pressed" ;
VAL_ 862 HvacBlwrFront_D_Stat 31 "Not_Used" 20 "Full_On" 19 "95_Percent" 18 "90_Percent" 17 "85_Percent" 16 "80_Percent" 15 "75_Percent" 14 "70_Percent" 13 "65_Percent" 12 "60_Percent" 11 "55_Percent" 10 "50_Percent" 9 "45_Percent" 8 "40_Percent" 7 "35_Percent" 6 "30_Percent" 5 "25_Percent" 4 "20_Percent" 3 "15_Percent" 2 "10_Percent" 1 "5_Percent" 0 "Off" ;
VAL_ 862 HvacBlwrRear_D_Stat 31 "Not_Used" 20 "Full_On" 19 "95_Percent" 18 "90_Percent" 17 "85_Percent" 16 "80_Percent" 15 "75_Percent" 14 "70_Percent" 13 "65_Percent" 12 "60_Percent" 11 "55_Percent" 10 "50_Percent" 9 "45_Percent" 8 "40_Percent" 7 "35_Percent" 6 "30_Percent" 5 "25_Percent" 4 "20_Percent" 3 "15_Percent" 2 "10_Percent" 1 "5_Percent" 0 "Off" ;
VAL_ 862 CabnAmb_Te_Actl 255 "Fault" ;
VAL_ 862 ClimtThrmlLoad_No_Actl 255 "Fault" ;
VAL_ 862 CamraDefog_B_Actl 1 "On" 0 "Off" ;
VAL_ 862 AutoStpHvacDelta_I_Est 255 "Fault" ;
VAL_ 931 VehOnSrc_D_Stat 15 "NotUsed_11" 14 "NotUsed_10" 13 "NotUsed_9" 12 "NotUsed_8" 11 "NotUsed_7" 10 "NotUsed_6" 9 "EsclRssd" 8 "AutonomousVehicle" 7 "SecureIdle" 6 "FleetVehicleInhibit" 5 "StolenVehicleInhibit" 4 "OverTheAir" 3 "RemoteParkAssist" 2 "RemoteStart" 1 "Manual" 0 "Off" ;
VAL_ 931 EngStrtActv_B_Stat 1 "Active" 0 "Inactive" ;
VAL_ 931 EngStrt_B_Rq 1 "Request" 0 "NoRequest" ;
VAL_ 931 DrvInCtl_B_Stat 1 "Yes" 0 "No" ;
VAL_ 931 PtWakeReas_D_Stat 15 "NotUsed_9" 14 "NotUsed_8" 13 "NotUsed_7" 12 "NotUsed_6" 11 "NotUsed_5" 10 "NotUsed_4" 9 "NotUsed_3" 8 "NotUsed_2" 7 "NotUsed_1" 6 "ElapsedTime" 5 "ThirdPartyWakeup" 4 "DoorAjar" 3 "EarlyWake" 2 "NonMotiveStart" 1 "MotiveStart" 0 "Null" ;
VAL_ 931 CrnkInhbt_B_Stat 1 "Inhibit" 0 "NoInhibit" ;
VAL_ 931 IgnPreOffActv_B_Stat 1 "Active" 0 "Inactive" ;
VAL_ 578 PtLatchActv_B_RqBcm 1 "On" 0 "Off" ;
VAL_ 578 immoSecureIdleMode 3 "NotUsed2" 2 "NotUsed1" 1 "Active" 0 "Inactive" ;
VAL_ 578 ReFuelSwtchStat_D_Actl 3 "NotUsed2" 2 "NotUsed1" 1 "On" 0 "Off" ;
VAL_ 578 FuelPumpPwr_D_Stat 7 "NotUsed3" 6 "NotUsed2" 5 "NotUsed1" 4 "Power_Off_Default" 3 "Power_Off_Command" 2 "Power_Off_Service" 1 "Power_Off_Impact" 0 "Power_On" ;
VAL_ 578 BattULo_U_Actl 255 "Fault" ;
VAL_ 578 PrkLckCtl_B_Enbl 1 "Enable" 0 "Disable" ;
VAL_ 578 PrkLckCtlMsgTxt_D_Rq 3 "BTSI_DI_3" 2 "BTSI_DI_2" 1 "BTSI_DI_1" 0 "Null_BTSI_DI" ;
VAL_ 578 BrkTrnShifLck_B_Stat 1 "Shift" 0 "NoShift" ;
VAL_ 578 PrkLckCtlUnlck_D_Stat 3 "Trans_And_Steer_Unlckd" 2 "Steering_Unlckd" 1 "Transmission_Unlckd" 0 "Null" ;
VAL_ 578 PrkLckCtlTow_B_Enbl 1 "Enable" 0 "Disable" ;
VAL_ 578 DriverCrankingReq 1 "Crank_Request" 0 "No_Crank_Request" ;
VAL_ 578 EngOff_T_Actl 65535 "Invalid" ;
VAL_ 578 DcacElPw_D_Rq 3 "NotUsed" 2 "AC_HighPower_Requested" 1 "AC_LowPower_Requested" 0 "AC_Power_NotRequested" ;
VAL_ 578 BattULo_I_Actl 16383 "Fault" ;
VAL_ 947 ValetMode_D_Mem 1 "On" 0 "Off" ;
VAL_ 947 DrStatDrvErrCnt_B_Stat 1 "Yes" 0 "No" ;
VAL_ 947 TurnLghtRight_D_Rq 3 "Seq" 2 "On" 1 "Off" 0 "Null" ;
VAL_ 947 TurnLghtRightOn_B_Stat 1 "On" 0 "Off" ;
VAL_ 947 TurnLghtLeftOn_B_Stat 1 "On" 0 "Off" ;
VAL_ 947 FogLghtRearOn_B_Stat 1 "On" 0 "Off" ;
VAL_ 947 Backlit_LED_Status 15 "Unused3" 14 "Unused2" 13 "Unused1" 12 "Night_12" 11 "Night_11" 10 "Night_10" 9 "Night_9" 8 "Night_8" 7 "Night_7" 6 "Night_6" 5 "Night_5" 4 "Night_4" 3 "Night_3" 2 "Night_2" 1 "Night_1" 0 "Off" ;
VAL_ 947 TurnLghtLeft_D_Rq 3 "Seq" 2 "On" 1 "Off" 0 "Null" ;
VAL_ 947 FogLghtFrontOn_B_Stat 1 "On" 0 "Off" ;
VAL_ 947 IgnKeyType_D_Actl 15 "Invalid" 14 "Unknown" 3 "Key_Not_Prgrm_Read_Failure" 2 "Key_In_Ign_My_Key" 1 "Key_In_Ign_Standard_Key" 0 "Key_Read_In_Progress" ;
VAL_ 947 Parklamp_Status 3 "Invalid" 2 "Unknown" 1 "On" 0 "Off" ;
VAL_ 947 Litval 255 "Invalid" 254 "Unknown" 5 "Day" 4 "Twilight_4" 3 "Twilight_3" 2 "Twilight_2" 1 "Twilight_1" 0 "Night" ;
VAL_ 947 Key_In_Ignition_Stat 1 "In" 0 "Out" ;
VAL_ 947 Ignition_Status 0 "Unknown" 1 "Off" 15 "Invalid" 8 "Start" 4 "Run" 2 "Accessory" ;
VAL_ 947 Dimming_Lvl 255 "Invalid" 254 "Unknown" 18 "Day_6" 17 "Day_5" 16 "Day_4" 15 "Day_3" 14 "Day_2" 13 "Day_1" 12 "Night_12" 11 "Night_11" 10 "Night_10" 9 "Night_9" 8 "Night_8" 7 "Night_7" 6 "Night_6" 5 "Night_5" 4 "Night_4" 3 "Night_3" 2 "Night_2" 1 "Night_1" 0 "Off" ;
VAL_ 947 Day_Night_Status 3 "NotUsed" 2 "Night" 1 "Day" 0 "Null" ;
VAL_ 947 Remote_Start_Status 3 "Invalid" 2 "Unknown" 1 "Remote" 0 "Null" ;
VAL_ 947 DrStatTgate_B_Actl 1 "Ajar" 0 "Closed" ;
VAL_ 947 DrStatRr_B_Actl 1 "Ajar" 0 "Closed" ;
VAL_ 947 DrStatRl_B_Actl 1 "Ajar" 0 "Closed" ;
VAL_ 947 DrStatPsngr_B_Actl 1 "Ajar" 0 "Closed" ;
VAL_ 947 DrStatInnrTgate_B_Actl 1 "Ajar" 0 "Closed" ;
VAL_ 947 DrStatHood_B_Actl 1 "Ajar" 0 "Closed" ;
VAL_ 947 DrStatDrv_B_Actl 1 "Ajar" 0 "Closed" ;
VAL_ 947 PrkBrkActv_B_Actl 1 "Active" 0 "Inactive" ;
VAL_ 947 LifeCycMde_D_Actl 3 "Transport" 2 "NotUsed" 1 "Factory" 0 "Normal" ;
VAL_ 947 Delay_Accy 1 "On" 0 "Off" ;
VAL_ 947 CrashEvnt_D_Stat 3 "Invalid" 2 "Fuel_Cutoff_Event" 1 "Deploy_Event" 0 "No_Event" ;
VAL_ 947 FuelPmpInhbt_B_Stat 1 "Inhibit" 0 "No_Inibit" ;
VAL_ 947 BodySrvcRqd_B_Rq 1 "Yes" 0 "No" ;
VAL_ 1084 BattULoState_D_Qlty 3 "OK" 2 "Not_Within_Specifications" 1 "Eval_In_Progress" 0 "Fault" ;
VAL_ 1084 BSFault 1 "Fault" 0 "No_Fault" ;
VAL_ 1084 BattULo2_Te_Actl 127 "Fault" ;
VAL_ 1068 EngStrtInhbt_B_RqBatt 1 "Start_Inhibit" 0 "Dont_Care" ;
VAL_ 1068 BattULoChrg_D_Rq 3 "Low_Battery_Temperature" 2 "Charging_Requested" 1 "Chrg_Requested_HighCurrent" 0 "No_Request" ;
VAL_ 1068 PwSysULoFalt_D_Stat 15 "Not_Used_6" 14 "LowBatterySOC" 13 "PSS_Shed2_Contin" 12 "Not_Used_4" 11 "Not_Used_3" 10 "Not_Used_2" 9 "BattMonitoringSensorFault" 8 "LowBattVoltDuringPwSrcOn" 7 "LowBatt2_PowerSaveMode" 6 "LowBatt1_Warning" 5 "Overvoltage" 4 "Fault_NoOutput" 3 "Fault_ReducedOutput" 2 "Fault_Nonspecific" 1 "Cluster_Proveout" 0 "No_Fault" ;
VAL_ 1068 Shed_T_Eng_Off_B 1 "Active" 0 "Inactive" ;
VAL_ 1068 Shed_Feature_Group_ID 16 "PtcHeater" 30 "NotUsed_7" 29 "NotUsed_6" 28 "NotUsed_5" 27 "NotUsed_4" 26 "NotUsed_3" 25 "NotUsed_2" 24 "NotUsed_1" 23 "Dcac" 22 "UpFitter_6" 21 "UpFitter_5" 20 "UpFitter_4" 19 "UpFitter_3" 18 "UpFitter_2" 17 "UpFitter_1" 14 "HtdMirr" 13 "HvacRearBlwr_Third" 12 "HvacRearBlwr_Second" 11 "HvacRearBlwr_First" 31 "All LSHED1 Features" 10 "Htd_Windscrn" 9 "SpltHtdBcklight_HtdMirr" 8 "HtdBcklight_HtdMirr" 7 "HtdCoolSeat_FrtDriver" 6 "HtdCoolSeat_FrtPass" 5 "HtdCoolSeat_RearPass" 4 "HtdCoolSeat_RearDriver" 3 "SmartTrlrTowBattCharge" 2 "Htd_StrWhl" 1 "Htd_Washer_Fluid" 0 "No_LSHED1_Features" 15 "Engine_Coolant_Fan" ;
VAL_ 1068 Shed_Drain_Eng_Off_B 1 "Active" 0 "Inactive" ;
VAL_ 1068 Shed_Level_Req 7 "SHED3" 6 "Loads_On" 5 "SHED_ENG_OFF" 4 "SOON_ENG_OFF" 3 "SHED2_CONTIN" 2 "SHED2_TRANS" 1 "SHED1" 0 "NO_SHED" ;
VAL_ 1068 ULoRgenTestMde_B_Rq 1 "Request" 0 "NoRequest" ;
VAL_ 1068 ChargeMode 7 "Undefined_2" 6 "Undefined_1" 5 "Battery_Identify" 4 "Battery_Refresh" 3 "SlowRegenAllowNoDischarge" 2 "Fast_Regen_Allowed" 1 "Slow_Regen_Allowed" 0 "Conventional_Charging" ;
VAL_ 1068 IdleSpeedIncrease_El 1 "Yes" 0 "No" ;
VAL_ 1068 Batt_Lo_SoC_B 1 "Active" 0 "Inactive" ;
VAL_ 1068 PeriodicElLoad_B_Stat 1 "Active" 0 "Inactive" ;
VAL_ 1068 Batt_Crit_SoC_B 1 "Active" 0 "Inactive" ;
VAL_ 146 VehVert2_A_Actl 8191 "Faulty" 8190 "NoDataExists" ;
VAL_ 146 VehLong2_A_Actl 8191 "Faulty" 8190 "NoDataExists" ;
VAL_ 146 VehLat2_A_Actl 8191 "Faulty" 8190 "NoDataExists" ;
VAL_ 146 VehVertAActl_D_Qf 3 "OK" 2 "Not_Within_Specifications" 1 "No_Data_Exists" 0 "Faulty" ;
VAL_ 146 VehLongAActl_D_Qf 3 "OK" 2 "Not_Within_Specifications" 1 "No_Data_Exists" 0 "Faulty" ;
VAL_ 146 VehLatAActl_D_Qf 3 "OK" 2 "Not_Within_Specifications" 1 "No_Data_Exists" 0 "Faulty" ;
VAL_ 1010 MbdblActv_B_RqAdas 1 "Yes" 0 "No" ;
VAL_ 1010 CbdblActv_B_RqAdas 1 "Yes" 0 "No" ;
VAL_ 1010 AdbUrbanArea_B_Stat 1 "Yes" 0 "No" ;
VAL_ 997 PersIndexCcm_D_Actl 7 "Unused_3" 6 "Unused_2" 5 "Unused_1" 4 "Vehicle" 3 "PERS_4" 2 "PERS_3" 1 "PERS_2" 0 "PERS_1" ;
VAL_ 997 PersTurnSglView_D_Stat 3 "NotConfigured" 2 "Enabled" 1 "Disabled" 0 "Null" ;
VAL_ 985 LongCtrlBrk_D_Rq 3 "NotUsed" 2 "LowDecel" 1 "HighDecel" 0 "NoRequest" ;
VAL_ 985 AdbDrvSide_B_Stat 1 "Left_Hand_Traffic" 0 "Right_Hand_Traffic" ;
VAL_ 985 LcwaMsgTxt_D_Stat 3 "SodXFaulty" 2 "SodXBlocked" 1 "TrailerConnected" 0 "NoMessage" ;
VAL_ 985 AdbDividedRoad_B_Stat 1 "Yes" 0 "No" ;
VAL_ 985 IsaVLimUnit_D_Rq 3 "NoDataExists" 2 "Mph" 1 "Kph" 0 "Null" ;
VAL_ 985 SblmYieldScnr_B_Stat 1 "Yes" 0 "No" ;
VAL_ 985 SblmStopScnr_B_Stat 1 "Yes" 0 "No" ;
VAL_ 985 IsaVLim_D_Rq 252 "NotUsed_2" 250 "LimitSpeed_250" 240 "LimitSpeed_240" 230 "LimitSpeed_230" 220 "LimitSpeed_220" 210 "LimitSpeed_210" 200 "LimitSpeed_200" 190 "LimitSpeed_190" 150 "LimitSpeed_150" 140 "LimitSpeed_140" 130 "LimitSpeed_130" 120 "LimitSpeed_120" 110 "LimitSpeed_110" 100 "LimitSpeed_100" 90 "LimitSpeed_90" 80 "LimitSpeed_80" 70 "LimitSpeed_70" 60 "LimitSpeed_60" 50 "LimitSpeed_50" 40 "LimitSpeed_40" 30 "LimitSpeed_30" 20 "LimtSpeed_20" 251 "NotUsed_1" 255 "Faulty" 254 "NoDataExists" 253 "NotUsed_3" 180 "LimitSpeed_180" 179 "LimitSpeed_179" 178 "LimitSpeed_178" 177 "LimitSpeed_177" 176 "LimitSpeed_176" 175 "LimitSpeed_175" 174 "LimitSpeed_174" 173 "LimitSpeed_173" 172 "LimitSpeed_172" 171 "LimitSpeed_171" 170 "LimitSpeed_170" 169 "LimitSpeed_169" 168 "LimitSpeed_168" 167 "LimitSpeed_167" 166 "LimitSpeed_166" 165 "LimitSpeed_165" 164 "LimitSpeed_164" 163 "LimitSpeed_163" 162 "LimitSpeed_162" 161 "LimitSpeed_161" 160 "LimitSpeed_160" 15 "LimitSpeed_15" 14 "LimitSpeed_14" 13 "LimitSpeed_13" 12 "LimitSpeed_12" 11 "LimitSpeed_11" 10 "LimitSpeed_10" 9 "LimitSpeed_9" 8 "LimitSpeed_8" 7 "LimitSpeed_7" 6 "LimitSpeed_6" 5 "LimitSpeed_5" 4 "LimitSpeed_4" 3 "LimitSpeed_3" 2 "LimitSpeed_2" 1 "LimitSpeed_1" 0 "LimitSpeed_0" ;
VAL_ 985 IaccVLimUnit_D_Rq 3 "NoDataExists" 2 "Mph" 1 "Kph" 0 "Null" ;
VAL_ 985 IaccVLim_D_Rq 252 "NotUsed_2" 250 "LimitSpeed_250" 240 "LimitSpeed_240" 230 "LimitSpeed_230" 220 "LimitSpeed_220" 210 "LimitSpeed_210" 200 "LimitSpeed_200" 190 "LimitSpeed_190" 150 "LimitSpeed_150" 140 "LimitSpeed_140" 130 "LimitSpeed_130" 120 "LimitSpeed_120" 110 "LimitSpeed_110" 100 "LimitSpeed_100" 90 "LimitSpeed_90" 80 "LimitSpeed_80" 70 "LimitSpeed_70" 60 "LimitSpeed_60" 50 "LimitSpeed_50" 40 "LimitSpeed_40" 30 "LimitSpeed_30" 20 "LimtSpeed_20" 251 "NotUsed_1" 255 "Faulty" 254 "NoDataExists" 253 "NotUsed_3" 180 "LimitSpeed_180" 179 "LimitSpeed_179" 178 "LimitSpeed_178" 177 "LimitSpeed_177" 176 "LimitSpeed_176" 175 "LimitSpeed_175" 174 "LimitSpeed_174" 173 "LimitSpeed_173" 172 "LimitSpeed_172" 171 "LimitSpeed_171" 170 "LimitSpeed_170" 169 "LimitSpeed_169" 168 "LimitSpeed_168" 167 "LimitSpeed_167" 166 "LimitSpeed_166" 165 "LimitSpeed_165" 164 "LimitSpeed_164" 163 "LimitSpeed_163" 162 "LimitSpeed_162" 161 "LimitSpeed_161" 160 "LimitSpeed_160" 15 "LimitSpeed_15" 14 "LimitSpeed_14" 13 "LimitSpeed_13" 12 "LimitSpeed_12" 11 "LimitSpeed_11" 10 "LimitSpeed_10" 9 "LimitSpeed_9" 8 "LimitSpeed_8" 7 "LimitSpeed_7" 6 "LimitSpeed_6" 5 "LimitSpeed_5" 4 "LimitSpeed_4" 3 "LimitSpeed_3" 2 "LimitSpeed_2" 1 "LimitSpeed_1" 0 "LimitSpeed_0" ;
VAL_ 985 DasAlrtInfo_D_Dsply 3 "NotUsed" 2 "On" 1 "Off" 0 "Null" ;
VAL_ 985 SblmRndAbtScnr_B_Stat 1 "Yes" 0 "No" ;
VAL_ 985 PwSustnAdas_B_Rq 1 "Active" 0 "Inactive" ;
VAL_ 985 ClrExitAsstMsgTxt_D_Rq 15 "NotUsed_8" 14 "NotUsed_7" 13 "NotUsed_6" 12 "NotUsed_5" 11 "NotUsed_4" 10 "NotUsed_3" 9 "NotUsed_2" 8 "NotUsed_1" 7 "SystemFault" 6 "ChildLockMaintained" 5 "WarningRight" 4 "WarningLeft" 3 "InformationRight" 2 "InformationLeft" 1 "Shutdown" 0 "NoMessage" ;
VAL_ 985 ClrExitAsstChime_D_Rq 7 "NotUsed_4" 6 "NotUsed_3" 5 "NotUsed_2" 4 "NotUsed_1" 3 "WarningChimeFront" 2 "WarningChimeRear" 1 "InformationChime" 0 "Off" ;
VAL_ 985 LongCtrlEnbl_D_Rq 7 "Faulty" 6 "NotUsed_3" 5 "NotUsed_2" 4 "NotUsed_1" 3 "RemoteParking" 2 "Autohitch" 1 "AutomaticParking" 0 "None" ;
VAL_ 985 SblmPedCrossScnr_B_Stat 1 "Yes" 0 "No" ;
VAL_ 985 TsrRegionTxt_D_Stat 31 "Faulty" 30 "NotUsed_8" 29 "NotUsed_7" 28 "NotUsed_6" 27 "NotUsed_5" 26 "NotUsed_4" 25 "NotUsed_3" 24 "NotUsed_2" 23 "NotUsed_1" 22 "Region_22" 21 "Region_21" 20 "Region_20" 19 "Region_19" 18 "Region_18" 17 "Region_17" 16 "Region_16" 15 "Region_15" 14 "Region_14" 13 "Region_13" 12 "Region_12" 11 "Region_11" 10 "Region_10" 9 "Region_09" 8 "Region_08" 7 "Region_07" 6 "Region_06" 5 "Region_05" 4 "Region_04" 3 "Region_03" 2 "Region_02" 1 "Region_01" 0 "NotDetermined" ;
VAL_ 985 LdwChime_B_Rq 1 "On" 0 "Off" ;
VAL_ 985 ClrExitAsst_D_Stat 3 "NotUsed" 2 "Enabled" 1 "Disabled" 0 "Null" ;
VAL_ 984 DasFalt_B_Dsply 1 "On" 0 "Off" ;
VAL_ 984 HzrdWarnLamp_B_Rq 1 "Active" 0 "Inactive" ;
VAL_ 984 DasWarn_D_Dsply 3 "Warning_Level_3" 2 "Warning_Level_2" 1 "Warning_Level_1" 0 "No_Warning" ;
VAL_ 984 DasStats_D_Dsply 3 "Available" 2 "Unavailable_Other" 1 "Feedback_due_to_Speed" 0 "Off" ;
VAL_ 984 DasAlrtLvl_D_Dsply 5 "Alertness_Level_5" 4 "Alertness_Level_4" 3 "Alertness_Level_3" 2 "Alertness_Level_2" 1 "Alertness_Level_1" 0 "Undefined" ;
VAL_ 984 CamraStats_D_Dsply 3 "FrtCam_TempUnavailOther" 2 "FrtCam_TempUnavailVisibile" 1 "Front_Camera_Service_Reqd" 0 "Front_Camera_OK" ;
VAL_ 984 CamraDefog_B_Req 1 "On" 0 "Off" ;
VAL_ 984 LaHandsOff_D_Dsply 3 "Suppressed" 2 "Level2" 1 "Level1" 0 "HandsOn" ;
VAL_ 984 LaDenyStats_B_Dsply 1 "Unavailable" 0 "Available" ;
VAL_ 984 AhbcRampingV_D_Rq 3 "Slow" 2 "Medium" 1 "Fast" 0 "Immediately" ;
VAL_ 984 PersIndexIpma_D_Actl 7 "Unused_3" 6 "Unused_2" 5 "Unused_1" 4 "Vehicle" 3 "PERS_4" 2 "PERS_3" 1 "PERS_2" 0 "PERS_1" ;
VAL_ 984 AhbFeat_D_Stat 3 "ADB" 2 "GFHB" 1 "AHBC" 0 "None" ;
VAL_ 984 DsmcMsgTxt_D_Dsply 3 "Blockage" 2 "DriverNotSeen" 1 "Fault" 0 "NoMessage" ;
VAL_ 984 AhbHiBeam_D_Rq 3 "NotUsed" 2 "HighBeamRecommended" 1 "LowBeamRecommended" 0 "DeactivatedUnavailable" ;
VAL_ 984 LaActvStats_D2_Dsply 31 "Unused7" 30 "LA_Off" 29 "ECE_OFF_RTT" 28 "Unused4" 27 "Unused3" 26 "Unused2" 25 "Unused1" 24 "InerveneLeft_InterveneRght" 23 "WarnLeft_InterveneRight" 22 "SuppressLeft_InterveneRght" 21 "AvailLeft_InterveneRhtt" 20 "NoLeft_InterveneRight" 19 "InterveneLeft_WarnRight" 18 "WarnLeft_WarnRight" 17 "SuppressLeft_WarnRight" 16 "AvailableLeft_WarnRight" 15 "NoLeft_WarnRight" 14 "InterveneLeft_SuppressRght" 13 "WarnLeft_SuppressRight" 12 "SuppressLeft_SuppressRight" 11 "AvailLeft_SuppressRight" 10 "NoLeft_SuppressRight" 9 "InterveneLeft_AvailRight" 8 "WarnLeft_AvailRight" 7 "SuppressLeft_AvailRight" 6 "AvailableLeft_AvailRight" 5 "NoLeft_AvailableRight" 4 "InterveneLeft_NoRight" 3 "WarnLeft_NoRight" 2 "SuppressLeft_NoRight" 1 "AvailableLeft_NoRight" 0 "NoLeft_NoRight" ;
VAL_ 983 CmbbObjRelLong_V_Actl 1023 "Faulty" 1022 "NoDataExists" ;
VAL_ 983 CmbbObjRelLat_V_Actl 511 "Faulty" 510 "NoDataExists" ;
VAL_ 983 CmbbObjDistLong_L_Actl 1023 "Faulty" 1022 "NoDataExists" ;
VAL_ 983 CmbbObjDistLat_L_Actl 511 "Faulty" 510 "NoDataExists" ;
VAL_ 983 CmbbObjConfdnc_D_Stat 3 "High" 2 "Medium" 1 "Low" 0 "NotDetermined" ;
VAL_ 983 CmbbObjColl_T_Actl 127 "Faulty" 126 "NoDataExists" ;
VAL_ 983 CmbbObjClass_D_Stat 15 "NotUsed_9" 14 "NotUsed_8" 13 "NotUsed_7" 12 "NotUsed_6" 11 "NotUsed_5" 10 "NotUsed_4" 9 "NotUsed_3" 8 "NotUsed_2" 7 "NotUsed_1" 6 "Unclassified_Vehicle" 5 "Bicycle" 4 "Pedestrian" 3 "Truck" 2 "Motorcycle" 1 "Vehicle" 0 "Undetermined" ;
VAL_ 983 EsaEnbl_D2_Rq 3 "NotConfigured" 2 "Enabled" 1 "Pending" 0 "Disabled" ;
VAL_ 976 SuspClkSync_No_Actl 255 "Faulty" 254 "NoDataExists" ;
VAL_ 976 SrpSigValid_B_Stat 1 "True" 0 "False" ;
VAL_ 976 SrpHghtRight_L_Actl 511 "Faulty" 510 "NoDataExists" ;
VAL_ 976 SrpHghtLeft_L_Actl 511 "Faulty" 510 "NoDataExists" ;
VAL_ 976 SrpEventRight_D_Stat 3 "Faulty" 2 "Bump" 1 "Pothole" 0 "NoEvent" ;
VAL_ 976 SrpEventLeft_D_Stat 3 "Faulty" 2 "Bump" 1 "Pothole" 0 "NoEvent" ;
VAL_ 976 SrpDistRight_L_Actl 511 "Faulty" 510 "NoDataExists" ;
VAL_ 976 SrpDistLeft_L_Actl 511 "Faulty" 510 "NoDataExists" ;
VAL_ 973 TsrChime_D_Rq 3 "Null" 2 "Overspeed_chime" 1 "SL_change_chime" 0 "NotUsed" ;
VAL_ 973 PersCtaSplitView_D_Stat 3 "EnabledFull" 2 "Enabled_180SwitchOnly" 1 "Disabled" 0 "Null" ;
VAL_ 973 TsrVl2PrmntMsgTxt_D_Rq 3 "NotUsed" 2 "ShowPermanentlyWithSupp" 1 "ShowPermanentlyWithoutSupp" 0 "DoNotShowSignPermanent" ;
VAL_ 973 TsrVl1PrmntMsgTxt_D_Rq 3 "NotUsed" 2 "ShowPermanentlyWithSupp" 1 "ShowPermanentlyWithoutSupp" 0 "DoNotShowSignPermanent" ;
VAL_ 973 TsrVl2RstrcMsgTxt2_D_Rq 7 "NotUsed" 6 "Time" 5 "Trailer" 4 "Snow" 3 "RainWet" 2 "NoRecognizableRestrictn" 1 "NoSpeedLimitRestrictn" 0 "Null" ;
VAL_ 973 TsrVl1RstrcMsgTxt2_D_Rq 7 "NotUsed" 6 "Time" 5 "Trailer" 4 "Snow" 3 "RainWet" 2 "NoRecognizableRestrictn" 1 "NoSpeedLimitRestrictn" 0 "Null" ;
VAL_ 973 TsrOvtkMsgTxt2_D_Rq 15 "NotUsed5" 14 "NotUsed4" 13 "NotUsed3" 12 "NotUsed2" 11 "NotUsed1" 10 "LimForTrucksCancelled" 9 "LimForTrucksWoQlfdRstrc" 8 "LimForTrucksWithoutRstrc" 7 "LimAllCancelled" 6 "LimAllWithRstrcTime" 5 "LimAllWithRstrcTrailer" 4 "LimAllWithRstrcSnow" 3 "LimAllWithRstrcRain" 2 "LimAllWithoutQlfdRstrc" 1 "LimAllWithoutRestriction" 0 "OvertakingAllowed" ;
VAL_ 973 WwaWarn_B_Rq 1 "On" 0 "Off" ;
VAL_ 973 TsrVlUnitMsgTxt_D_Rq 3 "NoDataExists" 2 "Mph" 1 "Kph" 0 "Null" ;
VAL_ 973 TsrVLim2MsgTxt_D_Rq 255 "NoLimit" 254 "NotUsed2" 253 "NotUsed1" 252 "NotToBeDisplayed" 251 "LimitCancelled" 31 "1F_FA_Message31_250" 30 "Message30" 29 "Message29" 28 "Message28" 27 "Message27" 26 "Message26" 25 "Message25" 24 "Message24" 23 "Message23" 22 "Message22" 21 "Message21" 20 "Message20" 19 "Message19" 18 "Message18" 17 "Message17" 16 "Message16" 15 "Message15" 14 "Message14" 13 "Message13" 12 "Message12" 11 "Message11" 10 "Message10" 9 "Message9" 8 "Message8" 7 "Message7" 6 "Message6" 5 "Message5" 4 "Message4" 3 "Message3" 2 "Message2" 1 "Message1" 0 "Null" ;
VAL_ 973 TsrVLim1MsgTxt_D_Rq 255 "NoLimit" 254 "NotUsed2" 253 "NotUsed1" 252 "NotToBeDisplayed" 251 "LimitCancelled" 31 "1F_FA_Message31_250" 30 "Message30" 29 "Message29" 28 "Message28" 27 "Message27" 26 "Message26" 25 "Message25" 24 "Message24" 23 "Message23" 22 "Message22" 21 "Message21" 20 "Message20" 19 "Message19" 18 "Message18" 17 "Message17" 16 "Message16" 15 "Message15" 14 "Message14" 13 "Message13" 12 "Message12" 11 "Message11" 10 "Message10" 9 "Message9" 8 "Message8" 7 "Message7" 6 "Message6" 5 "Message5" 4 "Message4" 3 "Message3" 2 "Message2" 1 "Message1" 0 "Null" ;
VAL_ 973 TsrVl2StatMsgTxt_D_Rq 3 "LimitOutdated" 2 "LimitReiable" 1 "LimitChanged" 0 "Null" ;
VAL_ 973 TsrVl2RstrcMsgTxt_D_Rq 3 "NotUsed" 2 "NoRecognizableRestriction" 1 "NoSpeedLimitRestriction" 0 "Null" ;
VAL_ 973 TsrVl1StatMsgTxt_D_Rq 3 "LimitOutdated" 2 "LimitReiable" 1 "LimitChanged" 0 "Null" ;
VAL_ 973 TsrVl1RstrcMsgTxt_D_Rq 3 "NotUsed" 2 "NoRecognizableRestriction" 1 "NoSpeedLimitRestriction" 0 "Null" ;
VAL_ 973 TsrStatMsgTxt_D_Rq 7 "NotUsed" 6 "NoDataExists" 5 "TSR_Error" 4 "Available_NavigationOnly" 3 "Available_CameraOnly" 2 "Available_FusionMode" 1 "TSR_Off" 0 "Null" ;
VAL_ 973 TsrOvtkStatMsgTxt_D_Rq 3 "LimitOutdated" 2 "LimitReiable" 1 "LimitChanged" 0 "Null" ;
VAL_ 973 TsrOvtkMsgTxt_D_Rq 7 "LimForTrucksCancelled" 6 "LimForTrucksWoQlfdRstrc" 5 "LimForTrucksWithoutRstrc" 4 "LimAllCancelled" 3 "LimAllWithoutQlfdRstrc" 2 "LimAllWithoutRestriction" 1 "OvertakingAllowed" 0 "Null" ;
VAL_ 973 TsrOswWarnMsgTxt_D_Rq 3 "NotUsed" 2 "True" 1 "False" 0 "Null" ;
VAL_ 973 TsrMsgTxt_D_Rq 15 "NotUsed6" 14 "NotUsed5" 13 "NotUsed4" 12 "NotUsed3" 11 "NotUsed2" 10 "NotUsed1" 9 "RecgnzdSignNotUsblForDsply" 8 "LimitedSystemPerformance" 7 "OffRoad" 6 "RegionNotSupported" 5 "CountryNotSupported" 4 "WrngNavDatIncompDatCarrier" 3 "NoNavDataAvailable" 2 "NoNavAvailableSwitchedOff" 1 "NoInformationAllOK" 0 "Null" ;
VAL_ 973 LaSysOffStat_D_Dsply 3 "Level_3" 2 "Level_2" 1 "Level_1" 0 "Level_0" ;
VAL_ 973 RoadSignRgltry_D_Dsply 3 "NoEntry" 2 "Stop" 1 "Yield" 0 "None" ;
VAL_ 970 TurnLght_D_RqTja 3 "NotUsed" 2 "Right" 1 "Left" 0 "Off" ;
VAL_ 970 LkaDrvOvrrd_D_Rq 3 "Level_3" 2 "Level_2" 1 "Level_1" 0 "Level_0" ;
VAL_ 970 LkaActvStats_D2_Req 7 "NotUsed" 6 "LkaIncrIntervRight" 5 "LkaSupprRight" 4 "LkaStandIntervRight" 3 "LkaSupprLeft" 2 "LkaStandIntervLeft" 1 "LkaIncrIntervLeft" 0 "LkaNoInterv" ;
VAL_ 970 LaRefAng_No_Req 4095 "Fault" ;
VAL_ 970 LaRampType_B_Req 1 "Quick" 0 "Smooth" ;
VAL_ 970 LaCurvature_No_Calc 4095 "Fault" ;
VAL_ 970 LdwActvStats_D_Req 7 "LDW_Suppress_Right_Left" 6 "Not_Used2" 5 "LDW_Suppress_Right" 4 "LDW_Warning_Right" 3 "LDW_Suppress_Left" 2 "LDW_Warning_Left" 1 "LDW_DemoVibration" 0 "LDW_Idle" ;
VAL_ 970 LdwActvIntns_D_Req 3 "High" 2 "Medium" 1 "Low" 0 "None" ;
VAL_ 394 AccTrgDist2_D_Dsply 15 "DIST_ACTIVE_13_Farthest" 14 "DIST_ACTIVE_12" 13 "DIST_ACTIVE_11" 12 "DIST_ACTIVE_10" 11 "DIST_ACTIVE_9" 10 "DIST_ACTIVE_8" 9 "DIST_ACTIVE_7" 8 "DIST_ACTIVE_6" 7 "DIST_ACTIVE_5" 6 "DIST_ACTIVE_4" 5 "DIST_ACTIVE_3" 4 "DIST_ACTIVE_2" 3 "DIST_ACTIVE_1_Closest" 2 "DIST_ACTIVE_No_Target" 1 "DIST_STANDBY" 0 "DIST_OFF" ;
VAL_ 394 AccStopRes_B_Dsply 1 "Yes" 0 "No" ;
VAL_ 394 TjaWarn_D_Rq 7 "HardTakeOverEyesOff" 6 "SoftTakeOverEyesOff" 5 "HaLaneDeptWarningLeft" 4 "HaLaneDeptWarningRight" 3 "HardTakeOverLevel2" 2 "HardTakeOverLevel1" 1 "TrafficJamAssistCancel" 0 "NoWarning" ;
VAL_ 394 Tja_D_Stat 7 "ExtendedActive" 6 "ActiveWarningRight" 5 "ActiveWarningLeft" 4 "ActiveInterventionRight" 3 "ActiveInterventionLeft" 2 "Active" 1 "Standby" 0 "Off" ;
VAL_ 394 TjaMsgTxt_D_Dsply 7 "Disclaimer" 6 "SmartOffering" 5 "HaSelected" 4 "HaUnavailable" 3 "TurnOnAdaptCruiseControl" 2 "TrafficJamAssistSelected" 1 "TrafficJamAssistUnavailabl" 0 "NoMessage" ;
VAL_ 394 IaccLamp_D_Rq 3 "NotUsed_2" 2 "NotUsed_1" 1 "DisplayIaccIcon" 0 "DoNotDisplayIaccIcon" ;
VAL_ 394 AccMsgTxt_D2_Rq 15 "Brakes_Warm" 14 "NCC_Enabled_Warning" 13 "IACC_TJA_Selected" 12 "ACC_TJA_Selected" 11 "IACC_Selected" 10 "Press_Brake_To_Hold" 9 "Only_Following_In_Low_Spd" 8 "TJA_Unavailable" 7 "Shift_Down" 6 "IACC_Unavailable" 5 "ACC_Selected" 4 "ACC_Overridden" 3 "Brake_Capacity_Warning" 2 "ACC_Cancelled" 1 "ACC_Unavailable" 0 "No_Text" ;
VAL_ 394 FcwDeny_B_Dsply 1 "Yes" 0 "No" ;
VAL_ 394 FcwMemStat_B_Actl 1 "On" 0 "Off" ;
VAL_ 394 AccTGap_B_Dsply 1 "Yes" 0 "No" ;
VAL_ 394 CadsAlignIncplt_B_Actl 1 "Yes" 0 "No" ;
VAL_ 394 AccFllwMde_B_Dsply 1 "Yes" 0 "No" ;
VAL_ 394 CadsRadrBlck_B_Actl 1 "Yes" 0 "No" ;
VAL_ 394 CmbbPostEvnt_B_Dsply 1 "Yes" 0 "No" ;
VAL_ 394 AccStopMde_B_Dsply 1 "Yes" 0 "No" ;
VAL_ 394 FcwMemSens_D_Actl 3 "FCW_Sensitivity_3" 2 "FCW_Sensitivity_2" 1 "FCW_Sensitivity_1" 0 "Not_Used" ;
VAL_ 394 FcwMsgTxt_D_Rq 7 "Undefined_3" 6 "Undefined_2" 5 "Low_Visibility" 4 "Unavailable_DueTo_LowSpeed" 3 "Available" 2 "Unavailable" 1 "Off" 0 "No_Text" ;
VAL_ 394 AccWarn_D_Dsply 3 "BrakeReleaseWarn_In_StopMd" 2 "Brake_Capacity_Warning" 1 "Cancel_Warning" 0 "No_Warning" ;
VAL_ 394 FcwVisblWarn_B_Rq 1 "On" 0 "Off" ;
VAL_ 394 FcwAudioWarn_B_Rq 1 "On" 0 "Off" ;
VAL_ 394 AccTGap_D_Dsply 7 "Undefined_2" 6 "Undefined_1" 5 "Time_Gap_5" 4 "Time_Gap_4" 3 "Time_Gap_3" 2 "Time_Gap_2" 1 "Time_Gap_1" 0 "Not_Used" ;
VAL_ 394 AccMemEnbl_B_RqDrv 1 "Adaptive_Cruise" 0 "Normal_Cruise" ;
VAL_ 394 AccStopStat_D_Dsply 3 "PressResume" 2 "Stopped" 1 "ResumeReady" 0 "NoDisplay" ;
VAL_ 391 HudBlk3_B_Rq 1 "Yes" 0 "No" ;
VAL_ 391 HudBlk2_B_Rq 1 "Yes" 0 "No" ;
VAL_ 391 HudBlk1_B_Rq 1 "Yes" 0 "No" ;
VAL_ 391 HudFlashRate_D_Actl 3 "Unused" 2 "Flash_4Hz_50Prct_DutyCycle" 1 "On" 0 "Off" ;
VAL_ 391 CmbbBrkPrchg_D_Rq 3 "Undefined" 2 "Level_2_PreCharge_Request" 1 "Level_1_PreCharge_Request" 0 "No_PreCharge_Request" ;
VAL_ 391 CmbbBrkDecel_B_Rq 1 "Yes" 0 "No" ;
VAL_ 391 CmbbBaSens_D_Rq 3 "Level_3" 2 "Level_2" 1 "Level_1" 0 "Normal" ;
VAL_ 390 AccBrkPrkEl_B_Rq 1 "Yes" 0 "No" ;
VAL_ 390 Cmbb_B_Enbl 1 "Yes" 0 "No" ;
VAL_ 390 CmbbOvrrd_B_RqDrv 1 "Yes" 0 "No" ;
VAL_ 390 CmbbDeny_B_Actl 1 "Yes" 0 "No" ;
VAL_ 390 CmbbEngTqMn_B_Rq 1 "Yes" 0 "No" ;
VAL_ 390 AccDeny_B_Rq 1 "Yes" 0 "No" ;
VAL_ 390 AccResumEnbl_B_Rq 1 "Yes" 0 "No" ;
VAL_ 390 AccCancl_B_Rq 1 "Yes" 0 "No" ;
VAL_ 390 AccBrkPrchg_B_Rq 1 "Yes" 0 "No" ;
VAL_ 390 AccBrkDecel_B_Rq 1 "Active" 0 "Inactive" ;
VAL_ 390 AccStopStat_B_Rq 1 "Yes" 0 "No" ;
VAL_ 390 AccAutoResum_D_Rq 3 "NotUsed" 2 "Active" 1 "Pending" 0 "Off" ;
VAL_ 390 AccBrkPulse_B_Rq 1 "True" 0 "False" ;
VAL_ 1186 AwdDrvMde_D2_Stat 15 "Faulty" 14 "NotUsed_7" 13 "NotUsed_6" 12 "NotUsed_5" 11 "NotUsed_4" 10 "NotUsed_3" 9 "NotUsed_2" 8 "NotUsed_1" 7 "NotAvailable" 6 "TowHaul" 5 "RockCrawl" 4 "Baja" 3 "MudAndSand" 2 "Weather" 1 "Sport" 0 "Normal" ;
VAL_ 1186 FrontDiffLckMsg_D_Rq 7 "LockerDisabled" 6 "LockerEnabled" 5 "LockerAccelPedal" 4 "Speed4" 3 "Speed3" 2 "Speed2" 1 "Speed1" 0 "NormalNoMessage" ;
VAL_ 1186 SelDrvMdeAwd2_D_Stat 31 "Faulty" 30 "NotUsed_17" 29 "NotUsed_16" 28 "NotUsed_15" 27 "NotUsed_14" 26 "NotUsed_13" 25 "NotUsed_12" 24 "NotUsed_11" 23 "NotUsed_10" 22 "NotUsed_9" 21 "NotUsed_8" 20 "CustomMode" 19 "OnePedalDrive" 18 "DragMode" 17 "EvLaterChargeMode" 16 "EvNowMode" 15 "TrackMode" 14 "RoughRoadMode" 13 "NotAvailable" 12 "HighSpeedDesertMode_Baja" 11 "SportAdaptiveMode" 10 "RockCrawlMode" 9 "MudRutsMode" 8 "SandMode" 7 "EconomyMode" 6 "GrassGravelSnow" 5 "TowHaulMode" 4 "SportMode" 3 "Normal_4L" 2 "Normal_4A" 1 "Normal_2H" 0 "NormalMode" ;
VAL_ 1186 RearDiffLckMsg_D_Rq 7 "Locker_Disabled" 6 "Locker_Enabled" 5 "Locker_Accel_Pedal" 4 "Speed4" 3 "Speed3" 2 "Spee2" 1 "Speed1" 0 "Normal__No_Message " ;
VAL_ 1186 RearDiffLck_Tq_Actl 4095 "Fault" 4094 "Unknown" ;
VAL_ 1186 RearDiffFalt_D_Stat 3 "Diff_Failed_Closed" 2 "Diff_Failed_Open" 1 "Fault_Non_Specific" 0 "No_Fault" ;
VAL_ 1186 LsdSrvcRqd_B_Rq 1 "On" 0 "Off" ;
VAL_ 1186 AwdStat2_D_RqDsply 31 "NotUsed_29" 30 "NotUsed_28" 29 "NotUsed_27" 28 "NotUsed_26" 27 "NotUsed_25" 26 "NotUsed_24" 25 "NotUsed_23" 24 "NotUsed_22" 23 "NotUsed_21" 22 "NotUsed_20" 21 "NotUsed_19" 20 "NotUsed_18" 19 "NotUsed_17" 18 "NotUsed_16" 17 "NotUsed_15" 16 "NotUsed_14" 15 "NotUsed_13" 14 "NotUsed_12" 13 "NotUsed_11" 12 "NotUsed_10" 11 "NotUsed_9" 10 "NotUsed_8" 9 "NotUsed_7" 8 "NotUsed_6" 7 "NotUsed_5" 6 "NotUsed_4" 5 "Unavailable4x4Mode" 4 "UnavailableDriveMode" 3 "HillHoldFail" 2 "TCaseOilChanged" 1 "ChangeTCaseOil" 0 "Normal" ;
VAL_ 1186 FrontDiffFalt_D_Stat 3 "Diff_Failed_Closed" 2 "Diff_Failed_Open" 1 "Fault_Non_Specific" 0 "No_Fault" ;
VAL_ 1186 FrontDiffLck_Tq_Actl 16383 "Faulty" 16382 "NoDataExists" ;
VAL_ 1186 FrontDiffLckLamp_D_Rq 3 "Triggered" 2 "Flash" 1 "On" 0 "Off" ;
VAL_ 1186 RearDiffLckLamp_D_Rq 3 "Not_Used" 2 "Flash" 1 "On" 0 "Off" ;
